VERSION ""

NS_ :

BS_:

BU_: VMCU TECU TACHO RECU_Virt IC3 HPCU EMS EBS DACU CIOM BBM ACM

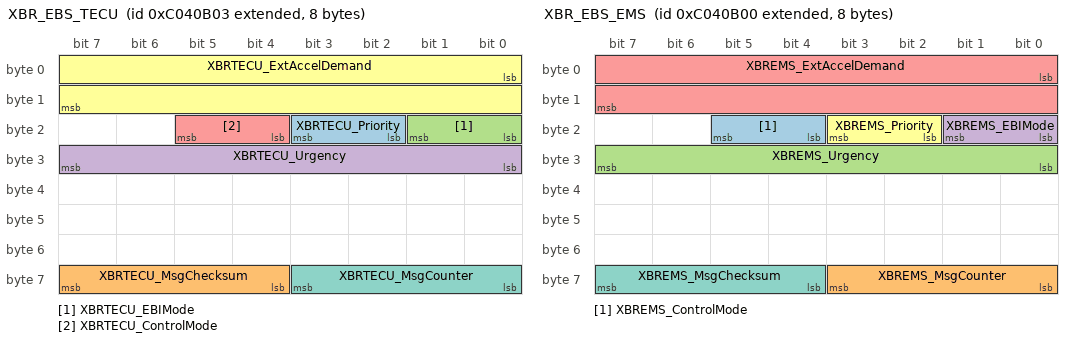
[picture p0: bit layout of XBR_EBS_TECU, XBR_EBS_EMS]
BO_ 2349075203 XBR_EBS_TECU: 8 TECU
 SG_ XBRTECU_Priority : 18|2@1+ (1,0) [0|0] ""  EBS,VMCU
 SG_ XBRTECU_MsgChecksum : 60|4@1+ (1,0) [0|15] "Count"  VMCU,EBS
 SG_ XBRTECU_EBIMode : 16|2@1+ (1,0) [0|0] ""  EBS,VMCU
 SG_ XBRTECU_Urgency : 24|8@1+ (0.4,0) [0|102] "Percent"  EBS,VMCU
 SG_ XBRTECU_ControlMode : 20|2@1+ (1,0) [0|0] ""  EBS,VMCU
 SG_ XBRTECU_ExtAccelDemand : 0|16@1+ (0.00048828125,-15.687) [-15.687|16.31251171875] "m_per_s_squared"  VMCU,EBS
 SG_ XBRTECU_MsgCounter : 56|4@1+ (1,0) [0|15] "Count"  EBS,VMCU

BO_ 2349075200 XBR_EBS_EMS: 8 EMS
 SG_ XBREMS_ControlMode : 20|2@1+ (1,0) [0|0] ""  EBS,VMCU
 SG_ XBREMS_MsgCounter : 56|4@1+ (1,0) [0|15] "Count"  EBS,VMCU
 SG_ XBREMS_Urgency : 24|8@1+ (0.4,0) [0|102] "Percent"  EBS,VMCU
 SG_ XBREMS_EBIMode : 16|2@1+ (1,0) [0|0] ""  EBS,VMCU
 SG_ XBREMS_ExtAccelDemand : 0|16@1+ (0.00048828125,-15.687) [-15.687|16.31251171875] "m_per_s_squared"  VMCU,EBS
 SG_ XBREMS_Priority : 18|2@1+ (1,0) [0|0] ""  EBS,VMCU
 SG_ XBREMS_MsgChecksum : 60|4@1+ (1,0) [0|15] "Count"  EBS,VMCU

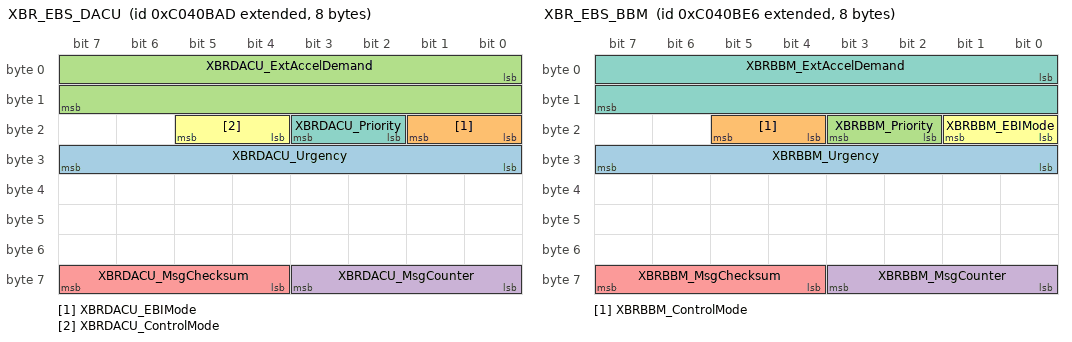
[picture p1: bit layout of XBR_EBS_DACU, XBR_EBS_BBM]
BO_ 2349075373 XBR_EBS_DACU: 8 DACU
 SG_ XBRDACU_Urgency : 24|8@1+ (0.4,0) [0|102] "Percent"  EBS,VMCU,TECU
 SG_ XBRDACU_EBIMode : 16|2@1+ (1,0) [0|0] ""  VMCU,EBS,TECU
 SG_ XBRDACU_ExtAccelDemand : 0|16@1+ (0.00048828125,-15.687) [-15.687|16.31251171875] "m_per_s_squared"  EBS,TECU,VMCU
 SG_ XBRDACU_MsgCounter : 56|4@1+ (1,0) [0|15] "Count"  VMCU,TECU,EBS
 SG_ XBRDACU_MsgChecksum : 60|4@1+ (1,0) [0|15] "Count"  TECU,VMCU,EBS
 SG_ XBRDACU_ControlMode : 20|2@1+ (1,0) [0|0] ""  TECU,EBS,VMCU
 SG_ XBRDACU_Priority : 18|2@1+ (1,0) [0|0] ""  EBS,TECU,VMCU

BO_ 2349075430 XBR_EBS_BBM: 8 BBM
 SG_ XBRBBM_Urgency : 24|8@1+ (0.4,0) [0|102] "Percent"  EBS,VMCU
 SG_ XBRBBM_ControlMode : 20|2@1+ (1,0) [0|0] ""  EBS,VMCU
 SG_ XBRBBM_Priority : 18|2@1+ (1,0) [0|0] ""  VMCU,EBS
 SG_ XBRBBM_MsgCounter : 56|4@1+ (1,0) [0|15] "Count"  VMCU,EBS
 SG_ XBRBBM_MsgChecksum : 60|4@1+ (1,0) [0|15] "Count"  VMCU,EBS
 SG_ XBRBBM_EBIMode : 16|2@1+ (1,0) [0|0] ""  EBS,VMCU
 SG_ XBRBBM_ExtAccelDemand : 0|16@1+ (0.00048828125,-15.687) [-15.687|16.31251171875] "m_per_s_squared"  VMCU,EBS

BO_ 2566848256 WFI_X_EMS: 8 EMS
 SG_ WaterInFuelAlarm_ISig_3 : 0|2@1+ (1,0) [0|0] ""  BBM,IC3

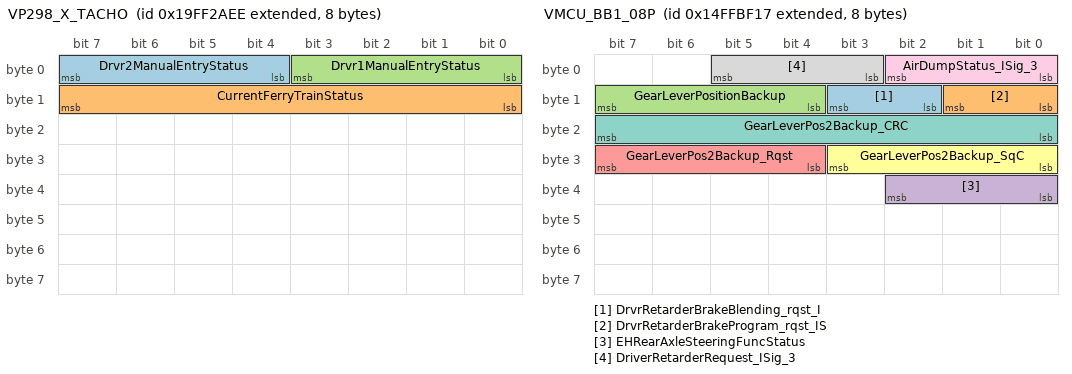
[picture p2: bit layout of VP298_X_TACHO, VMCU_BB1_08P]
BO_ 2583636718 VP298_X_TACHO: 8 TACHO
 SG_ Drvr2ManualEntryStatus : 4|4@1+ (1,0) [0|0] ""  IC3
 SG_ CurrentFerryTrainStatus : 8|8@1+ (1,0) [0|0] ""  IC3
 SG_ Drvr1ManualEntryStatus : 0|4@1+ (1,0) [0|0] ""  IC3

BO_ 2583635694 VP294_X_TACHO: 8 TACHO
 SG_ GNSSTime_Tacho : 0|32@1+ (1,0) [0|4294967295] "s"  VMCU
 SG_ GNSSLiveStatus_Tacho : 32|8@1+ (1,0) [0|255] "NotApplicable"  VMCU

BO_ 2566845201 VP1_X_VMCU: 8 VMCU
 SG_ VehiclePosSAE_Longitude : 32|32@1+ (1E-007,-210) [-210|219.4967295] "deg"  TECU
 SG_ VehiclePosSAE_Latitude : 0|32@1+ (1E-007,-210) [-210|219.4967295] "deg"  TECU

BO_ 2566845422 VP1_X_TACHO: 8 TACHO
 SG_ VehPos1_Latitude : 0|32@1+ (1E-007,-210) [-210|219.4967295] "deg"  VMCU
 SG_ VehPos1_Longitude : 32|32@1+ (1E-007,-210) [-210|219.4967295] "deg"  VMCU

BO_ 2566901009 VMCU_BB1_09P: 8 VMCU
 SG_ LNGConsumedPTO : 0|32@1+ (0.01,0) [0|42949672.95] "kg"  IC3
 SG_ EngTrueIdleSpeedLNG : 32|32@1+ (0.01,0) [0|42949672.95] "kg"  IC3

BO_ 2499788567 VMCU_BB1_08P: 8 VMCU
 SG_ DrvrRetarderBrakeBlending_rqst_I : 10|2@1+ (1,0) [0|0] ""  TECU,BBM,EBS,IC3
 SG_ DrvrRetarderBrakeProgram_rqst_IS : 8|2@1+ (1,0) [0|0] ""  IC3,TECU,BBM
 SG_ GearLeverPositionBackup : 12|4@1+ (1,0) [0|0] ""  TECU
 SG_ EHRearAxleSteeringFuncStatus : 32|3@1+ (1,0) [0|0] ""  CIOM
 SG_ GearLeverPos2Backup_Rqst : 28|4@1+ (1,0) [0|0] ""  TECU
 SG_ GearLeverPos2Backup_SqC : 24|4@1+ (1,0) [0|0] ""  TECU
 SG_ GearLeverPos2Backup_CRC : 16|8@1+ (1,0) [0|255] ""  TECU
 SG_ DriverRetarderRequest_ISig_3 : 3|3@1+ (1,0) [0|0] ""  EBS,TECU,EMS,IC3,BBM,RECU_Virt
 SG_ AirDumpStatus_ISig_3 : 0|3@1+ (1,0) [0|0] ""  BBM

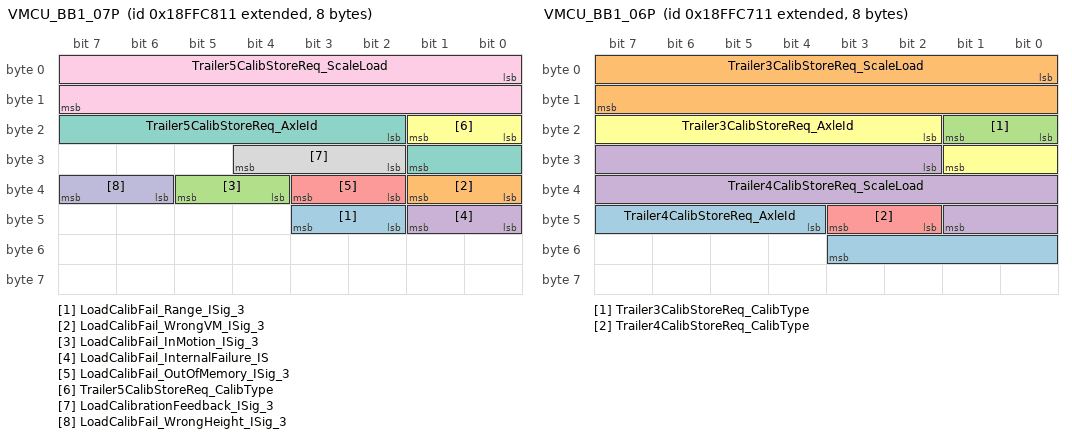
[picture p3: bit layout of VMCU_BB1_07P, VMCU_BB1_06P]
BO_ 2566899729 VMCU_BB1_07P: 8 VMCU
 SG_ LoadCalibFail_Range_ISig_3 : 42|2@1+ (1,0) [0|0] ""  IC3
 SG_ LoadCalibFail_WrongVM_ISig_3 : 32|2@1+ (1,0) [0|0] ""  IC3
 SG_ LoadCalibFail_InMotion_ISig_3 : 36|2@1+ (1,0) [0|0] ""  IC3
 SG_ LoadCalibFail_InternalFailure_IS : 40|2@1+ (1,0) [0|0] ""  IC3
 SG_ LoadCalibFail_OutOfMemory_ISig_3 : 34|2@1+ (1,0) [0|0] ""  IC3
 SG_ Trailer5CalibStoreReq_CalibType : 16|2@1+ (1,0) [0|0] ""  EBS
 SG_ Trailer5CalibStoreReq_AxleId : 18|8@1+ (1,0) [0|255] "NotApplicable"  EBS
 SG_ LoadCalibrationFeedback_ISig_3 : 26|3@1+ (1,0) [0|0] ""  IC3
 SG_ Trailer5CalibStoreReq_ScaleLoad : 0|16@1+ (1,0) [0|65535] "kg"  EBS
 SG_ LoadCalibFail_WrongHeight_ISig_3 : 38|2@1+ (1,0) [0|0] ""  IC3

BO_ 2566899473 VMCU_BB1_06P: 8 VMCU
 SG_ Trailer4CalibStoreReq_AxleId : 44|8@1+ (1,0) [0|255] "NotApplicable"  EBS
 SG_ Trailer3CalibStoreReq_ScaleLoad : 0|16@1+ (1,0) [0|65535] "kg"  EBS
 SG_ Trailer3CalibStoreReq_CalibType : 16|2@1+ (1,0) [0|0] ""  EBS
 SG_ Trailer4CalibStoreReq_ScaleLoad : 26|16@1+ (1,0) [0|65535] "kg"  EBS
 SG_ Trailer4CalibStoreReq_CalibType : 42|2@1+ (1,0) [0|0] ""  EBS
 SG_ Trailer3CalibStoreReq_AxleId : 18|8@1+ (1,0) [0|255] "NotApplicable"  EBS

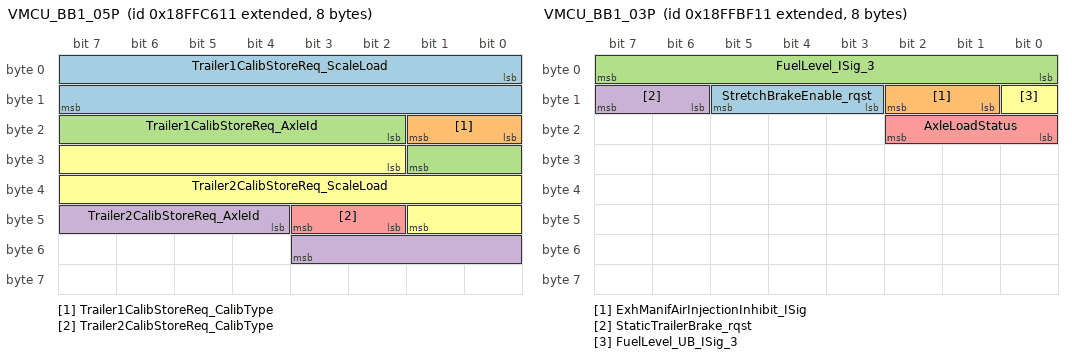
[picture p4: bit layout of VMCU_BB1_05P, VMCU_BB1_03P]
BO_ 2566899217 VMCU_BB1_05P: 8 VMCU
 SG_ Trailer1CalibStoreReq_ScaleLoad : 0|16@1+ (1,0) [0|65535] "kg"  EBS
 SG_ Trailer1CalibStoreReq_CalibType : 16|2@1+ (1,0) [0|0] ""  EBS
 SG_ Trailer1CalibStoreReq_AxleId : 18|8@1+ (1,0) [0|255] "NotApplicable"  EBS
 SG_ Trailer2CalibStoreReq_AxleId : 44|8@1+ (1,0) [0|255] "NotApplicable"  EBS
 SG_ Trailer2CalibStoreReq_CalibType : 42|2@1+ (1,0) [0|0] ""  EBS
 SG_ Trailer2CalibStoreReq_ScaleLoad : 26|16@1+ (1,0) [0|65535] "kg"  EBS

BO_ 2499751697 VMCU_BB1_04P: 8 VMCU
 SG_ TrailerConnected_UB_ISig_3 : 23|1@1+ (1,0) [0|0] ""  EBS
 SG_ RearAxle2DiffLock_stat_ISig_3 : 2|2@1+ (1,0) [0|0] ""  BBM,TECU,IC3
 SG_ EngineStopReqBackup : 12|2@1+ (1,0) [0|0] ""  EMS
 SG_ DifferentialLockStateCentral_ISi : 6|2@1+ (1,0) [0|0] ""  BBM,TECU,EBS,IC3,EMS
 SG_ RearAxle2DiffLock_stat_UB_ISig_3 : 17|1@1+ (1,0) [0|0] ""  BBM,TECU,IC3
 SG_ RrInterAxlDiffLockActvnFuncReq_I : 46|2@1+ (1,0) [0|0] ""  IC3
 SG_ RearPropulsionStat_Rear1Axle_ISi : 24|4@1+ (1,0) [0|0] ""  IC3,EBS,EMS,TECU,BBM,DACU
 SG_ SetHSAOperation : 40|3@1+ (1,0) [0|0] ""  IC3,EBS
 SG_ CentralRearDiffLock_stat_ISig_3 : 4|2@1+ (1,0) [0|0] ""  IC3,TECU,BBM
 SG_ AutoPBRelease_stat_ISig_3 : 36|2@1+ (1,0) [0|0] ""  IC3
 SG_ RearAxle3DiffLock_stat_ISig_3 : 50|2@1+ (1,0) [0|0] ""  IC3
 SG_ DifferentialLockStateCentral2 : 48|2@1+ (1,0) [0|0] ""  EBS
 SG_ LowAirPressureAlert : 10|2@1+ (1,0) [0|0] ""  IC3,EMS
 SG_ RearPropulsionStat_Rear3Axle_ISi : 32|4@1+ (1,0) [0|0] ""  DACU,IC3,EMS,BBM,EBS,TECU
 SG_ RearAxle3DiffLock_stat_UB_ISig_3 : 52|1@1+ (1,0) [0|0] ""  IC3
 SG_ DifferentialLockStateFrAxle2 : 38|2@1+ (1,0) [0|0] ""  EBS
 SG_ TrailerConnected_ISig_3 : 21|2@1+ (1,0) [0|0] ""  EBS
 SG_ TrailerWithoutABS_ISig_3 : 18|2@1+ (1,0) [0|0] ""  TECU,EMS,DACU,EBS,IC3
 SG_ DifferentialLockStateFrAxle1_UB_ : 14|1@1+ (1,0) [0|0] ""  BBM,EBS,IC3
 SG_ DifferentialLockStateFrAxle1_ISi : 8|2@1+ (1,0) [0|0] ""  EBS,IC3,BBM
 SG_ RearAxle1DiffLock_stat_UB_ISig_3 : 16|1@1+ (1,0) [0|0] ""  BBM,TECU,IC3
 SG_ RearPropulsionStat_Rear2Axle_ISi : 28|4@1+ (1,0) [0|0] ""  EBS,BBM,EMS,IC3,DACU,TECU
 SG_ CentralRearDiffLock_stat_UB_ISig : 15|1@1+ (1,0) [0|0] ""  IC3,BBM,TECU
 SG_ RearAxle1DiffLock_stat_ISig_3 : 0|2@1+ (1,0) [0|0] ""  IC3,BBM,TECU
 SG_ HeadlampFan_stat_ISig_3 : 43|3@1+ (1,0) [0|0] ""  IC3
 SG_ TrailerWithoutABS_UB_ISig_3 : 20|1@1+ (1,0) [0|0] ""  TECU,DACU,EBS,EMS,IC3

BO_ 2566897425 VMCU_BB1_03P: 8 VMCU
 SG_ StretchBrakeEnable_rqst : 11|3@1+ (1,0) [0|0] ""  EBS
 SG_ ExhManifAirInjectionInhibit_ISig : 9|2@1+ (1,0) [0|0] ""  EMS
 SG_ FuelLevel_ISig_3 : 0|8@1+ (0.4,0) [0|102] "Percent"  IC3,BBM,CIOM,EMS
 SG_ StaticTrailerBrake_rqst : 14|2@1+ (1,0) [0|0] ""  EBS
 SG_ AxleLoadStatus : 16|3@1+ (1,0) [0|0] ""  IC3,TECU,EBS
 SG_ FuelLevel_UB_ISig_3 : 8|1@1+ (1,0) [0|0] ""  BBM,IC3,CIOM,EMS

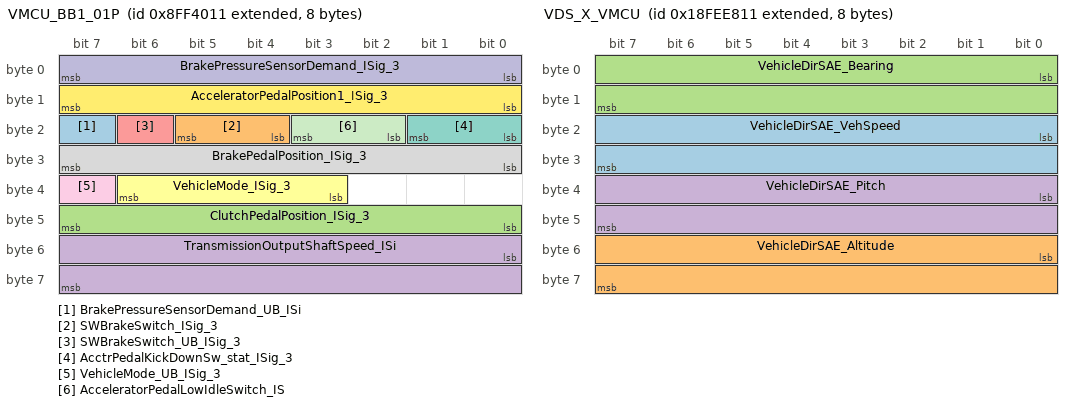
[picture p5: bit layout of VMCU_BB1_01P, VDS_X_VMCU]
BO_ 2298429457 VMCU_BB1_01P: 8 VMCU
 SG_ BrakePressureSensorDemand_UB_ISi : 23|1@1+ (1,0) [0|0] ""  EBS
 SG_ SWBrakeSwitch_ISig_3 : 20|2@1+ (1,0) [0|0] ""  IC3,EBS
 SG_ ClutchPedalPosition_ISig_3 : 40|8@1+ (0.4,0) [0|102] "Percent"  EBS
 SG_ TransmissionOutputShaftSpeed_ISi : 48|16@1+ (0.125,0) [0|8191.875] "rpm"  RECU_Virt,EMS,BBM
 SG_ SWBrakeSwitch_UB_ISig_3 : 22|1@1+ (1,0) [0|0] ""  IC3,EBS
 SG_ VehicleMode_ISig_3 : 35|4@1+ (1,0) [0|0] ""  ACM,IC3,CIOM,DACU,HPCU,TECU,TACHO,EMS,BBM,EBS
 SG_ AcctrPedalKickDownSw_stat_ISig_3 : 16|2@1+ (1,0) [0|0] ""  BBM,TECU,IC3,EMS,DACU
 SG_ BrakePedalPosition_ISig_3 : 24|8@1+ (0.4,0) [0|102] "Percent"  IC3,TECU,EBS,CIOM,DACU,BBM
 SG_ VehicleMode_UB_ISig_3 : 39|1@1+ (1,0) [0|0] ""  HPCU,EMS,CIOM,IC3,DACU,TECU,ACM,TACHO,BBM,EBS
 SG_ BrakePressureSensorDemand_ISig_3 : 0|8@1+ (1,0) [0|255] "Percent"  EBS
 SG_ AcceleratorPedalLowIdleSwitch_IS : 18|2@1+ (1,0) [0|0] ""  IC3,BBM,TECU
 SG_ AcceleratorPedalPosition1_ISig_3 : 8|8@1+ (0.4,0) [0|102] "Percent"  EMS,BBM,DACU,EBS,IC3,TECU,CIOM

BO_ 2566842385 VDS_X_VMCU: 8 VMCU
 SG_ VehicleDirSAE_VehSpeed : 16|16@1+ (0.00390625,0) [0|255.99609375] "Km_per_h"  TECU
 SG_ VehicleDirSAE_Altitude : 48|16@1+ (0.125,-2500) [-2500|5691.875] "m"  TECU
 SG_ VehicleDirSAE_Bearing : 0|16@1+ (0.0078125,0) [0|511.9921875] "deg"  TECU
 SG_ VehicleDirSAE_Pitch : 32|16@1+ (0.0078125,-200) [-200|311.9921875] "deg"  TECU

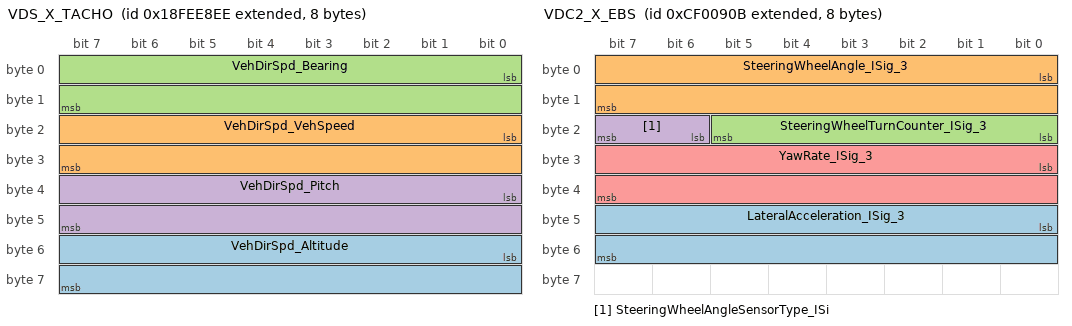
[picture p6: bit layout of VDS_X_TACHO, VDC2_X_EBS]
BO_ 2566842606 VDS_X_TACHO: 8 TACHO
 SG_ VehDirSpd_Altitude : 48|16@1+ (0.125,-2500) [-2500|5691.875] "m"  VMCU
 SG_ VehDirSpd_VehSpeed : 16|16@1+ (0.00390625,0) [0|255.99609375] "Km_per_h"  VMCU
 SG_ VehDirSpd_Bearing : 0|16@1+ (0.0078125,0) [0|511.9921875] "deg"  VMCU
 SG_ VehDirSpd_Pitch : 32|16@1+ (0.0078125,-200) [-200|311.9921875] "deg"  VMCU

BO_ 2566849262 VDO2_X_TACHO: 32 TACHO
 SG_ DurationOfCurrentDailyRest_ISig_ : 80|16@1+ (1,0) [0|65535] "min"  IC3
 SG_ DetectReducWeeklyRestsForCurWk_I : 116|4@1+ (1,0) [0|0] ""  IC3
 SG_ CurrentWeekWorkTime_ISig_3 : 144|16@1+ (1,0) [0|65535] "min"  IC3
 SG_ DetectRegWeeklyRestsForCurWk_ISi : 112|4@1+ (1,0) [0|0] ""  IC3
 SG_ Drv1CumulativeBreakTime_VDO2_ISi : 64|16@1+ (1,0) [0|65535] "min"  IC3
 SG_ Drv1ContinuousDrivingTime_VDO2_I : 0|16@1+ (1,0) [0|65535] "min"  IC3
 SG_ DailyDrivingTime_VDO2_ISig_3 : 16|16@1+ (1,0) [0|65535] "min"  IC3
 SG_ DetectReducWeeklyRestsForLastW_I : 124|4@1+ (1,0) [0|0] ""  IC3
 SG_ TwoWeekDrvingTime_VDO2_ISig_3 : 32|16@1+ (1,0) [0|65535] "min"  IC3
 SG_ CurrentDailyWorkTime_ISig_3 : 128|16@1+ (1,0) [0|65535] "min"  IC3
 SG_ DetectRegWeeklyRestsForLastW_ISi : 120|4@1+ (1,0) [0|0] ""  IC3
 SG_ WeeklyDrivingTime_VDO2_ISig_3 : 48|16@1+ (1,0) [0|65535] "min"  IC3
 SG_ DurationOfCurrentWeeklyRest_ISig : 96|16@1+ (1,0) [0|65535] "min"  IC3

BO_ 2566906094 VDO1prop_X_TACHO: 32 TACHO
 SG_ RemningTimeTillNxtWklyRestPrd_IS : 160|16@1+ (1,0) [0|65535] "min"  IC3
 SG_ RemainingCurDailyDrivingTime_ISi : 96|16@1+ (1,0) [0|65535] "min"  IC3
 SG_ RemainingCurrentDrivingTime_ISig : 0|16@1+ (1,0) [0|65535] "min"  IC3
 SG_ SingleMultiDriver_ISig_3 : 252|2@1+ (1,0) [0|0] ""  IC3
 SG_ UnknownPeriods_ISig_3 : 246|2@1+ (1,0) [0|0] ""  IC3
 SG_ OpenCompensationWeekBfrLast_ISig : 208|16@1+ (1,0) [0|65535] "min"  IC3
 SG_ RemainingReducedDailyRestPrd_ISi : 243|3@1+ (1,0) [0|0] ""  IC3
 SG_ RemainingDurOfCurBreakRest_ISig_ : 48|16@1+ (1,0) [0|65535] "min"  IC3
 SG_ RemainingTimeTillNextRestBreak_I : 16|16@1+ (1,0) [0|65535] "min"  IC3
 SG_ NextDrivingPeriod_ISig_3 : 80|16@1+ (1,0) [0|65535] "min"  IC3
 SG_ DurationOfNextRestBreak_ISig_3 : 32|16@1+ (1,0) [0|65535] "min"  IC3
 SG_ RemainingDrivTimeOfCurWeek_ISig_ : 144|16@1+ (1,0) [0|65535] "min"  IC3
 SG_ DurationOfNextDailyRestPeriod_IS : 128|16@1+ (1,0) [0|65535] "min"  IC3
 SG_ OpenCompensationInTheLastWeek_IS : 192|16@1+ (1,0) [0|65535] "min"  IC3
 SG_ TimeOverlap_ISig_3 : 254|2@1+ (1,0) [0|0] ""  IC3
 SG_ TimeBeforeStartOfNxtDrvngPrd_ISi : 64|16@1+ (1,0) [0|65535] "min"  IC3
 SG_ WklyRestPrdCalcEnabledDisabled_I : 250|2@1+ (1,0) [0|0] ""  IC3
 SG_ Remaining10hDrvTime_ISig_3 : 240|3@1+ (1,0) [0|0] ""  IC3
 SG_ RemnngTimeTillNxtDailyRestPrd_IS : 112|16@1+ (1,0) [0|65535] "min"  IC3
 SG_ DurationOfNextWeeklyRestPeriod_I : 176|16@1+ (1,0) [0|65535] "min"  IC3
 SG_ OpenCompensation2ndWeekBfrLast_I : 224|16@1+ (1,0) [0|65535] "min"  IC3
 SG_ SufficientData_ISig_3 : 248|2@1+ (1,0) [0|0] ""  IC3

BO_ 2566849006 VDO1Extended_X_TACHO: 16 TACHO
 SG_ TypeOfNextBreakRest_ISig_3 : 16|6@1+ (1,0) [0|0] ""  IC3
 SG_ CompensationinNextRestPrd_ISig_3 : 22|2@1+ (1,0) [0|0] ""  IC3
 SG_ RemDrvTimeTillNxtWklyRestPrd_ISi : 0|16@1+ (1,0) [0|65535] "min"  IC3

BO_ 2566832401 VDHR_X_VMCU: 8 VMCU
 SG_ TotalVehicleDistanceHighRes_ISig : 0|32@1+ (5,0) [0|21474836475] "m"  IC3,EBS,EMS,ACM,DACU,TECU,CIOM,BBM

BO_ 2566832622 VDHR_X_TACHO: 8 TACHO
 SG_ TachoHighResTotalVehDistance : 0|32@1+ (5,0) [0|21474836475] "m"  VMCU

BO_ 2566832407 VDHR_X_IC3: 8 IC3
 SG_ HighResolutionTripDistance_ISig_ : 32|32@1+ (5,0) [0|21474836475] "m"  BBM

BO_ 2364541195 VDC2_X_EBS: 8 EBS
 SG_ LateralAcceleration_ISig_3 : 40|16@1+ (0.00048828125,-15.687) [-15.687|16.31251171875] "m_per_s_squared"  IC3,BBM,DACU
 SG_ SteeringWheelAngle_ISig_3 : 0|16@1+ (0.0009765625,-31.374) [-31.374|32.6250234375] "rad"  CIOM,BBM,IC3,VMCU,DACU
 SG_ SteeringWheelTurnCounter_ISig_3 : 16|6@1+ (1,-32) [-32|31] "turns"  BBM
 SG_ SteeringWheelAngleSensorType_ISi : 22|2@1+ (1,0) [0|0] ""  BBM
 SG_ YawRate_ISig_3 : 24|16@1+ (0.000122,-3.92) [-3.92|4.07527] "Rad_per_s"  IC3,TECU,BBM,DACU

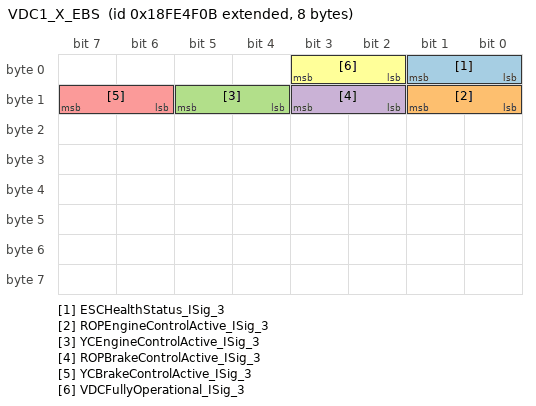
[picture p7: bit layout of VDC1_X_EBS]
BO_ 2566803211 VDC1_X_EBS: 8 EBS
 SG_ ESCHealthStatus_ISig_3 : 0|2@1+ (1,0) [0|0] ""  IC3,BBM
 SG_ ROPEngineControlActive_ISig_3 : 8|2@1+ (1,0) [0|0] ""  VMCU,IC3,BBM,TECU
 SG_ YCEngineControlActive_ISig_3 : 12|2@1+ (1,0) [0|0] ""  IC3,VMCU,BBM,TECU
 SG_ ROPBrakeControlActive_ISig_3 : 10|2@1+ (1,0) [0|0] ""  TECU,VMCU,CIOM,DACU,BBM,IC3
 SG_ YCBrakeControlActive_ISig_3 : 14|2@1+ (1,0) [0|0] ""  IC3,DACU,BBM,TECU,VMCU,CIOM
 SG_ VDCFullyOperational_ISig_3 : 2|2@1+ (1,0) [0|0] ""  BBM,DACU

BO_ 2675897544 TrailerDiagPhysRespMsg_F4_C8_BB1: 8 EBS
 SG_ TrailerDiagPhysResp_F4_C8_ISig_3 : 0|8@1- (1,0) [0|0] ""  IC3

BO_ 2675897536 TrailerDiagPhysRespMsg_F4_C0_BB1: 8 EBS
 SG_ TrailerDiagPhysResp_F4_C0_ISig_3 : 0|8@1- (1,0) [0|0] ""  IC3

BO_ 2675897528 TrailerDiagPhysRespMsg_F4_B8_BB1: 8 EBS
 SG_ TrailerDiagPhysResp_F4_B8_ISig_3 : 0|8@1- (1,0) [0|0] ""  IC3

BO_ 2675897520 TrailerDiagPhysRespMsg_F4_B0_BB1: 8 EBS
 SG_ TrailerDiagPhysResp_F4_B0_ISig_3 : 0|8@1- (1,0) [0|0] ""  IC3

BO_ 2675897512 TrailerDiagPhysRespMsg_F4_A8_BB1: 8 EBS
 SG_ TrailerDiagPhysResp_F4_A8_ISig_3 : 0|8@1- (1,0) [0|0] ""  IC3

BO_ 2675897032 TrailerDiagPhysRespMsg_F2_C8_BB1: 8 EBS
 SG_ TrailerDiagPhysResp_F2_C8_ISig_3 : 0|8@1- (1,0) [0|0] ""  VMCU

BO_ 2675897024 TrailerDiagPhysRespMsg_F2_C0_BB1: 8 EBS
 SG_ TrailerDiagPhysResp_F2_C0_ISig_3 : 0|8@1- (1,0) [0|0] ""  VMCU

CM_ "COM_MATRIX_T2_1.16.0";
CM_ BO_ 2349075203 "PGN 1024 External Brake Request";
CM_ SG_ 2349075203 XBRTECU_Urgency "254 Error ; 255 Not available";
CM_ SG_ 2349075203 XBRTECU_ExtAccelDemand "65024 - 65279 Error ; 65280 - 65535 Not available";
CM_ BO_ 2349075200 "PGN 1024 External Brake Request";
CM_ BO_ 2349075373 "PGN 1024 External Brake Request";
CM_ SG_ 2349075373 XBRDACU_Urgency "254 Error ; 255 Not available";
CM_ SG_ 2349075373 XBRDACU_ExtAccelDemand "65024 - 65279 Error ; 65280 - 65535 Not available";
CM_ BO_ 2349075430 "PGN 1024 External Brake Request";
CM_ SG_ 2349075430 XBRBBM_Urgency "254 Error ; 255 Not available";
CM_ SG_ 2349075430 XBRBBM_ExtAccelDemand "65024 - 65279 Error ; 65280 - 65535 Not available";
CM_ BO_ 2566848256 "PGN 65279 Water in Fuel Indicator";
CM_ BO_ 2566845201 "PGN 65267 Vehicle Position";
CM_ SG_ 2566897425 FuelLevel_ISig_3 "254 Error ; 255 Not available";
CM_ SG_ 2298429457 ClutchPedalPosition_ISig_3 "254 Error ; 255 Not available";
CM_ SG_ 2298429457 TransmissionOutputShaftSpeed_ISi "65024 - 65279 Error ; 65280 - 65535 Not available";
CM_ SG_ 2298429457 BrakePedalPosition_ISig_3 "254 Error ; 255 Not available";
CM_ SG_ 2298429457 BrakePressureSensorDemand_ISig_3 "254 Error ; 255 Not available";
CM_ SG_ 2298429457 AcceleratorPedalPosition1_ISig_3 "254 Error ; 255 Not available";
CM_ BO_ 2566842385 "PGN 65256 Vehicle Direction/Speed";
CM_ SG_ 2566906094 RemningTimeTillNxtWklyRestPrd_IS "65024 - 65279 Error ; 65280 - 65535 Not available";
CM_ SG_ 2566906094 RemainingCurDailyDrivingTime_ISi "65024 - 65279 Error ; 65280 - 65535 Not available";
CM_ SG_ 2566906094 RemainingCurrentDrivingTime_ISig "65024 - 65279 Error ; 65280 - 65535 Not available";
CM_ SG_ 2566906094 OpenCompensationWeekBfrLast_ISig "65024 - 65279 Error ; 65280 - 65535 Not available";
CM_ SG_ 2566906094 RemainingDurOfCurBreakRest_ISig_ "65024 - 65279 Error ; 65280 - 65535 Not available";
CM_ SG_ 2566906094 RemainingTimeTillNextRestBreak_I "65024 - 65279 Error ; 65280 - 65535 Not available";
CM_ SG_ 2566906094 NextDrivingPeriod_ISig_3 "65024 - 65279 Error ; 65280 - 65535 Not available";
CM_ SG_ 2566906094 DurationOfNextRestBreak_ISig_3 "65024 - 65279 Error ; 65280 - 65535 Not available";
CM_ SG_ 2566906094 RemainingDrivTimeOfCurWeek_ISig_ "65024 - 65279 Error ; 65280 - 65535 Not available";
CM_ SG_ 2566906094 DurationOfNextDailyRestPeriod_IS "65024 - 65279 Error ; 65280 - 65535 Not available";
CM_ SG_ 2566906094 OpenCompensationInTheLastWeek_IS "65024 - 65279 Error ; 65280 - 65535 Not available";
CM_ SG_ 2566906094 TimeBeforeStartOfNxtDrvngPrd_ISi "65024 - 65279 Error ; 65280 - 65535 Not available";
CM_ SG_ 2566906094 RemnngTimeTillNxtDailyRestPrd_IS "65024 - 65279 Error ; 65280 - 65535 Not available";
CM_ SG_ 2566906094 DurationOfNextWeeklyRestPeriod_I "65024 - 65279 Error ; 65280 - 65535 Not available";
CM_ SG_ 2566906094 OpenCompensation2ndWeekBfrLast_I "65024 - 65279 Error ; 65280 - 65535 Not available";
CM_ BO_ 2566832401 "PGN 65217 High Resolution Vehicle Distance";
CM_ SG_ 2566832401 TotalVehicleDistanceHighRes_ISig "4261412864 - 4278190079 Error ; 4278190080 - 4294967295 Not available";
CM_ BO_ 2566832622 "PGN 65217 High Resolution Vehicle Distance, From TACHO";
CM_ SG_ 2566832622 TachoHighResTotalVehDistance "4261412864 - 4278190079 Error ; 4278190080 - 4294967295 Not available";
CM_ BO_ 2364541195 "PGN 61449 Vehicle Dynamic Stability Control 2";
CM_ SG_ 2364541195 LateralAcceleration_ISig_3 "65024 - 65279 Error ; 65280 - 65535 Not available";
CM_ SG_ 2364541195 SteeringWheelAngle_ISig_3 "65024 - 65279 Error ; 65280 - 65535 Not available";
CM_ SG_ 2364541195 SteeringWheelTurnCounter_ISig_3 "62 Error; 63 Not available";
CM_ SG_ 2364541195 YawRate_ISig_3 "65024 - 65279 Error ; 65280 - 65535 Not available";
CM_ BO_ 2566803211 "PGN 65103 Vehicle Dynamic Stability Control 1";
BA_DEF_ BO_  "GenMsgStartDelayTime" INT 0 0;
BA_DEF_ BO_  "GenMsgDelayTime" INT 0 0;
BA_DEF_ BO_  "GenMsgNrOfRepetition" INT 0 0;
BA_DEF_ BO_  "GenMsgCycleTimeFast" INT 0 0;
BA_DEF_ BO_  "GenMsgCycleTime" INT 0 0;
BA_DEF_ BO_  "GenMsgSendType" ENUM  "Cyclic","NotUsed","NotUsed","NotUsed","NotUsed","NotUsed","NotUsed","IfActive","NoMsgSendType","NotUsed";
BA_DEF_ SG_  "GenSigStartValue" INT 0 0;
BA_DEF_ SG_  "GenSigCycleTimeActive" INT 0 0;
BA_DEF_ SG_  "GenSigCycleTime" INT 0 0;
BA_DEF_ SG_  "GenSigSendType" ENUM  "Cyclic","OnWrite","OnWriteWithRepetition","OnChange","OnChangeWithRepetition","IfActive","IfActiveWithRepetition","NoSigSendType","NotUsed","NotUsed","NotUsed","NotUsed","NotUsed";
BA_DEF_  "Baudrate" INT 0 1000000;
BA_DEF_  "NmType" STRING ;
BA_DEF_  "Manufacturer" STRING ;
BA_DEF_  "VersionYear" INT 0 99;
BA_DEF_  "VersionNumber" INT 0 99;
BA_DEF_  "VersionMonth" INT 1 12;
BA_DEF_  "VersionDay" INT 1 31;
BA_DEF_ BO_  "VFrameFormat" ENUM  "StandardCAN","ExtendedCAN","reserved","J1939PG","reserved","reserved","reserved","reserved","reserved","reserved","reserved","reserved","reserved","reserved","StandardCAN_FD","ExtendedCAN_FD";
BA_DEF_ BU_  "TpOwnSystemEcuNumber" HEX 0 255;
BA_DEF_ BO_  "TpJ1939VarDlc" ENUM  "No","Yes";
BA_DEF_ SG_  "SigType" ENUM  "Default","Range","RangeSigned","ASCII","Discrete","Control","ReferencePGN","DTC","StringDelimiter","StringLength","StringLengthControl";
BA_DEF_ SG_  "SeToolVersion_SIGNAL" STRING ;
BA_DEF_ SG_  "SeToolUniqueID_SIGNAL" STRING ;
BA_DEF_ SG_  "SeToolOwnerSigGroup_SIGNAL" STRING ;
BA_DEF_ SG_  "SeToolOwnerSigGroupID_SIGNAL" STRING ;
BA_DEF_ SG_  "SeToolName_SIGNAL" STRING ;
BA_DEF_ SG_  "SeToolItemID_SIGNAL" STRING ;
BA_DEF_ SG_  "SeToolAncestorID_SIGNAL" STRING ;
BA_DEF_ SG_  "SPN" INT 0 524287;
BA_DEF_  "ProtocolType" STRING ;
BA_DEF_ SG_  "Platform_VMCU1_Sig" ENUM  "No","Yes";
BA_DEF_ SG_  "Platform_FactoryIf_Sig" ENUM  "No","Yes";
BA_DEF_ BU_  "NmStationAddress" INT 0 255;
BA_DEF_ BU_  "NmJ1939IdentityNumber" INT 0 2097151;
BA_DEF_  "NmAsrWaitBusSleepTime" INT 0 65535;
BA_DEF_  "NmAsrTimeoutTime" INT 0 65535;
BA_DEF_  "NmAsrRepeatMessageTime" INT 0 65535;
BA_DEF_ BU_  "NmAsrNodeIdentifier" HEX 0 253;
BA_DEF_ BU_  "NmAsrNode" ENUM  "No","Yes";
BA_DEF_  "NmAsrMessageCount" INT 1 256;
BA_DEF_  "NmAsrCanMsgCycleTime" INT 0 65535;
BA_DEF_  "NmAsrBaseAddress" HEX 0 536870911;
BA_DEF_ SG_  "NeedsUpdateBit" ENUM  "No","Yes";
BA_DEF_ BU_  "IsOBDrelevant" ENUM  "No","Yes";
BA_DEF_ SG_  "GenSigMaxLatency" INT 0 65535;
BA_DEF_ SG_  "GenSigILSupport" ENUM  "Yes","No";
BA_DEF_ BO_  "GenMsgILSupport" ENUM  "No","Yes";
BA_DEF_ BU_  "DiagnosticClientAddress" HEX 0 255;
BA_DEF_ BO_  "DiagUUDTResponse" ENUM  "No","Yes";
BA_DEF_ BO_  "DiagState" ENUM  "No","Yes";
BA_DEF_ BU_  "DiagRole" ENUM  "None","OBDTester","ExternalTester","InternalTester";
BA_DEF_ BO_  "DiagResponse" ENUM  "No","Yes";
BA_DEF_ BO_  "DiagRequest" ENUM  "No","Yes";
BA_DEF_ BO_  "DiagConnection" HEX 0 65535;
BA_DEF_  "DBName" STRING ;
BA_DEF_ BO_  "CanTpFcFrameId" HEX 0 2147483647;
BA_DEF_ BO_  "CanTpBs" INT 0 255;
BA_DEF_  "BusType" STRING ;
BA_DEF_ SG_  "SystemSignalLongSymbol" STRING ;
BA_DEF_REL_ BU_SG_REL_  "GenSigTimeoutTime" INT 0 65535;
BA_DEF_REL_ BU_SG_REL_  "GenSigFirstTimeoutTime" INT 0 65535;
BA_DEF_DEF_  "GenMsgStartDelayTime" 0;
BA_DEF_DEF_  "GenMsgDelayTime" 0;
BA_DEF_DEF_  "GenMsgNrOfRepetition" 0;
BA_DEF_DEF_  "GenMsgCycleTimeFast" 0;
BA_DEF_DEF_  "GenMsgCycleTime" 0;
BA_DEF_DEF_  "GenMsgSendType" "Cyclic";
BA_DEF_DEF_  "GenSigStartValue" 0;
BA_DEF_DEF_  "GenSigCycleTimeActive" 0;
BA_DEF_DEF_  "GenSigCycleTime" 0;
BA_DEF_DEF_  "GenSigSendType" "Cyclic";
BA_DEF_DEF_  "Baudrate" 500000;
BA_DEF_DEF_  "NmType" "";
BA_DEF_DEF_  "Manufacturer" "VOLVO_AB";
BA_DEF_DEF_  "VersionYear" 0;
BA_DEF_DEF_  "VersionNumber" 0;
BA_DEF_DEF_  "VersionMonth" 1;
BA_DEF_DEF_  "VersionDay" 1;
BA_DEF_DEF_  "VFrameFormat" "ExtendedCAN";
BA_DEF_DEF_  "TpOwnSystemEcuNumber" 0;
BA_DEF_DEF_  "TpJ1939VarDlc" "No";
BA_DEF_DEF_  "SigType" "Default";
BA_DEF_DEF_  "SeToolVersion_SIGNAL" "";
BA_DEF_DEF_  "SeToolUniqueID_SIGNAL" "";
BA_DEF_DEF_  "SeToolOwnerSigGroup_SIGNAL" "";
BA_DEF_DEF_  "SeToolOwnerSigGroupID_SIGNAL" "";
BA_DEF_DEF_  "SeToolName_SIGNAL" "";
BA_DEF_DEF_  "SeToolItemID_SIGNAL" "";
BA_DEF_DEF_  "SeToolAncestorID_SIGNAL" "";
BA_DEF_DEF_  "SPN" 0;
BA_DEF_DEF_  "ProtocolType" "";
BA_DEF_DEF_  "Platform_VMCU1_Sig" "No";
BA_DEF_DEF_  "Platform_FactoryIf_Sig" "No";
BA_DEF_DEF_  "NmStationAddress" 254;
BA_DEF_DEF_  "NmJ1939IdentityNumber" 0;
BA_DEF_DEF_  "NmAsrWaitBusSleepTime" 750;
BA_DEF_DEF_  "NmAsrTimeoutTime" 5000;
BA_DEF_DEF_  "NmAsrRepeatMessageTime" 300;
BA_DEF_DEF_  "NmAsrNodeIdentifier" 0;
BA_DEF_DEF_  "NmAsrNode" "Yes";
BA_DEF_DEF_  "NmAsrMessageCount" 256;
BA_DEF_DEF_  "NmAsrCanMsgCycleTime" 200;
BA_DEF_DEF_  "NmAsrBaseAddress" 486506496;
BA_DEF_DEF_  "NeedsUpdateBit" "No";
BA_DEF_DEF_  "IsOBDrelevant" "No";
BA_DEF_DEF_  "GenSigMaxLatency" 0;
BA_DEF_DEF_  "GenSigILSupport" "Yes";
BA_DEF_DEF_  "GenMsgILSupport" "Yes";
BA_DEF_DEF_  "DiagnosticClientAddress" 0;
BA_DEF_DEF_  "DiagUUDTResponse" "No";
BA_DEF_DEF_  "DiagState" "No";
BA_DEF_DEF_  "DiagRole" "None";
BA_DEF_DEF_  "DiagResponse" "No";
BA_DEF_DEF_  "DiagRequest" "No";
BA_DEF_DEF_  "DiagConnection" 0;
BA_DEF_DEF_  "DBName" "";
BA_DEF_DEF_  "CanTpFcFrameId" 2147483647;
BA_DEF_DEF_  "CanTpBs" 255;
BA_DEF_DEF_  "BusType" "";
BA_DEF_DEF_REL_ "GenSigTimeoutTime" 0;
BA_DEF_DEF_REL_ "GenSigFirstTimeoutTime" 0;
BA_DEF_DEF_  "SystemSignalLongSymbol" "";
BA_ "BusType" "CAN";
BA_ "ProtocolType" "J1939";
BA_ "VersionDay" 23;
BA_ "VersionNumber" 1;
BA_ "VersionYear" 20;
BA_ "DBName" "Backbone1J1939";
BA_ "IsOBDrelevant" BU_ VMCU 1;
BA_ "TpOwnSystemEcuNumber" BU_ VMCU 36;
BA_ "NmAsrNode" BU_ VMCU 0;
BA_ "NmAsrNodeIdentifier" BU_ VMCU 17;
BA_ "NmJ1939IdentityNumber" BU_ VMCU 17;
BA_ "NmStationAddress" BU_ VMCU 17;
BA_ "TpOwnSystemEcuNumber" BU_ TECU 24;
BA_ "NmAsrNode" BU_ TECU 0;
BA_ "NmAsrNodeIdentifier" BU_ TECU 3;
BA_ "NmJ1939IdentityNumber" BU_ TECU 3;
BA_ "NmStationAddress" BU_ TECU 3;
BA_ "TpOwnSystemEcuNumber" BU_ TACHO 238;
BA_ "NmAsrNode" BU_ TACHO 0;
BA_ "NmAsrNodeIdentifier" BU_ TACHO 238;
BA_ "NmJ1939IdentityNumber" BU_ TACHO 238;
BA_ "NmStationAddress" BU_ TACHO 238;
BA_ "TpOwnSystemEcuNumber" BU_ RECU_Virt 16;
BA_ "NmAsrNode" BU_ RECU_Virt 0;
BA_ "NmAsrNodeIdentifier" BU_ RECU_Virt 16;
BA_ "NmJ1939IdentityNumber" BU_ RECU_Virt 16;
BA_ "NmStationAddress" BU_ RECU_Virt 16;
BA_ "DiagRole" BU_ IC3 3;
BA_ "DiagnosticClientAddress" BU_ IC3 243;
BA_ "TpOwnSystemEcuNumber" BU_ IC3 97;
BA_ "NmAsrNode" BU_ IC3 0;
BA_ "NmAsrNodeIdentifier" BU_ IC3 23;
BA_ "NmJ1939IdentityNumber" BU_ IC3 23;
BA_ "NmStationAddress" BU_ IC3 23;
BA_ "TpOwnSystemEcuNumber" BU_ HPCU 239;
BA_ "NmAsrNode" BU_ HPCU 0;
BA_ "NmAsrNodeIdentifier" BU_ HPCU 239;
BA_ "NmJ1939IdentityNumber" BU_ HPCU 239;
BA_ "NmStationAddress" BU_ HPCU 239;
BA_ "IsOBDrelevant" BU_ EMS 1;
BA_ "TpOwnSystemEcuNumber" BU_ EMS 16;
BA_ "NmAsrNode" BU_ EMS 0;
BA_ "NmStationAddress" BU_ EMS 0;
BA_ "TpOwnSystemEcuNumber" BU_ EBS 40;
BA_ "NmAsrNode" BU_ EBS 0;
BA_ "NmAsrNodeIdentifier" BU_ EBS 11;
BA_ "NmJ1939IdentityNumber" BU_ EBS 11;
BA_ "NmStationAddress" BU_ EBS 11;
BA_ "TpOwnSystemEcuNumber" BU_ DACU 80;
BA_ "NmAsrNode" BU_ DACU 0;
BA_ "NmAsrNodeIdentifier" BU_ DACU 173;
BA_ "NmJ1939IdentityNumber" BU_ DACU 173;
BA_ "NmStationAddress" BU_ DACU 173;
BA_ "TpOwnSystemEcuNumber" BU_ CIOM 64;
BA_ "NmAsrNode" BU_ CIOM 0;
BA_ "NmAsrNodeIdentifier" BU_ CIOM 49;
BA_ "NmJ1939IdentityNumber" BU_ CIOM 49;
BA_ "NmStationAddress" BU_ CIOM 49;
BA_ "TpOwnSystemEcuNumber" BU_ BBM 230;
BA_ "NmAsrNode" BU_ BBM 0;
BA_ "NmAsrNodeIdentifier" BU_ BBM 230;
BA_ "NmJ1939IdentityNumber" BU_ BBM 230;
BA_ "NmStationAddress" BU_ BBM 230;
BA_ "IsOBDrelevant" BU_ ACM 1;
BA_ "TpOwnSystemEcuNumber" BU_ ACM 17;
BA_ "NmAsrNode" BU_ ACM 0;
BA_ "NmAsrNodeIdentifier" BU_ ACM 61;
BA_ "NmJ1939IdentityNumber" BU_ ACM 61;
BA_ "NmStationAddress" BU_ ACM 61;
BA_ "GenMsgSendType" BO_ 2349075203 8;
BA_ "GenMsgDelayTime" BO_ 2349075203 15;
BA_ "VFrameFormat" BO_ 2349075203 3;
BA_ "GenMsgSendType" BO_ 2349075200 8;
BA_ "GenMsgDelayTime" BO_ 2349075200 15;
BA_ "VFrameFormat" BO_ 2349075200 3;
BA_ "GenMsgSendType" BO_ 2349075373 8;
BA_ "GenMsgDelayTime" BO_ 2349075373 15;
BA_ "VFrameFormat" BO_ 2349075373 3;
BA_ "GenMsgSendType" BO_ 2349075430 8;
BA_ "GenMsgDelayTime" BO_ 2349075430 15;
BA_ "VFrameFormat" BO_ 2349075430 3;
BA_ "GenMsgCycleTime" BO_ 2566848256 10000;
BA_ "GenMsgStartDelayTime" BO_ 2566848256 2660;
BA_ "VFrameFormat" BO_ 2566848256 3;
BA_ "GenMsgCycleTime" BO_ 2583636718 5000;
BA_ "VFrameFormat" BO_ 2583636718 3;
BA_ "GenMsgCycleTime" BO_ 2583635694 500;
BA_ "GenMsgStartDelayTime" BO_ 2583635694 50;
BA_ "VFrameFormat" BO_ 2583635694 3;
BA_ "GenMsgCycleTime" BO_ 2566845201 250;
BA_ "GenMsgStartDelayTime" BO_ 2566845201 25;
BA_ "VFrameFormat" BO_ 2566845201 3;
BA_ "GenMsgCycleTime" BO_ 2566845422 500;
BA_ "VFrameFormat" BO_ 2566845422 3;
BA_ "GenMsgCycleTime" BO_ 2566901009 100;
BA_ "VFrameFormat" BO_ 2566901009 3;
BA_ "GenMsgCycleTime" BO_ 2499788567 75;
BA_ "GenMsgStartDelayTime" BO_ 2499788567 5;
BA_ "VFrameFormat" BO_ 2499788567 3;
BA_ "GenMsgCycleTime" BO_ 2566899729 1000;
BA_ "GenMsgStartDelayTime" BO_ 2566899729 250;
BA_ "VFrameFormat" BO_ 2566899729 3;
BA_ "GenMsgCycleTime" BO_ 2566899473 1000;
BA_ "GenMsgStartDelayTime" BO_ 2566899473 135;
BA_ "VFrameFormat" BO_ 2566899473 3;
BA_ "GenMsgCycleTime" BO_ 2566899217 1000;
BA_ "GenMsgStartDelayTime" BO_ 2566899217 20;
BA_ "VFrameFormat" BO_ 2566899217 3;
BA_ "GenMsgCycleTime" BO_ 2499751697 100;
BA_ "GenMsgStartDelayTime" BO_ 2499751697 55;
BA_ "VFrameFormat" BO_ 2499751697 3;
BA_ "GenMsgCycleTime" BO_ 2566897425 500;
BA_ "GenMsgStartDelayTime" BO_ 2566897425 15;
BA_ "VFrameFormat" BO_ 2566897425 3;
BA_ "GenMsgCycleTime" BO_ 2298429457 10;
BA_ "VFrameFormat" BO_ 2298429457 3;
BA_ "GenMsgCycleTime" BO_ 2566842385 250;
BA_ "GenMsgStartDelayTime" BO_ 2566842385 30;
BA_ "VFrameFormat" BO_ 2566842385 3;
BA_ "GenMsgCycleTime" BO_ 2566842606 500;
BA_ "VFrameFormat" BO_ 2566842606 3;
BA_ "GenMsgCycleTime" BO_ 2566849262 60000;
BA_ "GenMsgDelayTime" BO_ 2566849262 995;
BA_ "VFrameFormat" BO_ 2566849262 3;
BA_ "GenMsgCycleTime" BO_ 2566906094 60000;
BA_ "GenMsgDelayTime" BO_ 2566906094 995;
BA_ "VFrameFormat" BO_ 2566906094 3;
BA_ "GenMsgCycleTime" BO_ 2566849006 60000;
BA_ "VFrameFormat" BO_ 2566849006 3;
BA_ "GenMsgCycleTime" BO_ 2566832401 1000;
BA_ "GenMsgStartDelayTime" BO_ 2566832401 235;
BA_ "VFrameFormat" BO_ 2566832401 3;
BA_ "GenMsgCycleTime" BO_ 2566832622 1000;
BA_ "VFrameFormat" BO_ 2566832622 3;
BA_ "GenMsgCycleTime" BO_ 2566832407 1000;
BA_ "VFrameFormat" BO_ 2566832407 3;
BA_ "GenMsgCycleTime" BO_ 2364541195 10;
BA_ "VFrameFormat" BO_ 2364541195 3;
BA_ "GenMsgCycleTime" BO_ 2566803211 100;
BA_ "GenMsgStartDelayTime" BO_ 2566803211 55;
BA_ "VFrameFormat" BO_ 2566803211 3;
BA_ "GenMsgILSupport" BO_ 2675897544 0;
BA_ "GenMsgSendType" BO_ 2675897544 8;
BA_ "VFrameFormat" BO_ 2675897544 3;
BA_ "GenMsgILSupport" BO_ 2675897536 0;
BA_ "GenMsgSendType" BO_ 2675897536 8;
BA_ "VFrameFormat" BO_ 2675897536 3;
BA_ "GenMsgILSupport" BO_ 2675897528 0;
BA_ "GenMsgSendType" BO_ 2675897528 8;
BA_ "VFrameFormat" BO_ 2675897528 3;
BA_ "GenMsgILSupport" BO_ 2675897520 0;
BA_ "GenMsgSendType" BO_ 2675897520 8;
BA_ "VFrameFormat" BO_ 2675897520 3;
BA_ "GenMsgILSupport" BO_ 2675897512 0;
BA_ "GenMsgSendType" BO_ 2675897512 8;
BA_ "VFrameFormat" BO_ 2675897512 3;
BA_ "GenMsgILSupport" BO_ 2675897032 0;
BA_ "GenMsgSendType" BO_ 2675897032 8;
BA_ "VFrameFormat" BO_ 2675897032 3;
BA_ "GenMsgILSupport" BO_ 2675897024 0;
BA_ "GenMsgSendType" BO_ 2675897024 8;
BA_ "VFrameFormat" BO_ 2675897024 3;
BA_ "GenSigSendType" SG_ 2349075203 XBRTECU_Priority 1;
BA_ "GenSigStartValue" SG_ 2349075203 XBRTECU_Priority 3;
BA_ "Platform_VMCU1_Sig" SG_ 2349075203 XBRTECU_Priority 1;
BA_ "SPN" SG_ 2349075203 XBRTECU_Priority 2915;
BA_ "SeToolAncestorID_SIGNAL" SG_ 2349075203 XBRTECU_Priority "x0000001D0415DF81";
BA_ "SeToolItemID_SIGNAL" SG_ 2349075203 XBRTECU_Priority "x0000001D0415DF81";
BA_ "SeToolName_SIGNAL" SG_ 2349075203 XBRTECU_Priority "Priority";
BA_ "SeToolOwnerSigGroupID_SIGNAL" SG_ 2349075203 XBRTECU_Priority "x0000001D043D6E5C";
BA_ "SeToolOwnerSigGroup_SIGNAL" SG_ 2349075203 XBRTECU_Priority "XBRTECU";
BA_ "SeToolVersion_SIGNAL" SG_ 2349075203 XBRTECU_Priority "1";
BA_ "GenSigSendType" SG_ 2349075203 XBRTECU_MsgChecksum 1;
BA_ "Platform_VMCU1_Sig" SG_ 2349075203 XBRTECU_MsgChecksum 1;
BA_ "SPN" SG_ 2349075203 XBRTECU_MsgChecksum 3188;
BA_ "SeToolAncestorID_SIGNAL" SG_ 2349075203 XBRTECU_MsgChecksum "x0000001D043103C0";
BA_ "SeToolItemID_SIGNAL" SG_ 2349075203 XBRTECU_MsgChecksum "x0000001D043103C0";
BA_ "SeToolName_SIGNAL" SG_ 2349075203 XBRTECU_MsgChecksum "MsgChecksum";
BA_ "SeToolOwnerSigGroupID_SIGNAL" SG_ 2349075203 XBRTECU_MsgChecksum "x0000001D043D6E5C";
BA_ "SeToolOwnerSigGroup_SIGNAL" SG_ 2349075203 XBRTECU_MsgChecksum "XBRTECU";
BA_ "SeToolVersion_SIGNAL" SG_ 2349075203 XBRTECU_MsgChecksum "1";
BA_ "GenSigSendType" SG_ 2349075203 XBRTECU_EBIMode 1;
BA_ "GenSigStartValue" SG_ 2349075203 XBRTECU_EBIMode 3;
BA_ "Platform_VMCU1_Sig" SG_ 2349075203 XBRTECU_EBIMode 1;
BA_ "SPN" SG_ 2349075203 XBRTECU_EBIMode 2914;
BA_ "SeToolAncestorID_SIGNAL" SG_ 2349075203 XBRTECU_EBIMode "x0000001D0410D0BE";
BA_ "SeToolItemID_SIGNAL" SG_ 2349075203 XBRTECU_EBIMode "x0000001D0410D0BE";
BA_ "SeToolName_SIGNAL" SG_ 2349075203 XBRTECU_EBIMode "EBIMode";
BA_ "SeToolOwnerSigGroupID_SIGNAL" SG_ 2349075203 XBRTECU_EBIMode "x0000001D043D6E5C";
BA_ "SeToolOwnerSigGroup_SIGNAL" SG_ 2349075203 XBRTECU_EBIMode "XBRTECU";
BA_ "SeToolVersion_SIGNAL" SG_ 2349075203 XBRTECU_EBIMode "1";
BA_ "GenSigSendType" SG_ 2349075203 XBRTECU_Urgency 1;
BA_ "GenSigStartValue" SG_ 2349075203 XBRTECU_Urgency 255;
BA_ "Platform_VMCU1_Sig" SG_ 2349075203 XBRTECU_Urgency 1;
BA_ "SPN" SG_ 2349075203 XBRTECU_Urgency 4099;
BA_ "SeToolAncestorID_SIGNAL" SG_ 2349075203 XBRTECU_Urgency "x0000001D04162231";
BA_ "SeToolItemID_SIGNAL" SG_ 2349075203 XBRTECU_Urgency "x0000001D04162231";
BA_ "SeToolName_SIGNAL" SG_ 2349075203 XBRTECU_Urgency "Urgency";
BA_ "SeToolOwnerSigGroupID_SIGNAL" SG_ 2349075203 XBRTECU_Urgency "x0000001D043D6E5C";
BA_ "SeToolOwnerSigGroup_SIGNAL" SG_ 2349075203 XBRTECU_Urgency "XBRTECU";
BA_ "SeToolVersion_SIGNAL" SG_ 2349075203 XBRTECU_Urgency "1";
BA_ "GenSigSendType" SG_ 2349075203 XBRTECU_ControlMode 1;
BA_ "GenSigStartValue" SG_ 2349075203 XBRTECU_ControlMode 3;
BA_ "Platform_VMCU1_Sig" SG_ 2349075203 XBRTECU_ControlMode 1;
BA_ "SPN" SG_ 2349075203 XBRTECU_ControlMode 2916;
BA_ "SeToolAncestorID_SIGNAL" SG_ 2349075203 XBRTECU_ControlMode "x0000001D0415DF83";
BA_ "SeToolItemID_SIGNAL" SG_ 2349075203 XBRTECU_ControlMode "x0000001D0415DF83";
BA_ "SeToolName_SIGNAL" SG_ 2349075203 XBRTECU_ControlMode "ControlMode";
BA_ "SeToolOwnerSigGroupID_SIGNAL" SG_ 2349075203 XBRTECU_ControlMode "x0000001D043D6E5C";
BA_ "SeToolOwnerSigGroup_SIGNAL" SG_ 2349075203 XBRTECU_ControlMode "XBRTECU";
BA_ "SeToolVersion_SIGNAL" SG_ 2349075203 XBRTECU_ControlMode "1";
BA_ "GenSigSendType" SG_ 2349075203 XBRTECU_ExtAccelDemand 1;
BA_ "GenSigStartValue" SG_ 2349075203 XBRTECU_ExtAccelDemand 65535;
BA_ "Platform_VMCU1_Sig" SG_ 2349075203 XBRTECU_ExtAccelDemand 1;
BA_ "SPN" SG_ 2349075203 XBRTECU_ExtAccelDemand 2920;
BA_ "SeToolAncestorID_SIGNAL" SG_ 2349075203 XBRTECU_ExtAccelDemand "x0000001D0410D936";
BA_ "SeToolItemID_SIGNAL" SG_ 2349075203 XBRTECU_ExtAccelDemand "x0000001D0410D936";
BA_ "SeToolName_SIGNAL" SG_ 2349075203 XBRTECU_ExtAccelDemand "ExtAccelDemand";
BA_ "SeToolOwnerSigGroupID_SIGNAL" SG_ 2349075203 XBRTECU_ExtAccelDemand "x0000001D043D6E5C";
BA_ "SeToolOwnerSigGroup_SIGNAL" SG_ 2349075203 XBRTECU_ExtAccelDemand "XBRTECU";
BA_ "SeToolVersion_SIGNAL" SG_ 2349075203 XBRTECU_ExtAccelDemand "1";
BA_ "GenSigSendType" SG_ 2349075203 XBRTECU_MsgCounter 1;
BA_ "Platform_VMCU1_Sig" SG_ 2349075203 XBRTECU_MsgCounter 1;
BA_ "SPN" SG_ 2349075203 XBRTECU_MsgCounter 3189;
BA_ "SeToolAncestorID_SIGNAL" SG_ 2349075203 XBRTECU_MsgCounter "x0000001D043103C8";
BA_ "SeToolItemID_SIGNAL" SG_ 2349075203 XBRTECU_MsgCounter "x0000001D043103C8";
BA_ "SeToolName_SIGNAL" SG_ 2349075203 XBRTECU_MsgCounter "MsgCounter";
BA_ "SeToolOwnerSigGroupID_SIGNAL" SG_ 2349075203 XBRTECU_MsgCounter "x0000001D043D6E5C";
BA_ "SeToolOwnerSigGroup_SIGNAL" SG_ 2349075203 XBRTECU_MsgCounter "XBRTECU";
BA_ "SeToolVersion_SIGNAL" SG_ 2349075203 XBRTECU_MsgCounter "1";
BA_ "GenSigSendType" SG_ 2349075200 XBREMS_ControlMode 1;
BA_ "GenSigStartValue" SG_ 2349075200 XBREMS_ControlMode 3;
BA_ "Platform_VMCU1_Sig" SG_ 2349075200 XBREMS_ControlMode 1;
BA_ "SPN" SG_ 2349075200 XBREMS_ControlMode 2916;
BA_ "GenSigSendType" SG_ 2349075200 XBREMS_MsgCounter 1;
BA_ "GenSigStartValue" SG_ 2349075200 XBREMS_MsgCounter 15;
BA_ "Platform_VMCU1_Sig" SG_ 2349075200 XBREMS_MsgCounter 1;
BA_ "SPN" SG_ 2349075200 XBREMS_MsgCounter 3189;
BA_ "GenSigSendType" SG_ 2349075200 XBREMS_Urgency 1;
BA_ "GenSigStartValue" SG_ 2349075200 XBREMS_Urgency 255;
BA_ "Platform_VMCU1_Sig" SG_ 2349075200 XBREMS_Urgency 1;
BA_ "SPN" SG_ 2349075200 XBREMS_Urgency 4099;
BA_ "GenSigSendType" SG_ 2349075200 XBREMS_EBIMode 1;
BA_ "GenSigStartValue" SG_ 2349075200 XBREMS_EBIMode 3;
BA_ "Platform_VMCU1_Sig" SG_ 2349075200 XBREMS_EBIMode 1;
BA_ "SPN" SG_ 2349075200 XBREMS_EBIMode 2914;
BA_ "GenSigSendType" SG_ 2349075200 XBREMS_ExtAccelDemand 1;
BA_ "GenSigStartValue" SG_ 2349075200 XBREMS_ExtAccelDemand 65535;
BA_ "Platform_VMCU1_Sig" SG_ 2349075200 XBREMS_ExtAccelDemand 1;
BA_ "SPN" SG_ 2349075200 XBREMS_ExtAccelDemand 2920;
BA_ "GenSigSendType" SG_ 2349075200 XBREMS_Priority 1;
BA_ "GenSigStartValue" SG_ 2349075200 XBREMS_Priority 3;
BA_ "Platform_VMCU1_Sig" SG_ 2349075200 XBREMS_Priority 1;
BA_ "SPN" SG_ 2349075200 XBREMS_Priority 2915;
BA_ "GenSigSendType" SG_ 2349075200 XBREMS_MsgChecksum 1;
BA_ "GenSigStartValue" SG_ 2349075200 XBREMS_MsgChecksum 15;
BA_ "Platform_VMCU1_Sig" SG_ 2349075200 XBREMS_MsgChecksum 1;
BA_ "SPN" SG_ 2349075200 XBREMS_MsgChecksum 3188;
BA_ "GenSigSendType" SG_ 2349075373 XBRDACU_Urgency 1;
BA_ "GenSigStartValue" SG_ 2349075373 XBRDACU_Urgency 255;
BA_ "Platform_VMCU1_Sig" SG_ 2349075373 XBRDACU_Urgency 1;
BA_ "SPN" SG_ 2349075373 XBRDACU_Urgency 4099;
BA_ "SeToolAncestorID_SIGNAL" SG_ 2349075373 XBRDACU_Urgency "x0000001D04162231";
BA_ "SeToolItemID_SIGNAL" SG_ 2349075373 XBRDACU_Urgency "x0000001D04162231";
BA_ "SeToolName_SIGNAL" SG_ 2349075373 XBRDACU_Urgency "Urgency";
BA_ "SeToolOwnerSigGroupID_SIGNAL" SG_ 2349075373 XBRDACU_Urgency "x0000001D043D6E8E";
BA_ "SeToolOwnerSigGroup_SIGNAL" SG_ 2349075373 XBRDACU_Urgency "XBRDACU";
BA_ "SeToolVersion_SIGNAL" SG_ 2349075373 XBRDACU_Urgency "1";
BA_ "GenSigSendType" SG_ 2349075373 XBRDACU_EBIMode 1;
BA_ "GenSigStartValue" SG_ 2349075373 XBRDACU_EBIMode 3;
BA_ "Platform_VMCU1_Sig" SG_ 2349075373 XBRDACU_EBIMode 1;
BA_ "SPN" SG_ 2349075373 XBRDACU_EBIMode 2914;
BA_ "SeToolAncestorID_SIGNAL" SG_ 2349075373 XBRDACU_EBIMode "x0000001D0410D0BE";
BA_ "SeToolItemID_SIGNAL" SG_ 2349075373 XBRDACU_EBIMode "x0000001D0410D0BE";
BA_ "SeToolName_SIGNAL" SG_ 2349075373 XBRDACU_EBIMode "EBIMode";
BA_ "SeToolOwnerSigGroupID_SIGNAL" SG_ 2349075373 XBRDACU_EBIMode "x0000001D043D6E8E";
BA_ "SeToolOwnerSigGroup_SIGNAL" SG_ 2349075373 XBRDACU_EBIMode "XBRDACU";
BA_ "SeToolVersion_SIGNAL" SG_ 2349075373 XBRDACU_EBIMode "1";
BA_ "GenSigSendType" SG_ 2349075373 XBRDACU_ExtAccelDemand 1;
BA_ "GenSigStartValue" SG_ 2349075373 XBRDACU_ExtAccelDemand 65535;
BA_ "Platform_VMCU1_Sig" SG_ 2349075373 XBRDACU_ExtAccelDemand 1;
BA_ "SPN" SG_ 2349075373 XBRDACU_ExtAccelDemand 2920;
BA_ "SeToolAncestorID_SIGNAL" SG_ 2349075373 XBRDACU_ExtAccelDemand "x0000001D0410D936";
BA_ "SeToolItemID_SIGNAL" SG_ 2349075373 XBRDACU_ExtAccelDemand "x0000001D0410D936";
BA_ "SeToolName_SIGNAL" SG_ 2349075373 XBRDACU_ExtAccelDemand "ExtAccelDemand";
BA_ "SeToolOwnerSigGroupID_SIGNAL" SG_ 2349075373 XBRDACU_ExtAccelDemand "x0000001D043D6E8E";
BA_ "SeToolOwnerSigGroup_SIGNAL" SG_ 2349075373 XBRDACU_ExtAccelDemand "XBRDACU";
BA_ "SeToolVersion_SIGNAL" SG_ 2349075373 XBRDACU_ExtAccelDemand "1";
BA_ "GenSigSendType" SG_ 2349075373 XBRDACU_MsgCounter 1;
BA_ "Platform_VMCU1_Sig" SG_ 2349075373 XBRDACU_MsgCounter 1;
BA_ "SPN" SG_ 2349075373 XBRDACU_MsgCounter 3189;
BA_ "SeToolAncestorID_SIGNAL" SG_ 2349075373 XBRDACU_MsgCounter "x0000001D043103C8";
BA_ "SeToolItemID_SIGNAL" SG_ 2349075373 XBRDACU_MsgCounter "x0000001D043103C8";
BA_ "SeToolName_SIGNAL" SG_ 2349075373 XBRDACU_MsgCounter "MsgCounter";
BA_ "SeToolOwnerSigGroupID_SIGNAL" SG_ 2349075373 XBRDACU_MsgCounter "x0000001D043D6E8E";
BA_ "SeToolOwnerSigGroup_SIGNAL" SG_ 2349075373 XBRDACU_MsgCounter "XBRDACU";
BA_ "SeToolVersion_SIGNAL" SG_ 2349075373 XBRDACU_MsgCounter "1";
BA_ "GenSigSendType" SG_ 2349075373 XBRDACU_MsgChecksum 1;
BA_ "Platform_VMCU1_Sig" SG_ 2349075373 XBRDACU_MsgChecksum 1;
BA_ "SPN" SG_ 2349075373 XBRDACU_MsgChecksum 3188;
BA_ "SeToolAncestorID_SIGNAL" SG_ 2349075373 XBRDACU_MsgChecksum "x0000001D043103C0";
BA_ "SeToolItemID_SIGNAL" SG_ 2349075373 XBRDACU_MsgChecksum "x0000001D043103C0";
BA_ "SeToolName_SIGNAL" SG_ 2349075373 XBRDACU_MsgChecksum "MsgChecksum";
BA_ "SeToolOwnerSigGroupID_SIGNAL" SG_ 2349075373 XBRDACU_MsgChecksum "x0000001D043D6E8E";
BA_ "SeToolOwnerSigGroup_SIGNAL" SG_ 2349075373 XBRDACU_MsgChecksum "XBRDACU";
BA_ "SeToolVersion_SIGNAL" SG_ 2349075373 XBRDACU_MsgChecksum "1";
BA_ "GenSigSendType" SG_ 2349075373 XBRDACU_ControlMode 1;
BA_ "GenSigStartValue" SG_ 2349075373 XBRDACU_ControlMode 3;
BA_ "Platform_VMCU1_Sig" SG_ 2349075373 XBRDACU_ControlMode 1;
BA_ "SPN" SG_ 2349075373 XBRDACU_ControlMode 2916;
BA_ "SeToolAncestorID_SIGNAL" SG_ 2349075373 XBRDACU_ControlMode "x0000001D0415DF83";
BA_ "SeToolItemID_SIGNAL" SG_ 2349075373 XBRDACU_ControlMode "x0000001D0415DF83";
BA_ "SeToolName_SIGNAL" SG_ 2349075373 XBRDACU_ControlMode "ControlMode";
BA_ "SeToolOwnerSigGroupID_SIGNAL" SG_ 2349075373 XBRDACU_ControlMode "x0000001D043D6E8E";
BA_ "SeToolOwnerSigGroup_SIGNAL" SG_ 2349075373 XBRDACU_ControlMode "XBRDACU";
BA_ "SeToolVersion_SIGNAL" SG_ 2349075373 XBRDACU_ControlMode "1";
BA_ "GenSigSendType" SG_ 2349075373 XBRDACU_Priority 1;
BA_ "GenSigStartValue" SG_ 2349075373 XBRDACU_Priority 3;
BA_ "Platform_VMCU1_Sig" SG_ 2349075373 XBRDACU_Priority 1;
BA_ "SPN" SG_ 2349075373 XBRDACU_Priority 2915;
BA_ "SeToolAncestorID_SIGNAL" SG_ 2349075373 XBRDACU_Priority "x0000001D0415DF81";
BA_ "SeToolItemID_SIGNAL" SG_ 2349075373 XBRDACU_Priority "x0000001D0415DF81";
BA_ "SeToolName_SIGNAL" SG_ 2349075373 XBRDACU_Priority "Priority";
BA_ "SeToolOwnerSigGroupID_SIGNAL" SG_ 2349075373 XBRDACU_Priority "x0000001D043D6E8E";
BA_ "SeToolOwnerSigGroup_SIGNAL" SG_ 2349075373 XBRDACU_Priority "XBRDACU";
BA_ "SeToolVersion_SIGNAL" SG_ 2349075373 XBRDACU_Priority "1";
BA_ "GenSigSendType" SG_ 2349075430 XBRBBM_Urgency 1;
BA_ "GenSigStartValue" SG_ 2349075430 XBRBBM_Urgency 255;
BA_ "Platform_VMCU1_Sig" SG_ 2349075430 XBRBBM_Urgency 1;
BA_ "SPN" SG_ 2349075430 XBRBBM_Urgency 4099;
BA_ "GenSigSendType" SG_ 2349075430 XBRBBM_ControlMode 1;
BA_ "Platform_VMCU1_Sig" SG_ 2349075430 XBRBBM_ControlMode 1;
BA_ "SPN" SG_ 2349075430 XBRBBM_ControlMode 2916;
BA_ "GenSigSendType" SG_ 2349075430 XBRBBM_Priority 1;
BA_ "GenSigStartValue" SG_ 2349075430 XBRBBM_Priority 3;
BA_ "Platform_VMCU1_Sig" SG_ 2349075430 XBRBBM_Priority 1;
BA_ "SPN" SG_ 2349075430 XBRBBM_Priority 2915;
BA_ "GenSigSendType" SG_ 2349075430 XBRBBM_MsgCounter 1;
BA_ "Platform_VMCU1_Sig" SG_ 2349075430 XBRBBM_MsgCounter 1;
BA_ "SPN" SG_ 2349075430 XBRBBM_MsgCounter 3189;
BA_ "GenSigSendType" SG_ 2349075430 XBRBBM_MsgChecksum 1;
BA_ "Platform_VMCU1_Sig" SG_ 2349075430 XBRBBM_MsgChecksum 1;
BA_ "SPN" SG_ 2349075430 XBRBBM_MsgChecksum 3188;
BA_ "GenSigSendType" SG_ 2349075430 XBRBBM_EBIMode 1;
BA_ "Platform_VMCU1_Sig" SG_ 2349075430 XBRBBM_EBIMode 1;
BA_ "SPN" SG_ 2349075430 XBRBBM_EBIMode 2914;
BA_ "GenSigSendType" SG_ 2349075430 XBRBBM_ExtAccelDemand 1;
BA_ "GenSigStartValue" SG_ 2349075430 XBRBBM_ExtAccelDemand 65535;
BA_ "Platform_VMCU1_Sig" SG_ 2349075430 XBRBBM_ExtAccelDemand 1;
BA_ "SPN" SG_ 2349075430 XBRBBM_ExtAccelDemand 2920;
BA_ "GenSigCycleTime" SG_ 2566848256 WaterInFuelAlarm_ISig_3 100;
BA_ "GenSigCycleTimeActive" SG_ 2566848256 WaterInFuelAlarm_ISig_3 100;
BA_ "GenSigStartValue" SG_ 2566848256 WaterInFuelAlarm_ISig_3 3;
BA_ "Platform_VMCU1_Sig" SG_ 2566848256 WaterInFuelAlarm_ISig_3 1;
BA_ "SPN" SG_ 2566848256 WaterInFuelAlarm_ISig_3 97;
BA_ "SeToolAncestorID_SIGNAL" SG_ 2566848256 WaterInFuelAlarm_ISig_3 "x0000001D041412F3";
BA_ "SeToolItemID_SIGNAL" SG_ 2566848256 WaterInFuelAlarm_ISig_3 "x0000001D041412F3";
BA_ "SeToolName_SIGNAL" SG_ 2566848256 WaterInFuelAlarm_ISig_3 "WaterInFuelAlarm";
BA_ "SeToolVersion_SIGNAL" SG_ 2566848256 WaterInFuelAlarm_ISig_3 "1";
BA_ "GenSigSendType" SG_ 2583636718 Drvr2ManualEntryStatus 3;
BA_ "GenSigCycleTime" SG_ 2583636718 Drvr2ManualEntryStatus 100;
BA_ "GenSigCycleTimeActive" SG_ 2583636718 Drvr2ManualEntryStatus 100;
BA_ "GenSigStartValue" SG_ 2583636718 Drvr2ManualEntryStatus 15;
BA_ "GenSigSendType" SG_ 2583636718 CurrentFerryTrainStatus 3;
BA_ "GenSigCycleTime" SG_ 2583636718 CurrentFerryTrainStatus 100;
BA_ "GenSigCycleTimeActive" SG_ 2583636718 CurrentFerryTrainStatus 100;
BA_ "GenSigSendType" SG_ 2583636718 Drvr1ManualEntryStatus 3;
BA_ "GenSigCycleTime" SG_ 2583636718 Drvr1ManualEntryStatus 100;
BA_ "GenSigCycleTimeActive" SG_ 2583636718 Drvr1ManualEntryStatus 100;
BA_ "GenSigStartValue" SG_ 2583636718 Drvr1ManualEntryStatus 15;
BA_ "GenSigCycleTime" SG_ 2583635694 GNSSTime_Tacho 100;
BA_ "GenSigCycleTimeActive" SG_ 2583635694 GNSSTime_Tacho 100;
BA_ "GenSigStartValue" SG_ 2583635694 GNSSTime_Tacho 4294967295;
BA_ "GenSigCycleTime" SG_ 2583635694 GNSSLiveStatus_Tacho 100;
BA_ "GenSigCycleTimeActive" SG_ 2583635694 GNSSLiveStatus_Tacho 100;
BA_ "GenSigStartValue" SG_ 2583635694 GNSSLiveStatus_Tacho 255;
BA_ "GenSigCycleTime" SG_ 2566845201 VehiclePosSAE_Longitude 100;
BA_ "GenSigCycleTimeActive" SG_ 2566845201 VehiclePosSAE_Longitude 100;
BA_ "GenSigStartValue" SG_ 2566845201 VehiclePosSAE_Longitude 4294967295;
BA_ "SPN" SG_ 2566845201 VehiclePosSAE_Longitude 585;
BA_ "GenSigCycleTime" SG_ 2566845201 VehiclePosSAE_Latitude 100;
BA_ "GenSigCycleTimeActive" SG_ 2566845201 VehiclePosSAE_Latitude 100;
BA_ "GenSigStartValue" SG_ 2566845201 VehiclePosSAE_Latitude 4294967295;
BA_ "SPN" SG_ 2566845201 VehiclePosSAE_Latitude 584;
BA_ "GenSigCycleTime" SG_ 2566845422 VehPos1_Latitude 100;
BA_ "GenSigCycleTimeActive" SG_ 2566845422 VehPos1_Latitude 100;
BA_ "GenSigStartValue" SG_ 2566845422 VehPos1_Latitude 4294967295;
BA_ "GenSigCycleTime" SG_ 2566845422 VehPos1_Longitude 100;
BA_ "GenSigCycleTimeActive" SG_ 2566845422 VehPos1_Longitude 100;
BA_ "GenSigStartValue" SG_ 2566845422 VehPos1_Longitude 4294967295;
BA_ "GenSigCycleTime" SG_ 2566901009 LNGConsumedPTO 100;
BA_ "GenSigCycleTimeActive" SG_ 2566901009 LNGConsumedPTO 100;
BA_ "GenSigStartValue" SG_ 2566901009 LNGConsumedPTO 4294967295;
BA_ "GenSigCycleTime" SG_ 2566901009 EngTrueIdleSpeedLNG 100;
BA_ "GenSigCycleTimeActive" SG_ 2566901009 EngTrueIdleSpeedLNG 100;
BA_ "GenSigStartValue" SG_ 2566901009 EngTrueIdleSpeedLNG 4294967295;
BA_ "GenSigCycleTime" SG_ 2499788567 DrvrRetarderBrakeBlending_rqst_I 100;
BA_ "GenSigCycleTimeActive" SG_ 2499788567 DrvrRetarderBrakeBlending_rqst_I 100;
BA_ "GenSigStartValue" SG_ 2499788567 DrvrRetarderBrakeBlending_rqst_I 3;
BA_ "GenSigMaxLatency" SG_ 2499788567 DrvrRetarderBrakeBlending_rqst_I 65;
BA_ "Platform_VMCU1_Sig" SG_ 2499788567 DrvrRetarderBrakeBlending_rqst_I 1;
BA_ "SeToolAncestorID_SIGNAL" SG_ 2499788567 DrvrRetarderBrakeBlending_rqst_I "x0000001D0413D707";
BA_ "SeToolItemID_SIGNAL" SG_ 2499788567 DrvrRetarderBrakeBlending_rqst_I "x0000001D043135DD";
BA_ "SeToolName_SIGNAL" SG_ 2499788567 DrvrRetarderBrakeBlending_rqst_I "DriverRetarderBrakeBlendingRequest";
BA_ "SeToolVersion_SIGNAL" SG_ 2499788567 DrvrRetarderBrakeBlending_rqst_I "2";
BA_ "SystemSignalLongSymbol" SG_ 2499788567 DrvrRetarderBrakeBlending_rqst_I "DrvrRetarderBrakeBlending_rqst_ISig_3";
BA_ "GenSigCycleTime" SG_ 2499788567 DrvrRetarderBrakeProgram_rqst_IS 100;
BA_ "GenSigCycleTimeActive" SG_ 2499788567 DrvrRetarderBrakeProgram_rqst_IS 100;
BA_ "GenSigStartValue" SG_ 2499788567 DrvrRetarderBrakeProgram_rqst_IS 3;
BA_ "GenSigMaxLatency" SG_ 2499788567 DrvrRetarderBrakeProgram_rqst_IS 65;
BA_ "Platform_VMCU1_Sig" SG_ 2499788567 DrvrRetarderBrakeProgram_rqst_IS 1;
BA_ "SeToolAncestorID_SIGNAL" SG_ 2499788567 DrvrRetarderBrakeProgram_rqst_IS "x0000001D0414BF93";
BA_ "SeToolItemID_SIGNAL" SG_ 2499788567 DrvrRetarderBrakeProgram_rqst_IS "x0000001D042D7CE4";
BA_ "SeToolName_SIGNAL" SG_ 2499788567 DrvrRetarderBrakeProgram_rqst_IS "DriverRetarderBrakeProgramRequest";
BA_ "SeToolVersion_SIGNAL" SG_ 2499788567 DrvrRetarderBrakeProgram_rqst_IS "2";
BA_ "SystemSignalLongSymbol" SG_ 2499788567 DrvrRetarderBrakeProgram_rqst_IS "DrvrRetarderBrakeProgram_rqst_ISig_3";
BA_ "GenSigCycleTime" SG_ 2499788567 GearLeverPositionBackup 100;
BA_ "GenSigCycleTimeActive" SG_ 2499788567 GearLeverPositionBackup 100;
BA_ "GenSigStartValue" SG_ 2499788567 GearLeverPositionBackup 15;
BA_ "Platform_VMCU1_Sig" SG_ 2499788567 GearLeverPositionBackup 1;
BA_ "GenSigCycleTime" SG_ 2499788567 EHRearAxleSteeringFuncStatus 100;
BA_ "GenSigCycleTimeActive" SG_ 2499788567 EHRearAxleSteeringFuncStatus 100;
BA_ "GenSigStartValue" SG_ 2499788567 EHRearAxleSteeringFuncStatus 7;
BA_ "GenSigCycleTime" SG_ 2499788567 GearLeverPos2Backup_Rqst 100;
BA_ "GenSigCycleTimeActive" SG_ 2499788567 GearLeverPos2Backup_Rqst 100;
BA_ "GenSigStartValue" SG_ 2499788567 GearLeverPos2Backup_Rqst 15;
BA_ "GenSigCycleTime" SG_ 2499788567 GearLeverPos2Backup_SqC 100;
BA_ "GenSigCycleTimeActive" SG_ 2499788567 GearLeverPos2Backup_SqC 100;
BA_ "GenSigCycleTime" SG_ 2499788567 GearLeverPos2Backup_CRC 100;
BA_ "GenSigCycleTimeActive" SG_ 2499788567 GearLeverPos2Backup_CRC 100;
BA_ "GenSigCycleTime" SG_ 2499788567 DriverRetarderRequest_ISig_3 100;
BA_ "GenSigCycleTimeActive" SG_ 2499788567 DriverRetarderRequest_ISig_3 100;
BA_ "GenSigStartValue" SG_ 2499788567 DriverRetarderRequest_ISig_3 7;
BA_ "GenSigMaxLatency" SG_ 2499788567 DriverRetarderRequest_ISig_3 65;
BA_ "Platform_VMCU1_Sig" SG_ 2499788567 DriverRetarderRequest_ISig_3 1;
BA_ "SeToolAncestorID_SIGNAL" SG_ 2499788567 DriverRetarderRequest_ISig_3 "x0000001D0414BEA2";
BA_ "SeToolItemID_SIGNAL" SG_ 2499788567 DriverRetarderRequest_ISig_3 "x0000001D043806A5";
BA_ "SeToolName_SIGNAL" SG_ 2499788567 DriverRetarderRequest_ISig_3 "DriverRetarderRequest";
BA_ "SeToolVersion_SIGNAL" SG_ 2499788567 DriverRetarderRequest_ISig_3 "2";
BA_ "GenSigCycleTime" SG_ 2499788567 AirDumpStatus_ISig_3 100;
BA_ "GenSigCycleTimeActive" SG_ 2499788567 AirDumpStatus_ISig_3 100;
BA_ "GenSigStartValue" SG_ 2499788567 AirDumpStatus_ISig_3 7;
BA_ "GenSigCycleTime" SG_ 2566899729 LoadCalibFail_Range_ISig_3 100;
BA_ "GenSigCycleTimeActive" SG_ 2566899729 LoadCalibFail_Range_ISig_3 100;
BA_ "GenSigStartValue" SG_ 2566899729 LoadCalibFail_Range_ISig_3 3;
BA_ "GenSigCycleTime" SG_ 2566899729 LoadCalibFail_WrongVM_ISig_3 100;
BA_ "GenSigCycleTimeActive" SG_ 2566899729 LoadCalibFail_WrongVM_ISig_3 100;
BA_ "GenSigStartValue" SG_ 2566899729 LoadCalibFail_WrongVM_ISig_3 3;
BA_ "GenSigCycleTime" SG_ 2566899729 LoadCalibFail_InMotion_ISig_3 100;
BA_ "GenSigCycleTimeActive" SG_ 2566899729 LoadCalibFail_InMotion_ISig_3 100;
BA_ "GenSigStartValue" SG_ 2566899729 LoadCalibFail_InMotion_ISig_3 3;
BA_ "GenSigCycleTime" SG_ 2566899729 LoadCalibFail_InternalFailure_IS 100;
BA_ "GenSigCycleTimeActive" SG_ 2566899729 LoadCalibFail_InternalFailure_IS 100;
BA_ "GenSigStartValue" SG_ 2566899729 LoadCalibFail_InternalFailure_IS 3;
BA_ "SystemSignalLongSymbol" SG_ 2566899729 LoadCalibFail_InternalFailure_IS "LoadCalibFail_InternalFailure_ISig_3";
BA_ "GenSigCycleTime" SG_ 2566899729 LoadCalibFail_OutOfMemory_ISig_3 100;
BA_ "GenSigCycleTimeActive" SG_ 2566899729 LoadCalibFail_OutOfMemory_ISig_3 100;
BA_ "GenSigStartValue" SG_ 2566899729 LoadCalibFail_OutOfMemory_ISig_3 3;
BA_ "GenSigCycleTime" SG_ 2566899729 Trailer5CalibStoreReq_CalibType 100;
BA_ "GenSigCycleTimeActive" SG_ 2566899729 Trailer5CalibStoreReq_CalibType 100;
BA_ "GenSigStartValue" SG_ 2566899729 Trailer5CalibStoreReq_CalibType 3;
BA_ "GenSigMaxLatency" SG_ 2566899729 Trailer5CalibStoreReq_CalibType 1070;
BA_ "GenSigCycleTime" SG_ 2566899729 Trailer5CalibStoreReq_AxleId 100;
BA_ "GenSigCycleTimeActive" SG_ 2566899729 Trailer5CalibStoreReq_AxleId 100;
BA_ "GenSigMaxLatency" SG_ 2566899729 Trailer5CalibStoreReq_AxleId 1070;
BA_ "GenSigCycleTime" SG_ 2566899729 LoadCalibrationFeedback_ISig_3 100;
BA_ "GenSigCycleTimeActive" SG_ 2566899729 LoadCalibrationFeedback_ISig_3 100;
BA_ "GenSigStartValue" SG_ 2566899729 LoadCalibrationFeedback_ISig_3 7;
BA_ "GenSigCycleTime" SG_ 2566899729 Trailer5CalibStoreReq_ScaleLoad 100;
BA_ "GenSigCycleTimeActive" SG_ 2566899729 Trailer5CalibStoreReq_ScaleLoad 100;
BA_ "GenSigStartValue" SG_ 2566899729 Trailer5CalibStoreReq_ScaleLoad 65535;
BA_ "GenSigMaxLatency" SG_ 2566899729 Trailer5CalibStoreReq_ScaleLoad 1070;
BA_ "GenSigCycleTime" SG_ 2566899729 LoadCalibFail_WrongHeight_ISig_3 100;
BA_ "GenSigCycleTimeActive" SG_ 2566899729 LoadCalibFail_WrongHeight_ISig_3 100;
BA_ "GenSigStartValue" SG_ 2566899729 LoadCalibFail_WrongHeight_ISig_3 3;
BA_ "GenSigCycleTime" SG_ 2566899473 Trailer4CalibStoreReq_AxleId 100;
BA_ "GenSigCycleTimeActive" SG_ 2566899473 Trailer4CalibStoreReq_AxleId 100;
BA_ "GenSigMaxLatency" SG_ 2566899473 Trailer4CalibStoreReq_AxleId 1060;
BA_ "GenSigCycleTime" SG_ 2566899473 Trailer3CalibStoreReq_ScaleLoad 100;
BA_ "GenSigCycleTimeActive" SG_ 2566899473 Trailer3CalibStoreReq_ScaleLoad 100;
BA_ "GenSigStartValue" SG_ 2566899473 Trailer3CalibStoreReq_ScaleLoad 65535;
BA_ "GenSigMaxLatency" SG_ 2566899473 Trailer3CalibStoreReq_ScaleLoad 1060;
BA_ "GenSigCycleTime" SG_ 2566899473 Trailer3CalibStoreReq_CalibType 100;
BA_ "GenSigCycleTimeActive" SG_ 2566899473 Trailer3CalibStoreReq_CalibType 100;
BA_ "GenSigStartValue" SG_ 2566899473 Trailer3CalibStoreReq_CalibType 3;
BA_ "GenSigMaxLatency" SG_ 2566899473 Trailer3CalibStoreReq_CalibType 1060;
BA_ "GenSigCycleTime" SG_ 2566899473 Trailer4CalibStoreReq_ScaleLoad 100;
BA_ "GenSigCycleTimeActive" SG_ 2566899473 Trailer4CalibStoreReq_ScaleLoad 100;
BA_ "GenSigStartValue" SG_ 2566899473 Trailer4CalibStoreReq_ScaleLoad 65535;
BA_ "GenSigMaxLatency" SG_ 2566899473 Trailer4CalibStoreReq_ScaleLoad 1060;
BA_ "GenSigCycleTime" SG_ 2566899473 Trailer4CalibStoreReq_CalibType 100;
BA_ "GenSigCycleTimeActive" SG_ 2566899473 Trailer4CalibStoreReq_CalibType 100;
BA_ "GenSigStartValue" SG_ 2566899473 Trailer4CalibStoreReq_CalibType 3;
BA_ "GenSigMaxLatency" SG_ 2566899473 Trailer4CalibStoreReq_CalibType 1060;
BA_ "GenSigCycleTime" SG_ 2566899473 Trailer3CalibStoreReq_AxleId 100;
BA_ "GenSigCycleTimeActive" SG_ 2566899473 Trailer3CalibStoreReq_AxleId 100;
BA_ "GenSigMaxLatency" SG_ 2566899473 Trailer3CalibStoreReq_AxleId 1060;
BA_ "GenSigCycleTime" SG_ 2566899217 Trailer1CalibStoreReq_ScaleLoad 100;
BA_ "GenSigCycleTimeActive" SG_ 2566899217 Trailer1CalibStoreReq_ScaleLoad 100;
BA_ "GenSigStartValue" SG_ 2566899217 Trailer1CalibStoreReq_ScaleLoad 65535;
BA_ "GenSigMaxLatency" SG_ 2566899217 Trailer1CalibStoreReq_ScaleLoad 1050;
BA_ "GenSigCycleTime" SG_ 2566899217 Trailer1CalibStoreReq_CalibType 100;
BA_ "GenSigCycleTimeActive" SG_ 2566899217 Trailer1CalibStoreReq_CalibType 100;
BA_ "GenSigStartValue" SG_ 2566899217 Trailer1CalibStoreReq_CalibType 3;
BA_ "GenSigMaxLatency" SG_ 2566899217 Trailer1CalibStoreReq_CalibType 1050;
BA_ "GenSigCycleTime" SG_ 2566899217 Trailer1CalibStoreReq_AxleId 100;
BA_ "GenSigCycleTimeActive" SG_ 2566899217 Trailer1CalibStoreReq_AxleId 100;
BA_ "GenSigMaxLatency" SG_ 2566899217 Trailer1CalibStoreReq_AxleId 1050;
BA_ "GenSigCycleTime" SG_ 2566899217 Trailer2CalibStoreReq_AxleId 100;
BA_ "GenSigCycleTimeActive" SG_ 2566899217 Trailer2CalibStoreReq_AxleId 100;
BA_ "GenSigMaxLatency" SG_ 2566899217 Trailer2CalibStoreReq_AxleId 1050;
BA_ "GenSigCycleTime" SG_ 2566899217 Trailer2CalibStoreReq_CalibType 100;
BA_ "GenSigCycleTimeActive" SG_ 2566899217 Trailer2CalibStoreReq_CalibType 100;
BA_ "GenSigStartValue" SG_ 2566899217 Trailer2CalibStoreReq_CalibType 3;
BA_ "GenSigMaxLatency" SG_ 2566899217 Trailer2CalibStoreReq_CalibType 1050;
BA_ "GenSigCycleTime" SG_ 2566899217 Trailer2CalibStoreReq_ScaleLoad 100;
BA_ "GenSigCycleTimeActive" SG_ 2566899217 Trailer2CalibStoreReq_ScaleLoad 100;
BA_ "GenSigStartValue" SG_ 2566899217 Trailer2CalibStoreReq_ScaleLoad 65535;
BA_ "GenSigMaxLatency" SG_ 2566899217 Trailer2CalibStoreReq_ScaleLoad 1050;
BA_ "GenSigSendType" SG_ 2499751697 TrailerConnected_UB_ISig_3 7;
BA_ "Platform_VMCU1_Sig" SG_ 2499751697 TrailerConnected_UB_ISig_3 1;
BA_ "GenSigCycleTime" SG_ 2499751697 RearAxle2DiffLock_stat_ISig_3 100;
BA_ "GenSigCycleTimeActive" SG_ 2499751697 RearAxle2DiffLock_stat_ISig_3 100;
BA_ "GenSigStartValue" SG_ 2499751697 RearAxle2DiffLock_stat_ISig_3 3;
BA_ "GenSigMaxLatency" SG_ 2499751697 RearAxle2DiffLock_stat_ISig_3 35;
BA_ "NeedsUpdateBit" SG_ 2499751697 RearAxle2DiffLock_stat_ISig_3 1;
BA_ "Platform_VMCU1_Sig" SG_ 2499751697 RearAxle2DiffLock_stat_ISig_3 1;
BA_ "SeToolAncestorID_SIGNAL" SG_ 2499751697 RearAxle2DiffLock_stat_ISig_3 "x0000001D04128800";
BA_ "SeToolItemID_SIGNAL" SG_ 2499751697 RearAxle2DiffLock_stat_ISig_3 "x0000001D04128800";
BA_ "SeToolName_SIGNAL" SG_ 2499751697 RearAxle2DiffLock_stat_ISig_3 "DifferentialLockState-RearAxle2";
BA_ "SeToolVersion_SIGNAL" SG_ 2499751697 RearAxle2DiffLock_stat_ISig_3 "1";
BA_ "GenSigCycleTime" SG_ 2499751697 EngineStopReqBackup 100;
BA_ "GenSigCycleTimeActive" SG_ 2499751697 EngineStopReqBackup 100;
BA_ "GenSigStartValue" SG_ 2499751697 EngineStopReqBackup 3;
BA_ "GenSigMaxLatency" SG_ 2499751697 EngineStopReqBackup 100;
BA_ "Platform_VMCU1_Sig" SG_ 2499751697 EngineStopReqBackup 1;
BA_ "GenSigCycleTime" SG_ 2499751697 DifferentialLockStateCentral_ISi 100;
BA_ "GenSigCycleTimeActive" SG_ 2499751697 DifferentialLockStateCentral_ISi 100;
BA_ "GenSigStartValue" SG_ 2499751697 DifferentialLockStateCentral_ISi 3;
BA_ "Platform_VMCU1_Sig" SG_ 2499751697 DifferentialLockStateCentral_ISi 1;
BA_ "SystemSignalLongSymbol" SG_ 2499751697 DifferentialLockStateCentral_ISi "DifferentialLockStateCentral_ISig_3";
BA_ "GenSigSendType" SG_ 2499751697 RearAxle2DiffLock_stat_UB_ISig_3 7;
BA_ "Platform_VMCU1_Sig" SG_ 2499751697 RearAxle2DiffLock_stat_UB_ISig_3 1;
BA_ "GenSigCycleTime" SG_ 2499751697 RrInterAxlDiffLockActvnFuncReq_I 100;
BA_ "GenSigCycleTimeActive" SG_ 2499751697 RrInterAxlDiffLockActvnFuncReq_I 100;
BA_ "GenSigStartValue" SG_ 2499751697 RrInterAxlDiffLockActvnFuncReq_I 3;
BA_ "SystemSignalLongSymbol" SG_ 2499751697 RrInterAxlDiffLockActvnFuncReq_I "RrInterAxlDiffLockActvnFuncReq_ISig_3";
BA_ "GenSigCycleTime" SG_ 2499751697 RearPropulsionStat_Rear1Axle_ISi 100;
BA_ "GenSigCycleTimeActive" SG_ 2499751697 RearPropulsionStat_Rear1Axle_ISi 100;
BA_ "GenSigStartValue" SG_ 2499751697 RearPropulsionStat_Rear1Axle_ISi 15;
BA_ "Platform_VMCU1_Sig" SG_ 2499751697 RearPropulsionStat_Rear1Axle_ISi 1;
BA_ "SystemSignalLongSymbol" SG_ 2499751697 RearPropulsionStat_Rear1Axle_ISi "RearPropulsionStat_Rear1Axle_ISig_3";
BA_ "GenSigCycleTime" SG_ 2499751697 SetHSAOperation 100;
BA_ "GenSigCycleTimeActive" SG_ 2499751697 SetHSAOperation 100;
BA_ "GenSigStartValue" SG_ 2499751697 SetHSAOperation 7;
BA_ "Platform_VMCU1_Sig" SG_ 2499751697 SetHSAOperation 1;
BA_ "GenSigCycleTime" SG_ 2499751697 CentralRearDiffLock_stat_ISig_3 100;
BA_ "GenSigCycleTimeActive" SG_ 2499751697 CentralRearDiffLock_stat_ISig_3 100;
BA_ "GenSigStartValue" SG_ 2499751697 CentralRearDiffLock_stat_ISig_3 3;
BA_ "GenSigMaxLatency" SG_ 2499751697 CentralRearDiffLock_stat_ISig_3 35;
BA_ "NeedsUpdateBit" SG_ 2499751697 CentralRearDiffLock_stat_ISig_3 1;
BA_ "Platform_VMCU1_Sig" SG_ 2499751697 CentralRearDiffLock_stat_ISig_3 1;
BA_ "SeToolAncestorID_SIGNAL" SG_ 2499751697 CentralRearDiffLock_stat_ISig_3 "x0000001D04119DA2";
BA_ "SeToolItemID_SIGNAL" SG_ 2499751697 CentralRearDiffLock_stat_ISig_3 "x0000001D04119DA2";
BA_ "SeToolName_SIGNAL" SG_ 2499751697 CentralRearDiffLock_stat_ISig_3 "Differential LockState-CentralRear";
BA_ "SeToolVersion_SIGNAL" SG_ 2499751697 CentralRearDiffLock_stat_ISig_3 "1";
BA_ "GenSigCycleTime" SG_ 2499751697 AutoPBRelease_stat_ISig_3 100;
BA_ "GenSigCycleTimeActive" SG_ 2499751697 AutoPBRelease_stat_ISig_3 100;
BA_ "GenSigStartValue" SG_ 2499751697 AutoPBRelease_stat_ISig_3 3;
BA_ "SeToolAncestorID_SIGNAL" SG_ 2499751697 AutoPBRelease_stat_ISig_3 "x0000001D042E42B1";
BA_ "SeToolItemID_SIGNAL" SG_ 2499751697 AutoPBRelease_stat_ISig_3 "x0000001D042E42B1";
BA_ "SeToolName_SIGNAL" SG_ 2499751697 AutoPBRelease_stat_ISig_3 "AutoPBRelease_stat";
BA_ "SeToolVersion_SIGNAL" SG_ 2499751697 AutoPBRelease_stat_ISig_3 "1";
BA_ "GenSigCycleTime" SG_ 2499751697 RearAxle3DiffLock_stat_ISig_3 100;
BA_ "GenSigCycleTimeActive" SG_ 2499751697 RearAxle3DiffLock_stat_ISig_3 100;
BA_ "GenSigStartValue" SG_ 2499751697 RearAxle3DiffLock_stat_ISig_3 3;
BA_ "NeedsUpdateBit" SG_ 2499751697 RearAxle3DiffLock_stat_ISig_3 1;
BA_ "GenSigCycleTime" SG_ 2499751697 DifferentialLockStateCentral2 100;
BA_ "GenSigCycleTimeActive" SG_ 2499751697 DifferentialLockStateCentral2 100;
BA_ "GenSigStartValue" SG_ 2499751697 DifferentialLockStateCentral2 3;
BA_ "GenSigCycleTime" SG_ 2499751697 LowAirPressureAlert 100;
BA_ "GenSigCycleTimeActive" SG_ 2499751697 LowAirPressureAlert 100;
BA_ "GenSigStartValue" SG_ 2499751697 LowAirPressureAlert 3;
BA_ "GenSigMaxLatency" SG_ 2499751697 LowAirPressureAlert 35;
BA_ "Platform_VMCU1_Sig" SG_ 2499751697 LowAirPressureAlert 1;
BA_ "SeToolAncestorID_SIGNAL" SG_ 2499751697 LowAirPressureAlert "x0000001D0414980D";
BA_ "SeToolItemID_SIGNAL" SG_ 2499751697 LowAirPressureAlert "x0000001D04357133";
BA_ "SeToolName_SIGNAL" SG_ 2499751697 LowAirPressureAlert "LowAirPressureAlert";
BA_ "SeToolVersion_SIGNAL" SG_ 2499751697 LowAirPressureAlert "2";
BA_ "GenSigCycleTime" SG_ 2499751697 RearPropulsionStat_Rear3Axle_ISi 100;
BA_ "GenSigCycleTimeActive" SG_ 2499751697 RearPropulsionStat_Rear3Axle_ISi 100;
BA_ "GenSigStartValue" SG_ 2499751697 RearPropulsionStat_Rear3Axle_ISi 15;
BA_ "Platform_VMCU1_Sig" SG_ 2499751697 RearPropulsionStat_Rear3Axle_ISi 1;
BA_ "SystemSignalLongSymbol" SG_ 2499751697 RearPropulsionStat_Rear3Axle_ISi "RearPropulsionStat_Rear3Axle_ISig_3";
BA_ "GenSigSendType" SG_ 2499751697 RearAxle3DiffLock_stat_UB_ISig_3 7;
BA_ "GenSigCycleTime" SG_ 2499751697 DifferentialLockStateFrAxle2 100;
BA_ "GenSigCycleTimeActive" SG_ 2499751697 DifferentialLockStateFrAxle2 100;
BA_ "GenSigStartValue" SG_ 2499751697 DifferentialLockStateFrAxle2 3;
BA_ "Platform_VMCU1_Sig" SG_ 2499751697 DifferentialLockStateFrAxle2 1;
BA_ "GenSigCycleTime" SG_ 2499751697 TrailerConnected_ISig_3 100;
BA_ "GenSigCycleTimeActive" SG_ 2499751697 TrailerConnected_ISig_3 100;
BA_ "GenSigStartValue" SG_ 2499751697 TrailerConnected_ISig_3 3;
BA_ "NeedsUpdateBit" SG_ 2499751697 TrailerConnected_ISig_3 1;
BA_ "Platform_VMCU1_Sig" SG_ 2499751697 TrailerConnected_ISig_3 1;
BA_ "GenSigCycleTime" SG_ 2499751697 TrailerWithoutABS_ISig_3 100;
BA_ "GenSigCycleTimeActive" SG_ 2499751697 TrailerWithoutABS_ISig_3 100;
BA_ "GenSigStartValue" SG_ 2499751697 TrailerWithoutABS_ISig_3 3;
BA_ "NeedsUpdateBit" SG_ 2499751697 TrailerWithoutABS_ISig_3 1;
BA_ "Platform_VMCU1_Sig" SG_ 2499751697 TrailerWithoutABS_ISig_3 1;
BA_ "SeToolAncestorID_SIGNAL" SG_ 2499751697 TrailerWithoutABS_ISig_3 "x0000001D0410CF7C";
BA_ "SeToolItemID_SIGNAL" SG_ 2499751697 TrailerWithoutABS_ISig_3 "x0000001D0410CF7C";
BA_ "SeToolName_SIGNAL" SG_ 2499751697 TrailerWithoutABS_ISig_3 "TrailerWithoutABS";
BA_ "SeToolVersion_SIGNAL" SG_ 2499751697 TrailerWithoutABS_ISig_3 "1";
BA_ "GenSigSendType" SG_ 2499751697 DifferentialLockStateFrAxle1_UB_ 7;
BA_ "Platform_VMCU1_Sig" SG_ 2499751697 DifferentialLockStateFrAxle1_UB_ 1;
BA_ "SystemSignalLongSymbol" SG_ 2499751697 DifferentialLockStateFrAxle1_UB_ "DifferentialLockStateFrAxle1_UB_ISig_3";
BA_ "GenSigCycleTime" SG_ 2499751697 DifferentialLockStateFrAxle1_ISi 100;
BA_ "GenSigCycleTimeActive" SG_ 2499751697 DifferentialLockStateFrAxle1_ISi 100;
BA_ "GenSigStartValue" SG_ 2499751697 DifferentialLockStateFrAxle1_ISi 3;
BA_ "NeedsUpdateBit" SG_ 2499751697 DifferentialLockStateFrAxle1_ISi 1;
BA_ "Platform_VMCU1_Sig" SG_ 2499751697 DifferentialLockStateFrAxle1_ISi 1;
BA_ "SystemSignalLongSymbol" SG_ 2499751697 DifferentialLockStateFrAxle1_ISi "DifferentialLockStateFrAxle1_ISig_3";
BA_ "GenSigSendType" SG_ 2499751697 RearAxle1DiffLock_stat_UB_ISig_3 7;
BA_ "Platform_VMCU1_Sig" SG_ 2499751697 RearAxle1DiffLock_stat_UB_ISig_3 1;
BA_ "GenSigCycleTime" SG_ 2499751697 RearPropulsionStat_Rear2Axle_ISi 100;
BA_ "GenSigCycleTimeActive" SG_ 2499751697 RearPropulsionStat_Rear2Axle_ISi 100;
BA_ "GenSigStartValue" SG_ 2499751697 RearPropulsionStat_Rear2Axle_ISi 15;
BA_ "Platform_VMCU1_Sig" SG_ 2499751697 RearPropulsionStat_Rear2Axle_ISi 1;
BA_ "SystemSignalLongSymbol" SG_ 2499751697 RearPropulsionStat_Rear2Axle_ISi "RearPropulsionStat_Rear2Axle_ISig_3";
BA_ "GenSigSendType" SG_ 2499751697 CentralRearDiffLock_stat_UB_ISig 7;
BA_ "Platform_VMCU1_Sig" SG_ 2499751697 CentralRearDiffLock_stat_UB_ISig 1;
BA_ "SystemSignalLongSymbol" SG_ 2499751697 CentralRearDiffLock_stat_UB_ISig "CentralRearDiffLock_stat_UB_ISig_3";
BA_ "GenSigCycleTime" SG_ 2499751697 RearAxle1DiffLock_stat_ISig_3 100;
BA_ "GenSigCycleTimeActive" SG_ 2499751697 RearAxle1DiffLock_stat_ISig_3 100;
BA_ "GenSigStartValue" SG_ 2499751697 RearAxle1DiffLock_stat_ISig_3 3;
BA_ "GenSigMaxLatency" SG_ 2499751697 RearAxle1DiffLock_stat_ISig_3 35;
BA_ "NeedsUpdateBit" SG_ 2499751697 RearAxle1DiffLock_stat_ISig_3 1;
BA_ "Platform_VMCU1_Sig" SG_ 2499751697 RearAxle1DiffLock_stat_ISig_3 1;
BA_ "SeToolAncestorID_SIGNAL" SG_ 2499751697 RearAxle1DiffLock_stat_ISig_3 "x0000001D041287FE";
BA_ "SeToolItemID_SIGNAL" SG_ 2499751697 RearAxle1DiffLock_stat_ISig_3 "x0000001D043FB883";
BA_ "SeToolName_SIGNAL" SG_ 2499751697 RearAxle1DiffLock_stat_ISig_3 "DifferentialLockState-RearAxle1";
BA_ "SeToolVersion_SIGNAL" SG_ 2499751697 RearAxle1DiffLock_stat_ISig_3 "2";
BA_ "GenSigCycleTime" SG_ 2499751697 HeadlampFan_stat_ISig_3 100;
BA_ "GenSigCycleTimeActive" SG_ 2499751697 HeadlampFan_stat_ISig_3 100;
BA_ "GenSigStartValue" SG_ 2499751697 HeadlampFan_stat_ISig_3 7;
BA_ "GenSigSendType" SG_ 2499751697 TrailerWithoutABS_UB_ISig_3 7;
BA_ "Platform_VMCU1_Sig" SG_ 2499751697 TrailerWithoutABS_UB_ISig_3 1;
BA_ "GenSigCycleTime" SG_ 2566897425 StretchBrakeEnable_rqst 100;
BA_ "GenSigCycleTimeActive" SG_ 2566897425 StretchBrakeEnable_rqst 100;
BA_ "GenSigStartValue" SG_ 2566897425 StretchBrakeEnable_rqst 7;
BA_ "Platform_VMCU1_Sig" SG_ 2566897425 StretchBrakeEnable_rqst 1;
BA_ "GenSigCycleTime" SG_ 2566897425 ExhManifAirInjectionInhibit_ISig 100;
BA_ "GenSigCycleTimeActive" SG_ 2566897425 ExhManifAirInjectionInhibit_ISig 100;
BA_ "GenSigStartValue" SG_ 2566897425 ExhManifAirInjectionInhibit_ISig 3;
BA_ "SystemSignalLongSymbol" SG_ 2566897425 ExhManifAirInjectionInhibit_ISig "ExhManifAirInjectionInhibit_ISig_3";
BA_ "GenSigCycleTime" SG_ 2566897425 FuelLevel_ISig_3 100;
BA_ "GenSigCycleTimeActive" SG_ 2566897425 FuelLevel_ISig_3 100;
BA_ "GenSigStartValue" SG_ 2566897425 FuelLevel_ISig_3 255;
BA_ "GenSigMaxLatency" SG_ 2566897425 FuelLevel_ISig_3 510;
BA_ "NeedsUpdateBit" SG_ 2566897425 FuelLevel_ISig_3 1;
BA_ "Platform_VMCU1_Sig" SG_ 2566897425 FuelLevel_ISig_3 1;
BA_ "SeToolAncestorID_SIGNAL" SG_ 2566897425 FuelLevel_ISig_3 "x0000001D0416974D";
BA_ "SeToolItemID_SIGNAL" SG_ 2566897425 FuelLevel_ISig_3 "x0000001D0416974D";
BA_ "SeToolName_SIGNAL" SG_ 2566897425 FuelLevel_ISig_3 "FuelLevel";
BA_ "SeToolVersion_SIGNAL" SG_ 2566897425 FuelLevel_ISig_3 "1";
BA_ "GenSigCycleTime" SG_ 2566897425 StaticTrailerBrake_rqst 100;
BA_ "GenSigCycleTimeActive" SG_ 2566897425 StaticTrailerBrake_rqst 100;
BA_ "GenSigStartValue" SG_ 2566897425 StaticTrailerBrake_rqst 3;
BA_ "Platform_VMCU1_Sig" SG_ 2566897425 StaticTrailerBrake_rqst 1;
BA_ "GenSigCycleTime" SG_ 2566897425 AxleLoadStatus 100;
BA_ "GenSigCycleTimeActive" SG_ 2566897425 AxleLoadStatus 100;
BA_ "GenSigStartValue" SG_ 2566897425 AxleLoadStatus 7;
BA_ "GenSigSendType" SG_ 2566897425 FuelLevel_UB_ISig_3 7;
BA_ "Platform_VMCU1_Sig" SG_ 2566897425 FuelLevel_UB_ISig_3 1;
BA_ "GenSigSendType" SG_ 2298429457 BrakePressureSensorDemand_UB_ISi 7;
BA_ "Platform_VMCU1_Sig" SG_ 2298429457 BrakePressureSensorDemand_UB_ISi 1;
BA_ "SystemSignalLongSymbol" SG_ 2298429457 BrakePressureSensorDemand_UB_ISi "BrakePressureSensorDemand_UB_ISig_3";
BA_ "GenSigCycleTime" SG_ 2298429457 SWBrakeSwitch_ISig_3 100;
BA_ "GenSigCycleTimeActive" SG_ 2298429457 SWBrakeSwitch_ISig_3 100;
BA_ "GenSigStartValue" SG_ 2298429457 SWBrakeSwitch_ISig_3 3;
BA_ "GenSigMaxLatency" SG_ 2298429457 SWBrakeSwitch_ISig_3 35;
BA_ "NeedsUpdateBit" SG_ 2298429457 SWBrakeSwitch_ISig_3 1;
BA_ "Platform_VMCU1_Sig" SG_ 2298429457 SWBrakeSwitch_ISig_3 1;
BA_ "SeToolAncestorID_SIGNAL" SG_ 2298429457 SWBrakeSwitch_ISig_3 "x0000001D0432AB74";
BA_ "SeToolItemID_SIGNAL" SG_ 2298429457 SWBrakeSwitch_ISig_3 "x0000001D0432AB74";
BA_ "SeToolName_SIGNAL" SG_ 2298429457 SWBrakeSwitch_ISig_3 "SWBrakeSwitch";
BA_ "SeToolVersion_SIGNAL" SG_ 2298429457 SWBrakeSwitch_ISig_3 "1";
BA_ "GenSigCycleTime" SG_ 2298429457 ClutchPedalPosition_ISig_3 100;
BA_ "GenSigCycleTimeActive" SG_ 2298429457 ClutchPedalPosition_ISig_3 100;
BA_ "GenSigStartValue" SG_ 2298429457 ClutchPedalPosition_ISig_3 255;
BA_ "Platform_VMCU1_Sig" SG_ 2298429457 ClutchPedalPosition_ISig_3 1;
BA_ "GenSigCycleTime" SG_ 2298429457 TransmissionOutputShaftSpeed_ISi 100;
BA_ "GenSigCycleTimeActive" SG_ 2298429457 TransmissionOutputShaftSpeed_ISi 100;
BA_ "GenSigStartValue" SG_ 2298429457 TransmissionOutputShaftSpeed_ISi 65535;
BA_ "Platform_VMCU1_Sig" SG_ 2298429457 TransmissionOutputShaftSpeed_ISi 1;
BA_ "SeToolAncestorID_SIGNAL" SG_ 2298429457 TransmissionOutputShaftSpeed_ISi "x0000001D0412AAA9";
BA_ "SeToolItemID_SIGNAL" SG_ 2298429457 TransmissionOutputShaftSpeed_ISi "x0000001D0412AAA9";
BA_ "SeToolName_SIGNAL" SG_ 2298429457 TransmissionOutputShaftSpeed_ISi "TransmissionOutputShaftSpeed";
BA_ "SeToolVersion_SIGNAL" SG_ 2298429457 TransmissionOutputShaftSpeed_ISi "1";
BA_ "SystemSignalLongSymbol" SG_ 2298429457 TransmissionOutputShaftSpeed_ISi "TransmissionOutputShaftSpeed_ISig_3";
BA_ "GenSigSendType" SG_ 2298429457 SWBrakeSwitch_UB_ISig_3 7;
BA_ "Platform_VMCU1_Sig" SG_ 2298429457 SWBrakeSwitch_UB_ISig_3 1;
BA_ "GenSigCycleTime" SG_ 2298429457 VehicleMode_ISig_3 100;
BA_ "GenSigCycleTimeActive" SG_ 2298429457 VehicleMode_ISig_3 100;
BA_ "GenSigStartValue" SG_ 2298429457 VehicleMode_ISig_3 15;
BA_ "NeedsUpdateBit" SG_ 2298429457 VehicleMode_ISig_3 1;
BA_ "Platform_VMCU1_Sig" SG_ 2298429457 VehicleMode_ISig_3 1;
BA_ "GenSigCycleTime" SG_ 2298429457 AcctrPedalKickDownSw_stat_ISig_3 100;
BA_ "GenSigCycleTimeActive" SG_ 2298429457 AcctrPedalKickDownSw_stat_ISig_3 100;
BA_ "GenSigStartValue" SG_ 2298429457 AcctrPedalKickDownSw_stat_ISig_3 3;
BA_ "GenSigMaxLatency" SG_ 2298429457 AcctrPedalKickDownSw_stat_ISig_3 35;
BA_ "Platform_VMCU1_Sig" SG_ 2298429457 AcctrPedalKickDownSw_stat_ISig_3 1;
BA_ "SeToolAncestorID_SIGNAL" SG_ 2298429457 AcctrPedalKickDownSw_stat_ISig_3 "x0000001D0414E38D";
BA_ "SeToolItemID_SIGNAL" SG_ 2298429457 AcctrPedalKickDownSw_stat_ISig_3 "x0000001D0428D480";
BA_ "SeToolName_SIGNAL" SG_ 2298429457 AcctrPedalKickDownSw_stat_ISig_3 "AcceleratorPedalKickDwnSwtchStat";
BA_ "SeToolVersion_SIGNAL" SG_ 2298429457 AcctrPedalKickDownSw_stat_ISig_3 "2";
BA_ "GenSigCycleTime" SG_ 2298429457 BrakePedalPosition_ISig_3 100;
BA_ "GenSigCycleTimeActive" SG_ 2298429457 BrakePedalPosition_ISig_3 100;
BA_ "GenSigStartValue" SG_ 2298429457 BrakePedalPosition_ISig_3 255;
BA_ "GenSigMaxLatency" SG_ 2298429457 BrakePedalPosition_ISig_3 100;
BA_ "Platform_VMCU1_Sig" SG_ 2298429457 BrakePedalPosition_ISig_3 1;
BA_ "SeToolAncestorID_SIGNAL" SG_ 2298429457 BrakePedalPosition_ISig_3 "x0000001D04104A99";
BA_ "SeToolItemID_SIGNAL" SG_ 2298429457 BrakePedalPosition_ISig_3 "x0000001D04104A99";
BA_ "SeToolName_SIGNAL" SG_ 2298429457 BrakePedalPosition_ISig_3 "BrakePedalPosition";
BA_ "SeToolVersion_SIGNAL" SG_ 2298429457 BrakePedalPosition_ISig_3 "1";
BA_ "GenSigSendType" SG_ 2298429457 VehicleMode_UB_ISig_3 7;
BA_ "Platform_VMCU1_Sig" SG_ 2298429457 VehicleMode_UB_ISig_3 1;
BA_ "GenSigCycleTime" SG_ 2298429457 BrakePressureSensorDemand_ISig_3 100;
BA_ "GenSigCycleTimeActive" SG_ 2298429457 BrakePressureSensorDemand_ISig_3 100;
BA_ "GenSigStartValue" SG_ 2298429457 BrakePressureSensorDemand_ISig_3 255;
BA_ "GenSigMaxLatency" SG_ 2298429457 BrakePressureSensorDemand_ISig_3 35;
BA_ "NeedsUpdateBit" SG_ 2298429457 BrakePressureSensorDemand_ISig_3 1;
BA_ "Platform_VMCU1_Sig" SG_ 2298429457 BrakePressureSensorDemand_ISig_3 1;
BA_ "SeToolAncestorID_SIGNAL" SG_ 2298429457 BrakePressureSensorDemand_ISig_3 "x0000001D0422D695";
BA_ "SeToolItemID_SIGNAL" SG_ 2298429457 BrakePressureSensorDemand_ISig_3 "x0000001D042FD0DC";
BA_ "SeToolName_SIGNAL" SG_ 2298429457 BrakePressureSensorDemand_ISig_3 "BrakePressureSensorDemand";
BA_ "SeToolVersion_SIGNAL" SG_ 2298429457 BrakePressureSensorDemand_ISig_3 "2";
BA_ "GenSigCycleTime" SG_ 2298429457 AcceleratorPedalLowIdleSwitch_IS 100;
BA_ "GenSigCycleTimeActive" SG_ 2298429457 AcceleratorPedalLowIdleSwitch_IS 100;
BA_ "GenSigStartValue" SG_ 2298429457 AcceleratorPedalLowIdleSwitch_IS 3;
BA_ "Platform_VMCU1_Sig" SG_ 2298429457 AcceleratorPedalLowIdleSwitch_IS 1;
BA_ "SeToolAncestorID_SIGNAL" SG_ 2298429457 AcceleratorPedalLowIdleSwitch_IS "x0000001D0414E508";
BA_ "SeToolItemID_SIGNAL" SG_ 2298429457 AcceleratorPedalLowIdleSwitch_IS "x0000001D0414E508";
BA_ "SeToolName_SIGNAL" SG_ 2298429457 AcceleratorPedalLowIdleSwitch_IS "AcceleratorPedalLowIdleSwitch";
BA_ "SeToolVersion_SIGNAL" SG_ 2298429457 AcceleratorPedalLowIdleSwitch_IS "1";
BA_ "SystemSignalLongSymbol" SG_ 2298429457 AcceleratorPedalLowIdleSwitch_IS "AcceleratorPedalLowIdleSwitch_ISig_3";
BA_ "GenSigCycleTime" SG_ 2298429457 AcceleratorPedalPosition1_ISig_3 100;
BA_ "GenSigCycleTimeActive" SG_ 2298429457 AcceleratorPedalPosition1_ISig_3 100;
BA_ "GenSigStartValue" SG_ 2298429457 AcceleratorPedalPosition1_ISig_3 255;
BA_ "GenSigMaxLatency" SG_ 2298429457 AcceleratorPedalPosition1_ISig_3 35;
BA_ "Platform_FactoryIf_Sig" SG_ 2298429457 AcceleratorPedalPosition1_ISig_3 1;
BA_ "Platform_VMCU1_Sig" SG_ 2298429457 AcceleratorPedalPosition1_ISig_3 1;
BA_ "SeToolAncestorID_SIGNAL" SG_ 2298429457 AcceleratorPedalPosition1_ISig_3 "x0000001D0410BACD";
BA_ "SeToolItemID_SIGNAL" SG_ 2298429457 AcceleratorPedalPosition1_ISig_3 "x0000001D04227E9E";
BA_ "SeToolName_SIGNAL" SG_ 2298429457 AcceleratorPedalPosition1_ISig_3 "AcceleratorPedalPosition1";
BA_ "SeToolVersion_SIGNAL" SG_ 2298429457 AcceleratorPedalPosition1_ISig_3 "2";
BA_ "GenSigCycleTime" SG_ 2566842385 VehicleDirSAE_VehSpeed 100;
BA_ "GenSigCycleTimeActive" SG_ 2566842385 VehicleDirSAE_VehSpeed 100;
BA_ "GenSigStartValue" SG_ 2566842385 VehicleDirSAE_VehSpeed 65535;
BA_ "SPN" SG_ 2566842385 VehicleDirSAE_VehSpeed 517;
BA_ "GenSigCycleTime" SG_ 2566842385 VehicleDirSAE_Altitude 100;
BA_ "GenSigCycleTimeActive" SG_ 2566842385 VehicleDirSAE_Altitude 100;
BA_ "GenSigStartValue" SG_ 2566842385 VehicleDirSAE_Altitude 65535;
BA_ "SPN" SG_ 2566842385 VehicleDirSAE_Altitude 580;
BA_ "GenSigCycleTime" SG_ 2566842385 VehicleDirSAE_Bearing 100;
BA_ "GenSigCycleTimeActive" SG_ 2566842385 VehicleDirSAE_Bearing 100;
BA_ "GenSigStartValue" SG_ 2566842385 VehicleDirSAE_Bearing 65535;
BA_ "SPN" SG_ 2566842385 VehicleDirSAE_Bearing 165;
BA_ "GenSigCycleTime" SG_ 2566842385 VehicleDirSAE_Pitch 100;
BA_ "GenSigCycleTimeActive" SG_ 2566842385 VehicleDirSAE_Pitch 100;
BA_ "GenSigStartValue" SG_ 2566842385 VehicleDirSAE_Pitch 65535;
BA_ "SPN" SG_ 2566842385 VehicleDirSAE_Pitch 583;
BA_ "GenSigCycleTime" SG_ 2566842606 VehDirSpd_Altitude 100;
BA_ "GenSigCycleTimeActive" SG_ 2566842606 VehDirSpd_Altitude 100;
BA_ "GenSigStartValue" SG_ 2566842606 VehDirSpd_Altitude 65535;
BA_ "GenSigCycleTime" SG_ 2566842606 VehDirSpd_VehSpeed 100;
BA_ "GenSigCycleTimeActive" SG_ 2566842606 VehDirSpd_VehSpeed 100;
BA_ "GenSigStartValue" SG_ 2566842606 VehDirSpd_VehSpeed 65535;
BA_ "GenSigCycleTime" SG_ 2566842606 VehDirSpd_Bearing 100;
BA_ "GenSigCycleTimeActive" SG_ 2566842606 VehDirSpd_Bearing 100;
BA_ "GenSigStartValue" SG_ 2566842606 VehDirSpd_Bearing 65535;
BA_ "GenSigCycleTime" SG_ 2566842606 VehDirSpd_Pitch 100;
BA_ "GenSigCycleTimeActive" SG_ 2566842606 VehDirSpd_Pitch 100;
BA_ "GenSigStartValue" SG_ 2566842606 VehDirSpd_Pitch 65535;
BA_ "GenSigSendType" SG_ 2566849262 DurationOfCurrentDailyRest_ISig_ 3;
BA_ "GenSigStartValue" SG_ 2566849262 DurationOfCurrentDailyRest_ISig_ 65535;
BA_ "SystemSignalLongSymbol" SG_ 2566849262 DurationOfCurrentDailyRest_ISig_ "DurationOfCurrentDailyRest_ISig_3";
BA_ "GenSigSendType" SG_ 2566849262 DetectReducWeeklyRestsForCurWk_I 3;
BA_ "GenSigStartValue" SG_ 2566849262 DetectReducWeeklyRestsForCurWk_I 15;
BA_ "SystemSignalLongSymbol" SG_ 2566849262 DetectReducWeeklyRestsForCurWk_I "DetectReducWeeklyRestsForCurWk_ISig_3";
BA_ "GenSigSendType" SG_ 2566849262 CurrentWeekWorkTime_ISig_3 3;
BA_ "GenSigStartValue" SG_ 2566849262 CurrentWeekWorkTime_ISig_3 65535;
BA_ "GenSigSendType" SG_ 2566849262 DetectRegWeeklyRestsForCurWk_ISi 3;
BA_ "GenSigStartValue" SG_ 2566849262 DetectRegWeeklyRestsForCurWk_ISi 15;
BA_ "SystemSignalLongSymbol" SG_ 2566849262 DetectRegWeeklyRestsForCurWk_ISi "DetectRegWeeklyRestsForCurWk_ISig_3";
BA_ "GenSigSendType" SG_ 2566849262 Drv1CumulativeBreakTime_VDO2_ISi 3;
BA_ "GenSigStartValue" SG_ 2566849262 Drv1CumulativeBreakTime_VDO2_ISi 65535;
BA_ "SystemSignalLongSymbol" SG_ 2566849262 Drv1CumulativeBreakTime_VDO2_ISi "Drv1CumulativeBreakTime_VDO2_ISig_3";
BA_ "GenSigSendType" SG_ 2566849262 Drv1ContinuousDrivingTime_VDO2_I 3;
BA_ "GenSigStartValue" SG_ 2566849262 Drv1ContinuousDrivingTime_VDO2_I 65535;
BA_ "SystemSignalLongSymbol" SG_ 2566849262 Drv1ContinuousDrivingTime_VDO2_I "Drv1ContinuousDrivingTime_VDO2_ISig_3";
BA_ "GenSigSendType" SG_ 2566849262 DailyDrivingTime_VDO2_ISig_3 3;
BA_ "GenSigStartValue" SG_ 2566849262 DailyDrivingTime_VDO2_ISig_3 65535;
BA_ "GenSigSendType" SG_ 2566849262 DetectReducWeeklyRestsForLastW_I 3;
BA_ "GenSigStartValue" SG_ 2566849262 DetectReducWeeklyRestsForLastW_I 15;
BA_ "SystemSignalLongSymbol" SG_ 2566849262 DetectReducWeeklyRestsForLastW_I "DetectReducWeeklyRestsForLastW_ISig_3";
BA_ "GenSigSendType" SG_ 2566849262 TwoWeekDrvingTime_VDO2_ISig_3 3;
BA_ "GenSigStartValue" SG_ 2566849262 TwoWeekDrvingTime_VDO2_ISig_3 65535;
BA_ "GenSigSendType" SG_ 2566849262 CurrentDailyWorkTime_ISig_3 3;
BA_ "GenSigStartValue" SG_ 2566849262 CurrentDailyWorkTime_ISig_3 65535;
BA_ "GenSigSendType" SG_ 2566849262 DetectRegWeeklyRestsForLastW_ISi 3;
BA_ "GenSigStartValue" SG_ 2566849262 DetectRegWeeklyRestsForLastW_ISi 15;
BA_ "SystemSignalLongSymbol" SG_ 2566849262 DetectRegWeeklyRestsForLastW_ISi "DetectRegWeeklyRestsForLastW_ISig_3";
BA_ "GenSigSendType" SG_ 2566849262 WeeklyDrivingTime_VDO2_ISig_3 3;
BA_ "GenSigStartValue" SG_ 2566849262 WeeklyDrivingTime_VDO2_ISig_3 65535;
BA_ "GenSigSendType" SG_ 2566849262 DurationOfCurrentWeeklyRest_ISig 3;
BA_ "GenSigStartValue" SG_ 2566849262 DurationOfCurrentWeeklyRest_ISig 65535;
BA_ "SystemSignalLongSymbol" SG_ 2566849262 DurationOfCurrentWeeklyRest_ISig "DurationOfCurrentWeeklyRest_ISig_3";
BA_ "GenSigSendType" SG_ 2566906094 RemningTimeTillNxtWklyRestPrd_IS 1;
BA_ "GenSigCycleTime" SG_ 2566906094 RemningTimeTillNxtWklyRestPrd_IS 100;
BA_ "GenSigCycleTimeActive" SG_ 2566906094 RemningTimeTillNxtWklyRestPrd_IS 100;
BA_ "GenSigStartValue" SG_ 2566906094 RemningTimeTillNxtWklyRestPrd_IS 65535;
BA_ "Platform_VMCU1_Sig" SG_ 2566906094 RemningTimeTillNxtWklyRestPrd_IS 1;
BA_ "SystemSignalLongSymbol" SG_ 2566906094 RemningTimeTillNxtWklyRestPrd_IS "RemningTimeTillNxtWklyRestPrd_ISig_3";
BA_ "GenSigSendType" SG_ 2566906094 RemainingCurDailyDrivingTime_ISi 1;
BA_ "GenSigCycleTime" SG_ 2566906094 RemainingCurDailyDrivingTime_ISi 100;
BA_ "GenSigCycleTimeActive" SG_ 2566906094 RemainingCurDailyDrivingTime_ISi 100;
BA_ "GenSigStartValue" SG_ 2566906094 RemainingCurDailyDrivingTime_ISi 65535;
BA_ "Platform_VMCU1_Sig" SG_ 2566906094 RemainingCurDailyDrivingTime_ISi 1;
BA_ "SystemSignalLongSymbol" SG_ 2566906094 RemainingCurDailyDrivingTime_ISi "RemainingCurDailyDrivingTime_ISig_3";
BA_ "GenSigSendType" SG_ 2566906094 RemainingCurrentDrivingTime_ISig 1;
BA_ "GenSigCycleTime" SG_ 2566906094 RemainingCurrentDrivingTime_ISig 100;
BA_ "GenSigCycleTimeActive" SG_ 2566906094 RemainingCurrentDrivingTime_ISig 100;
BA_ "GenSigStartValue" SG_ 2566906094 RemainingCurrentDrivingTime_ISig 65535;
BA_ "Platform_VMCU1_Sig" SG_ 2566906094 RemainingCurrentDrivingTime_ISig 1;
BA_ "SystemSignalLongSymbol" SG_ 2566906094 RemainingCurrentDrivingTime_ISig "RemainingCurrentDrivingTime_ISig_3";
BA_ "GenSigSendType" SG_ 2566906094 SingleMultiDriver_ISig_3 1;
BA_ "GenSigCycleTime" SG_ 2566906094 SingleMultiDriver_ISig_3 100;
BA_ "GenSigCycleTimeActive" SG_ 2566906094 SingleMultiDriver_ISig_3 100;
BA_ "GenSigStartValue" SG_ 2566906094 SingleMultiDriver_ISig_3 3;
BA_ "Platform_VMCU1_Sig" SG_ 2566906094 SingleMultiDriver_ISig_3 1;
BA_ "GenSigSendType" SG_ 2566906094 UnknownPeriods_ISig_3 1;
BA_ "GenSigCycleTime" SG_ 2566906094 UnknownPeriods_ISig_3 100;
BA_ "GenSigCycleTimeActive" SG_ 2566906094 UnknownPeriods_ISig_3 100;
BA_ "GenSigStartValue" SG_ 2566906094 UnknownPeriods_ISig_3 3;
BA_ "Platform_VMCU1_Sig" SG_ 2566906094 UnknownPeriods_ISig_3 1;
BA_ "GenSigSendType" SG_ 2566906094 OpenCompensationWeekBfrLast_ISig 1;
BA_ "GenSigCycleTime" SG_ 2566906094 OpenCompensationWeekBfrLast_ISig 100;
BA_ "GenSigCycleTimeActive" SG_ 2566906094 OpenCompensationWeekBfrLast_ISig 100;
BA_ "GenSigStartValue" SG_ 2566906094 OpenCompensationWeekBfrLast_ISig 65535;
BA_ "Platform_VMCU1_Sig" SG_ 2566906094 OpenCompensationWeekBfrLast_ISig 1;
BA_ "SystemSignalLongSymbol" SG_ 2566906094 OpenCompensationWeekBfrLast_ISig "OpenCompensationWeekBfrLast_ISig_3";
BA_ "GenSigSendType" SG_ 2566906094 RemainingReducedDailyRestPrd_ISi 1;
BA_ "GenSigCycleTime" SG_ 2566906094 RemainingReducedDailyRestPrd_ISi 100;
BA_ "GenSigCycleTimeActive" SG_ 2566906094 RemainingReducedDailyRestPrd_ISi 100;
BA_ "GenSigStartValue" SG_ 2566906094 RemainingReducedDailyRestPrd_ISi 7;
BA_ "Platform_VMCU1_Sig" SG_ 2566906094 RemainingReducedDailyRestPrd_ISi 1;
BA_ "SystemSignalLongSymbol" SG_ 2566906094 RemainingReducedDailyRestPrd_ISi "RemainingReducedDailyRestPrd_ISig_3";
BA_ "GenSigSendType" SG_ 2566906094 RemainingDurOfCurBreakRest_ISig_ 1;
BA_ "GenSigCycleTime" SG_ 2566906094 RemainingDurOfCurBreakRest_ISig_ 100;
BA_ "GenSigCycleTimeActive" SG_ 2566906094 RemainingDurOfCurBreakRest_ISig_ 100;
BA_ "GenSigStartValue" SG_ 2566906094 RemainingDurOfCurBreakRest_ISig_ 65535;
BA_ "Platform_VMCU1_Sig" SG_ 2566906094 RemainingDurOfCurBreakRest_ISig_ 1;
BA_ "SystemSignalLongSymbol" SG_ 2566906094 RemainingDurOfCurBreakRest_ISig_ "RemainingDurOfCurBreakRest_ISig_3";
BA_ "GenSigSendType" SG_ 2566906094 RemainingTimeTillNextRestBreak_I 1;
BA_ "GenSigCycleTime" SG_ 2566906094 RemainingTimeTillNextRestBreak_I 100;
BA_ "GenSigCycleTimeActive" SG_ 2566906094 RemainingTimeTillNextRestBreak_I 100;
BA_ "GenSigStartValue" SG_ 2566906094 RemainingTimeTillNextRestBreak_I 65535;
BA_ "Platform_VMCU1_Sig" SG_ 2566906094 RemainingTimeTillNextRestBreak_I 1;
BA_ "SystemSignalLongSymbol" SG_ 2566906094 RemainingTimeTillNextRestBreak_I "RemainingTimeTillNextRestBreak_ISig_3";
BA_ "GenSigSendType" SG_ 2566906094 NextDrivingPeriod_ISig_3 1;
BA_ "GenSigCycleTime" SG_ 2566906094 NextDrivingPeriod_ISig_3 100;
BA_ "GenSigCycleTimeActive" SG_ 2566906094 NextDrivingPeriod_ISig_3 100;
BA_ "GenSigStartValue" SG_ 2566906094 NextDrivingPeriod_ISig_3 65535;
BA_ "Platform_VMCU1_Sig" SG_ 2566906094 NextDrivingPeriod_ISig_3 1;
BA_ "GenSigSendType" SG_ 2566906094 DurationOfNextRestBreak_ISig_3 1;
BA_ "GenSigCycleTime" SG_ 2566906094 DurationOfNextRestBreak_ISig_3 100;
BA_ "GenSigCycleTimeActive" SG_ 2566906094 DurationOfNextRestBreak_ISig_3 100;
BA_ "GenSigStartValue" SG_ 2566906094 DurationOfNextRestBreak_ISig_3 65535;
BA_ "Platform_VMCU1_Sig" SG_ 2566906094 DurationOfNextRestBreak_ISig_3 1;
BA_ "GenSigSendType" SG_ 2566906094 RemainingDrivTimeOfCurWeek_ISig_ 1;
BA_ "GenSigCycleTime" SG_ 2566906094 RemainingDrivTimeOfCurWeek_ISig_ 100;
BA_ "GenSigCycleTimeActive" SG_ 2566906094 RemainingDrivTimeOfCurWeek_ISig_ 100;
BA_ "GenSigStartValue" SG_ 2566906094 RemainingDrivTimeOfCurWeek_ISig_ 65535;
BA_ "Platform_VMCU1_Sig" SG_ 2566906094 RemainingDrivTimeOfCurWeek_ISig_ 1;
BA_ "SystemSignalLongSymbol" SG_ 2566906094 RemainingDrivTimeOfCurWeek_ISig_ "RemainingDrivTimeOfCurWeek_ISig_3";
BA_ "GenSigSendType" SG_ 2566906094 DurationOfNextDailyRestPeriod_IS 1;
BA_ "GenSigCycleTime" SG_ 2566906094 DurationOfNextDailyRestPeriod_IS 100;
BA_ "GenSigCycleTimeActive" SG_ 2566906094 DurationOfNextDailyRestPeriod_IS 100;
BA_ "GenSigStartValue" SG_ 2566906094 DurationOfNextDailyRestPeriod_IS 65535;
BA_ "Platform_VMCU1_Sig" SG_ 2566906094 DurationOfNextDailyRestPeriod_IS 1;
BA_ "SystemSignalLongSymbol" SG_ 2566906094 DurationOfNextDailyRestPeriod_IS "DurationOfNextDailyRestPeriod_ISig_3";
BA_ "GenSigSendType" SG_ 2566906094 OpenCompensationInTheLastWeek_IS 1;
BA_ "GenSigCycleTime" SG_ 2566906094 OpenCompensationInTheLastWeek_IS 100;
BA_ "GenSigCycleTimeActive" SG_ 2566906094 OpenCompensationInTheLastWeek_IS 100;
BA_ "GenSigStartValue" SG_ 2566906094 OpenCompensationInTheLastWeek_IS 65535;
BA_ "Platform_VMCU1_Sig" SG_ 2566906094 OpenCompensationInTheLastWeek_IS 1;
BA_ "SystemSignalLongSymbol" SG_ 2566906094 OpenCompensationInTheLastWeek_IS "OpenCompensationInTheLastWeek_ISig_3";
BA_ "GenSigSendType" SG_ 2566906094 TimeOverlap_ISig_3 1;
BA_ "GenSigStartValue" SG_ 2566906094 TimeOverlap_ISig_3 3;
BA_ "Platform_VMCU1_Sig" SG_ 2566906094 TimeOverlap_ISig_3 1;
BA_ "GenSigSendType" SG_ 2566906094 TimeBeforeStartOfNxtDrvngPrd_ISi 1;
BA_ "GenSigCycleTime" SG_ 2566906094 TimeBeforeStartOfNxtDrvngPrd_ISi 100;
BA_ "GenSigCycleTimeActive" SG_ 2566906094 TimeBeforeStartOfNxtDrvngPrd_ISi 100;
BA_ "GenSigStartValue" SG_ 2566906094 TimeBeforeStartOfNxtDrvngPrd_ISi 65535;
BA_ "Platform_VMCU1_Sig" SG_ 2566906094 TimeBeforeStartOfNxtDrvngPrd_ISi 1;
BA_ "SystemSignalLongSymbol" SG_ 2566906094 TimeBeforeStartOfNxtDrvngPrd_ISi "TimeBeforeStartOfNxtDrvngPrd_ISig_3";
BA_ "GenSigSendType" SG_ 2566906094 WklyRestPrdCalcEnabledDisabled_I 1;
BA_ "GenSigCycleTime" SG_ 2566906094 WklyRestPrdCalcEnabledDisabled_I 100;
BA_ "GenSigCycleTimeActive" SG_ 2566906094 WklyRestPrdCalcEnabledDisabled_I 100;
BA_ "GenSigStartValue" SG_ 2566906094 WklyRestPrdCalcEnabledDisabled_I 3;
BA_ "Platform_VMCU1_Sig" SG_ 2566906094 WklyRestPrdCalcEnabledDisabled_I 1;
BA_ "SystemSignalLongSymbol" SG_ 2566906094 WklyRestPrdCalcEnabledDisabled_I "WklyRestPrdCalcEnabledDisabled_ISig_3";
BA_ "GenSigSendType" SG_ 2566906094 Remaining10hDrvTime_ISig_3 1;
BA_ "GenSigCycleTime" SG_ 2566906094 Remaining10hDrvTime_ISig_3 100;
BA_ "GenSigCycleTimeActive" SG_ 2566906094 Remaining10hDrvTime_ISig_3 100;
BA_ "GenSigStartValue" SG_ 2566906094 Remaining10hDrvTime_ISig_3 7;
BA_ "Platform_VMCU1_Sig" SG_ 2566906094 Remaining10hDrvTime_ISig_3 1;
BA_ "GenSigSendType" SG_ 2566906094 RemnngTimeTillNxtDailyRestPrd_IS 1;
BA_ "GenSigCycleTime" SG_ 2566906094 RemnngTimeTillNxtDailyRestPrd_IS 100;
BA_ "GenSigCycleTimeActive" SG_ 2566906094 RemnngTimeTillNxtDailyRestPrd_IS 100;
BA_ "GenSigStartValue" SG_ 2566906094 RemnngTimeTillNxtDailyRestPrd_IS 65535;
BA_ "Platform_VMCU1_Sig" SG_ 2566906094 RemnngTimeTillNxtDailyRestPrd_IS 1;
BA_ "SystemSignalLongSymbol" SG_ 2566906094 RemnngTimeTillNxtDailyRestPrd_IS "RemnngTimeTillNxtDailyRestPrd_ISig_3";
BA_ "GenSigSendType" SG_ 2566906094 DurationOfNextWeeklyRestPeriod_I 1;
BA_ "GenSigCycleTime" SG_ 2566906094 DurationOfNextWeeklyRestPeriod_I 100;
BA_ "GenSigCycleTimeActive" SG_ 2566906094 DurationOfNextWeeklyRestPeriod_I 100;
BA_ "GenSigStartValue" SG_ 2566906094 DurationOfNextWeeklyRestPeriod_I 65535;
BA_ "Platform_VMCU1_Sig" SG_ 2566906094 DurationOfNextWeeklyRestPeriod_I 1;
BA_ "SystemSignalLongSymbol" SG_ 2566906094 DurationOfNextWeeklyRestPeriod_I "DurationOfNextWeeklyRestPeriod_ISig_3";
BA_ "GenSigSendType" SG_ 2566906094 OpenCompensation2ndWeekBfrLast_I 1;
BA_ "GenSigCycleTime" SG_ 2566906094 OpenCompensation2ndWeekBfrLast_I 100;
BA_ "GenSigCycleTimeActive" SG_ 2566906094 OpenCompensation2ndWeekBfrLast_I 100;
BA_ "GenSigStartValue" SG_ 2566906094 OpenCompensation2ndWeekBfrLast_I 65535;
BA_ "Platform_VMCU1_Sig" SG_ 2566906094 OpenCompensation2ndWeekBfrLast_I 1;
BA_ "SystemSignalLongSymbol" SG_ 2566906094 OpenCompensation2ndWeekBfrLast_I "OpenCompensation2ndWeekBfrLast_ISig_3";
BA_ "GenSigSendType" SG_ 2566906094 SufficientData_ISig_3 1;
BA_ "GenSigCycleTime" SG_ 2566906094 SufficientData_ISig_3 100;
BA_ "GenSigCycleTimeActive" SG_ 2566906094 SufficientData_ISig_3 100;
BA_ "GenSigStartValue" SG_ 2566906094 SufficientData_ISig_3 3;
BA_ "Platform_VMCU1_Sig" SG_ 2566906094 SufficientData_ISig_3 1;
BA_ "GenSigSendType" SG_ 2566849006 TypeOfNextBreakRest_ISig_3 3;
BA_ "GenSigStartValue" SG_ 2566849006 TypeOfNextBreakRest_ISig_3 63;
BA_ "GenSigSendType" SG_ 2566849006 CompensationinNextRestPrd_ISig_3 3;
BA_ "GenSigStartValue" SG_ 2566849006 CompensationinNextRestPrd_ISig_3 3;
BA_ "GenSigSendType" SG_ 2566849006 RemDrvTimeTillNxtWklyRestPrd_ISi 3;
BA_ "GenSigStartValue" SG_ 2566849006 RemDrvTimeTillNxtWklyRestPrd_ISi 65535;
BA_ "SystemSignalLongSymbol" SG_ 2566849006 RemDrvTimeTillNxtWklyRestPrd_ISi "RemDrvTimeTillNxtWklyRestPrd_ISig_3";
BA_ "GenSigCycleTime" SG_ 2566832401 TotalVehicleDistanceHighRes_ISig 100;
BA_ "GenSigCycleTimeActive" SG_ 2566832401 TotalVehicleDistanceHighRes_ISig 100;
BA_ "GenSigStartValue" SG_ 2566832401 TotalVehicleDistanceHighRes_ISig 4294967295;
BA_ "Platform_FactoryIf_Sig" SG_ 2566832401 TotalVehicleDistanceHighRes_ISig 1;
BA_ "Platform_VMCU1_Sig" SG_ 2566832401 TotalVehicleDistanceHighRes_ISig 1;
BA_ "SPN" SG_ 2566832401 TotalVehicleDistanceHighRes_ISig 917;
BA_ "SeToolAncestorID_SIGNAL" SG_ 2566832401 TotalVehicleDistanceHighRes_ISig "x0000001D04109E2B";
BA_ "SeToolItemID_SIGNAL" SG_ 2566832401 TotalVehicleDistanceHighRes_ISig "x0000001D04109E2B";
BA_ "SeToolName_SIGNAL" SG_ 2566832401 TotalVehicleDistanceHighRes_ISig "HighResolutionTotalVehicleDistance";
BA_ "SeToolVersion_SIGNAL" SG_ 2566832401 TotalVehicleDistanceHighRes_ISig "1";
BA_ "SystemSignalLongSymbol" SG_ 2566832401 TotalVehicleDistanceHighRes_ISig "TotalVehicleDistanceHighRes_ISig_3";
BA_ "GenSigCycleTime" SG_ 2566832622 TachoHighResTotalVehDistance 100;
BA_ "GenSigCycleTimeActive" SG_ 2566832622 TachoHighResTotalVehDistance 100;
BA_ "GenSigStartValue" SG_ 2566832622 TachoHighResTotalVehDistance 4294967295;
BA_ "Platform_VMCU1_Sig" SG_ 2566832622 TachoHighResTotalVehDistance 1;
BA_ "SPN" SG_ 2566832622 TachoHighResTotalVehDistance 917;
BA_ "SeToolAncestorID_SIGNAL" SG_ 2566832622 TachoHighResTotalVehDistance "x0000001D041A218B";
BA_ "SeToolItemID_SIGNAL" SG_ 2566832622 TachoHighResTotalVehDistance "x0000001D041A218B";
BA_ "SeToolName_SIGNAL" SG_ 2566832622 TachoHighResTotalVehDistance "TachographHighResolutionTotalVehicleDistance";
BA_ "SeToolVersion_SIGNAL" SG_ 2566832622 TachoHighResTotalVehDistance "1";
BA_ "GenSigCycleTime" SG_ 2566832407 HighResolutionTripDistance_ISig_ 100;
BA_ "GenSigCycleTimeActive" SG_ 2566832407 HighResolutionTripDistance_ISig_ 100;
BA_ "GenSigStartValue" SG_ 2566832407 HighResolutionTripDistance_ISig_ 4294967295;
BA_ "SystemSignalLongSymbol" SG_ 2566832407 HighResolutionTripDistance_ISig_ "HighResolutionTripDistance_ISig_3";
BA_ "GenSigCycleTime" SG_ 2364541195 LateralAcceleration_ISig_3 100;
BA_ "GenSigCycleTimeActive" SG_ 2364541195 LateralAcceleration_ISig_3 100;
BA_ "GenSigStartValue" SG_ 2364541195 LateralAcceleration_ISig_3 65535;
BA_ "Platform_VMCU1_Sig" SG_ 2364541195 LateralAcceleration_ISig_3 1;
BA_ "SPN" SG_ 2364541195 LateralAcceleration_ISig_3 1809;
BA_ "GenSigCycleTime" SG_ 2364541195 SteeringWheelAngle_ISig_3 100;
BA_ "GenSigCycleTimeActive" SG_ 2364541195 SteeringWheelAngle_ISig_3 100;
BA_ "GenSigStartValue" SG_ 2364541195 SteeringWheelAngle_ISig_3 65535;
BA_ "Platform_VMCU1_Sig" SG_ 2364541195 SteeringWheelAngle_ISig_3 1;
BA_ "SPN" SG_ 2364541195 SteeringWheelAngle_ISig_3 1807;
BA_ "SeToolAncestorID_SIGNAL" SG_ 2364541195 SteeringWheelAngle_ISig_3 "x0000001D041258E9";
BA_ "SeToolItemID_SIGNAL" SG_ 2364541195 SteeringWheelAngle_ISig_3 "x0000001D041258E9";
BA_ "SeToolName_SIGNAL" SG_ 2364541195 SteeringWheelAngle_ISig_3 "SteeringWheelAngle";
BA_ "SeToolVersion_SIGNAL" SG_ 2364541195 SteeringWheelAngle_ISig_3 "1";
BA_ "GenSigCycleTime" SG_ 2364541195 SteeringWheelTurnCounter_ISig_3 100;
BA_ "GenSigCycleTimeActive" SG_ 2364541195 SteeringWheelTurnCounter_ISig_3 100;
BA_ "GenSigStartValue" SG_ 2364541195 SteeringWheelTurnCounter_ISig_3 63;
BA_ "Platform_VMCU1_Sig" SG_ 2364541195 SteeringWheelTurnCounter_ISig_3 1;
BA_ "SPN" SG_ 2364541195 SteeringWheelTurnCounter_ISig_3 1811;
BA_ "GenSigCycleTime" SG_ 2364541195 SteeringWheelAngleSensorType_ISi 100;
BA_ "GenSigCycleTimeActive" SG_ 2364541195 SteeringWheelAngleSensorType_ISi 100;
BA_ "GenSigStartValue" SG_ 2364541195 SteeringWheelAngleSensorType_ISi 3;
BA_ "Platform_VMCU1_Sig" SG_ 2364541195 SteeringWheelAngleSensorType_ISi 1;
BA_ "SPN" SG_ 2364541195 SteeringWheelAngleSensorType_ISi 1812;
BA_ "SystemSignalLongSymbol" SG_ 2364541195 SteeringWheelAngleSensorType_ISi "SteeringWheelAngleSensorType_ISig_3";
BA_ "GenSigCycleTime" SG_ 2364541195 YawRate_ISig_3 100;
BA_ "GenSigCycleTimeActive" SG_ 2364541195 YawRate_ISig_3 100;
BA_ "GenSigStartValue" SG_ 2364541195 YawRate_ISig_3 65535;
BA_ "Platform_VMCU1_Sig" SG_ 2364541195 YawRate_ISig_3 1;
BA_ "SPN" SG_ 2364541195 YawRate_ISig_3 1808;
BA_ "SeToolAncestorID_SIGNAL" SG_ 2364541195 YawRate_ISig_3 "x0000001D04146F42";
BA_ "SeToolItemID_SIGNAL" SG_ 2364541195 YawRate_ISig_3 "x0000001D04146F42";
BA_ "SeToolName_SIGNAL" SG_ 2364541195 YawRate_ISig_3 "YawRate";
BA_ "SeToolVersion_SIGNAL" SG_ 2364541195 YawRate_ISig_3 "1";
BA_ "GenSigCycleTime" SG_ 2566803211 ESCHealthStatus_ISig_3 100;
BA_ "GenSigCycleTimeActive" SG_ 2566803211 ESCHealthStatus_ISig_3 100;
BA_ "GenSigStartValue" SG_ 2566803211 ESCHealthStatus_ISig_3 3;
BA_ "Platform_VMCU1_Sig" SG_ 2566803211 ESCHealthStatus_ISig_3 1;
BA_ "SPN" SG_ 2566803211 ESCHealthStatus_ISig_3 1813;
BA_ "GenSigCycleTime" SG_ 2566803211 ROPEngineControlActive_ISig_3 100;
BA_ "GenSigCycleTimeActive" SG_ 2566803211 ROPEngineControlActive_ISig_3 100;
BA_ "GenSigStartValue" SG_ 2566803211 ROPEngineControlActive_ISig_3 3;
BA_ "Platform_VMCU1_Sig" SG_ 2566803211 ROPEngineControlActive_ISig_3 1;
BA_ "SPN" SG_ 2566803211 ROPEngineControlActive_ISig_3 1816;
BA_ "GenSigCycleTime" SG_ 2566803211 YCEngineControlActive_ISig_3 100;
BA_ "GenSigCycleTimeActive" SG_ 2566803211 YCEngineControlActive_ISig_3 100;
BA_ "GenSigStartValue" SG_ 2566803211 YCEngineControlActive_ISig_3 3;
BA_ "Platform_VMCU1_Sig" SG_ 2566803211 YCEngineControlActive_ISig_3 1;
BA_ "SPN" SG_ 2566803211 YCEngineControlActive_ISig_3 1817;
BA_ "GenSigCycleTime" SG_ 2566803211 ROPBrakeControlActive_ISig_3 100;
BA_ "GenSigCycleTimeActive" SG_ 2566803211 ROPBrakeControlActive_ISig_3 100;
BA_ "GenSigStartValue" SG_ 2566803211 ROPBrakeControlActive_ISig_3 3;
BA_ "Platform_VMCU1_Sig" SG_ 2566803211 ROPBrakeControlActive_ISig_3 1;
BA_ "SPN" SG_ 2566803211 ROPBrakeControlActive_ISig_3 1818;
BA_ "GenSigCycleTime" SG_ 2566803211 YCBrakeControlActive_ISig_3 100;
BA_ "GenSigCycleTimeActive" SG_ 2566803211 YCBrakeControlActive_ISig_3 100;
BA_ "GenSigStartValue" SG_ 2566803211 YCBrakeControlActive_ISig_3 3;
BA_ "Platform_VMCU1_Sig" SG_ 2566803211 YCBrakeControlActive_ISig_3 1;
BA_ "SPN" SG_ 2566803211 YCBrakeControlActive_ISig_3 1819;
BA_ "GenSigCycleTime" SG_ 2566803211 VDCFullyOperational_ISig_3 100;
BA_ "GenSigCycleTimeActive" SG_ 2566803211 VDCFullyOperational_ISig_3 100;
BA_ "GenSigStartValue" SG_ 2566803211 VDCFullyOperational_ISig_3 3;
BA_ "GenSigMaxLatency" SG_ 2566803211 VDCFullyOperational_ISig_3 60;
BA_ "Platform_VMCU1_Sig" SG_ 2566803211 VDCFullyOperational_ISig_3 1;
BA_ "SPN" SG_ 2566803211 VDCFullyOperational_ISig_3 1814;
BA_ "SeToolAncestorID_SIGNAL" SG_ 2566803211 VDCFullyOperational_ISig_3 "x0000001D0414256F";
BA_ "SeToolItemID_SIGNAL" SG_ 2566803211 VDCFullyOperational_ISig_3 "x0000001D0414256F";
BA_ "SeToolName_SIGNAL" SG_ 2566803211 VDCFullyOperational_ISig_3 "VDCFullyOperational";
BA_ "SeToolVersion_SIGNAL" SG_ 2566803211 VDCFullyOperational_ISig_3 "1";
BA_ "GenSigSendType" SG_ 2675897544 TrailerDiagPhysResp_F4_C8_ISig_3 7;
BA_ "GenSigSendType" SG_ 2675897536 TrailerDiagPhysResp_F4_C0_ISig_3 7;
BA_ "GenSigSendType" SG_ 2675897528 TrailerDiagPhysResp_F4_B8_ISig_3 7;
BA_ "GenSigSendType" SG_ 2675897520 TrailerDiagPhysResp_F4_B0_ISig_3 7;
BA_ "GenSigSendType" SG_ 2675897512 TrailerDiagPhysResp_F4_A8_ISig_3 7;
BA_ "GenSigSendType" SG_ 2675897032 TrailerDiagPhysResp_F2_C8_ISig_3 7;
BA_ "GenSigSendType" SG_ 2675897024 TrailerDiagPhysResp_F2_C0_ISig_3 7;
BA_REL_ "GenSigFirstTimeoutTime" BU_SG_REL_ TECU SG_ 2349075373 XBRDACU_Urgency 3000;
BA_REL_ "GenSigTimeoutTime" BU_SG_REL_ TECU SG_ 2349075373 XBRDACU_Urgency 1200;
BA_REL_ "GenSigFirstTimeoutTime" BU_SG_REL_ TECU SG_ 2349075373 XBRDACU_EBIMode 3000;
BA_REL_ "GenSigTimeoutTime" BU_SG_REL_ TECU SG_ 2349075373 XBRDACU_EBIMode 1200;
BA_REL_ "GenSigFirstTimeoutTime" BU_SG_REL_ TECU SG_ 2349075373 XBRDACU_ExtAccelDemand 3000;
BA_REL_ "GenSigTimeoutTime" BU_SG_REL_ TECU SG_ 2349075373 XBRDACU_ExtAccelDemand 1200;
BA_REL_ "GenSigFirstTimeoutTime" BU_SG_REL_ TECU SG_ 2349075373 XBRDACU_MsgCounter 3000;
BA_REL_ "GenSigTimeoutTime" BU_SG_REL_ TECU SG_ 2349075373 XBRDACU_MsgCounter 1200;
BA_REL_ "GenSigFirstTimeoutTime" BU_SG_REL_ TECU SG_ 2349075373 XBRDACU_MsgChecksum 3000;
BA_REL_ "GenSigTimeoutTime" BU_SG_REL_ TECU SG_ 2349075373 XBRDACU_MsgChecksum 1200;
BA_REL_ "GenSigFirstTimeoutTime" BU_SG_REL_ TECU SG_ 2349075373 XBRDACU_ControlMode 3000;
BA_REL_ "GenSigTimeoutTime" BU_SG_REL_ TECU SG_ 2349075373 XBRDACU_ControlMode 1200;
BA_REL_ "GenSigFirstTimeoutTime" BU_SG_REL_ TECU SG_ 2349075373 XBRDACU_Priority 3000;
BA_REL_ "GenSigTimeoutTime" BU_SG_REL_ TECU SG_ 2349075373 XBRDACU_Priority 1200;
BA_REL_ "GenSigFirstTimeoutTime" BU_SG_REL_ BBM SG_ 2566848256 WaterInFuelAlarm_ISig_3 65000;
BA_REL_ "GenSigTimeoutTime" BU_SG_REL_ BBM SG_ 2566848256 WaterInFuelAlarm_ISig_3 60000;
BA_REL_ "GenSigFirstTimeoutTime" BU_SG_REL_ IC3 SG_ 2566848256 WaterInFuelAlarm_ISig_3 65000;
BA_REL_ "GenSigTimeoutTime" BU_SG_REL_ IC3 SG_ 2566848256 WaterInFuelAlarm_ISig_3 60000;
BA_REL_ "GenSigFirstTimeoutTime" BU_SG_REL_ IC3 SG_ 2583636718 Drvr2ManualEntryStatus 65535;
BA_REL_ "GenSigTimeoutTime" BU_SG_REL_ IC3 SG_ 2583636718 Drvr2ManualEntryStatus 65535;
BA_REL_ "GenSigFirstTimeoutTime" BU_SG_REL_ IC3 SG_ 2583636718 CurrentFerryTrainStatus 65535;
BA_REL_ "GenSigTimeoutTime" BU_SG_REL_ IC3 SG_ 2583636718 CurrentFerryTrainStatus 65535;
BA_REL_ "GenSigFirstTimeoutTime" BU_SG_REL_ IC3 SG_ 2583636718 Drvr1ManualEntryStatus 65535;
BA_REL_ "GenSigTimeoutTime" BU_SG_REL_ IC3 SG_ 2583636718 Drvr1ManualEntryStatus 65535;
BA_REL_ "GenSigFirstTimeoutTime" BU_SG_REL_ VMCU SG_ 2583635694 GNSSTime_Tacho 12000;
BA_REL_ "GenSigTimeoutTime" BU_SG_REL_ VMCU SG_ 2583635694 GNSSTime_Tacho 3000;
BA_REL_ "GenSigFirstTimeoutTime" BU_SG_REL_ VMCU SG_ 2583635694 GNSSLiveStatus_Tacho 12000;
BA_REL_ "GenSigTimeoutTime" BU_SG_REL_ VMCU SG_ 2583635694 GNSSLiveStatus_Tacho 3000;
BA_REL_ "GenSigFirstTimeoutTime" BU_SG_REL_ TECU SG_ 2566845201 VehiclePosSAE_Longitude 6000;
BA_REL_ "GenSigTimeoutTime" BU_SG_REL_ TECU SG_ 2566845201 VehiclePosSAE_Longitude 1500;
BA_REL_ "GenSigFirstTimeoutTime" BU_SG_REL_ TECU SG_ 2566845201 VehiclePosSAE_Latitude 6000;
BA_REL_ "GenSigTimeoutTime" BU_SG_REL_ TECU SG_ 2566845201 VehiclePosSAE_Latitude 1500;
BA_REL_ "GenSigFirstTimeoutTime" BU_SG_REL_ VMCU SG_ 2566845422 VehPos1_Latitude 12000;
BA_REL_ "GenSigTimeoutTime" BU_SG_REL_ VMCU SG_ 2566845422 VehPos1_Latitude 3000;
BA_REL_ "GenSigFirstTimeoutTime" BU_SG_REL_ VMCU SG_ 2566845422 VehPos1_Longitude 12000;
BA_REL_ "GenSigTimeoutTime" BU_SG_REL_ VMCU SG_ 2566845422 VehPos1_Longitude 3000;
BA_REL_ "GenSigFirstTimeoutTime" BU_SG_REL_ IC3 SG_ 2566901009 LNGConsumedPTO 3000;
BA_REL_ "GenSigTimeoutTime" BU_SG_REL_ IC3 SG_ 2566901009 LNGConsumedPTO 600;
BA_REL_ "GenSigFirstTimeoutTime" BU_SG_REL_ IC3 SG_ 2566901009 EngTrueIdleSpeedLNG 3000;
BA_REL_ "GenSigTimeoutTime" BU_SG_REL_ IC3 SG_ 2566901009 EngTrueIdleSpeedLNG 600;
BA_REL_ "GenSigFirstTimeoutTime" BU_SG_REL_ TECU SG_ 2499788567 DrvrRetarderBrakeBlending_rqst_I 3000;
BA_REL_ "GenSigTimeoutTime" BU_SG_REL_ TECU SG_ 2499788567 DrvrRetarderBrakeBlending_rqst_I 450;
BA_REL_ "GenSigFirstTimeoutTime" BU_SG_REL_ BBM SG_ 2499788567 DrvrRetarderBrakeBlending_rqst_I 3000;
BA_REL_ "GenSigTimeoutTime" BU_SG_REL_ BBM SG_ 2499788567 DrvrRetarderBrakeBlending_rqst_I 450;
BA_REL_ "GenSigFirstTimeoutTime" BU_SG_REL_ EBS SG_ 2499788567 DrvrRetarderBrakeBlending_rqst_I 3000;
BA_REL_ "GenSigTimeoutTime" BU_SG_REL_ EBS SG_ 2499788567 DrvrRetarderBrakeBlending_rqst_I 450;
BA_REL_ "GenSigFirstTimeoutTime" BU_SG_REL_ IC3 SG_ 2499788567 DrvrRetarderBrakeBlending_rqst_I 3000;
BA_REL_ "GenSigTimeoutTime" BU_SG_REL_ IC3 SG_ 2499788567 DrvrRetarderBrakeBlending_rqst_I 450;
BA_REL_ "GenSigFirstTimeoutTime" BU_SG_REL_ IC3 SG_ 2499788567 DrvrRetarderBrakeProgram_rqst_IS 3000;
BA_REL_ "GenSigTimeoutTime" BU_SG_REL_ IC3 SG_ 2499788567 DrvrRetarderBrakeProgram_rqst_IS 450;
BA_REL_ "GenSigFirstTimeoutTime" BU_SG_REL_ TECU SG_ 2499788567 DrvrRetarderBrakeProgram_rqst_IS 3000;
BA_REL_ "GenSigTimeoutTime" BU_SG_REL_ TECU SG_ 2499788567 DrvrRetarderBrakeProgram_rqst_IS 450;
BA_REL_ "GenSigFirstTimeoutTime" BU_SG_REL_ BBM SG_ 2499788567 DrvrRetarderBrakeProgram_rqst_IS 3000;
BA_REL_ "GenSigTimeoutTime" BU_SG_REL_ BBM SG_ 2499788567 DrvrRetarderBrakeProgram_rqst_IS 450;
BA_REL_ "GenSigFirstTimeoutTime" BU_SG_REL_ TECU SG_ 2499788567 GearLeverPositionBackup 3000;
BA_REL_ "GenSigTimeoutTime" BU_SG_REL_ TECU SG_ 2499788567 GearLeverPositionBackup 450;
BA_REL_ "GenSigFirstTimeoutTime" BU_SG_REL_ CIOM SG_ 2499788567 EHRearAxleSteeringFuncStatus 3000;
BA_REL_ "GenSigTimeoutTime" BU_SG_REL_ CIOM SG_ 2499788567 EHRearAxleSteeringFuncStatus 400;
BA_REL_ "GenSigFirstTimeoutTime" BU_SG_REL_ TECU SG_ 2499788567 GearLeverPos2Backup_Rqst 3000;
BA_REL_ "GenSigTimeoutTime" BU_SG_REL_ TECU SG_ 2499788567 GearLeverPos2Backup_Rqst 450;
BA_REL_ "GenSigFirstTimeoutTime" BU_SG_REL_ TECU SG_ 2499788567 GearLeverPos2Backup_SqC 3000;
BA_REL_ "GenSigTimeoutTime" BU_SG_REL_ TECU SG_ 2499788567 GearLeverPos2Backup_SqC 450;
BA_REL_ "GenSigFirstTimeoutTime" BU_SG_REL_ TECU SG_ 2499788567 GearLeverPos2Backup_CRC 3000;
BA_REL_ "GenSigTimeoutTime" BU_SG_REL_ TECU SG_ 2499788567 GearLeverPos2Backup_CRC 450;
BA_REL_ "GenSigFirstTimeoutTime" BU_SG_REL_ EBS SG_ 2499788567 DriverRetarderRequest_ISig_3 3000;
BA_REL_ "GenSigTimeoutTime" BU_SG_REL_ EBS SG_ 2499788567 DriverRetarderRequest_ISig_3 450;
BA_REL_ "GenSigFirstTimeoutTime" BU_SG_REL_ TECU SG_ 2499788567 DriverRetarderRequest_ISig_3 3000;
BA_REL_ "GenSigTimeoutTime" BU_SG_REL_ TECU SG_ 2499788567 DriverRetarderRequest_ISig_3 450;
BA_REL_ "GenSigFirstTimeoutTime" BU_SG_REL_ EMS SG_ 2499788567 DriverRetarderRequest_ISig_3 3000;
BA_REL_ "GenSigTimeoutTime" BU_SG_REL_ EMS SG_ 2499788567 DriverRetarderRequest_ISig_3 450;
BA_REL_ "GenSigFirstTimeoutTime" BU_SG_REL_ IC3 SG_ 2499788567 DriverRetarderRequest_ISig_3 3000;
BA_REL_ "GenSigTimeoutTime" BU_SG_REL_ IC3 SG_ 2499788567 DriverRetarderRequest_ISig_3 450;
BA_REL_ "GenSigFirstTimeoutTime" BU_SG_REL_ BBM SG_ 2499788567 DriverRetarderRequest_ISig_3 3000;
BA_REL_ "GenSigTimeoutTime" BU_SG_REL_ BBM SG_ 2499788567 DriverRetarderRequest_ISig_3 450;
BA_REL_ "GenSigFirstTimeoutTime" BU_SG_REL_ RECU_Virt SG_ 2499788567 DriverRetarderRequest_ISig_3 3000;
BA_REL_ "GenSigTimeoutTime" BU_SG_REL_ RECU_Virt SG_ 2499788567 DriverRetarderRequest_ISig_3 450;
BA_REL_ "GenSigFirstTimeoutTime" BU_SG_REL_ BBM SG_ 2499788567 AirDumpStatus_ISig_3 3000;
BA_REL_ "GenSigTimeoutTime" BU_SG_REL_ BBM SG_ 2499788567 AirDumpStatus_ISig_3 450;
BA_REL_ "GenSigFirstTimeoutTime" BU_SG_REL_ IC3 SG_ 2566899729 LoadCalibFail_Range_ISig_3 24000;
BA_REL_ "GenSigTimeoutTime" BU_SG_REL_ IC3 SG_ 2566899729 LoadCalibFail_Range_ISig_3 6000;
BA_REL_ "GenSigFirstTimeoutTime" BU_SG_REL_ IC3 SG_ 2566899729 LoadCalibFail_WrongVM_ISig_3 24000;
BA_REL_ "GenSigTimeoutTime" BU_SG_REL_ IC3 SG_ 2566899729 LoadCalibFail_WrongVM_ISig_3 6000;
BA_REL_ "GenSigFirstTimeoutTime" BU_SG_REL_ IC3 SG_ 2566899729 LoadCalibFail_InMotion_ISig_3 24000;
BA_REL_ "GenSigTimeoutTime" BU_SG_REL_ IC3 SG_ 2566899729 LoadCalibFail_InMotion_ISig_3 6000;
BA_REL_ "GenSigFirstTimeoutTime" BU_SG_REL_ IC3 SG_ 2566899729 LoadCalibFail_InternalFailure_IS 24000;
BA_REL_ "GenSigTimeoutTime" BU_SG_REL_ IC3 SG_ 2566899729 LoadCalibFail_InternalFailure_IS 6000;
BA_REL_ "GenSigFirstTimeoutTime" BU_SG_REL_ IC3 SG_ 2566899729 LoadCalibFail_OutOfMemory_ISig_3 24000;
BA_REL_ "GenSigTimeoutTime" BU_SG_REL_ IC3 SG_ 2566899729 LoadCalibFail_OutOfMemory_ISig_3 6000;
BA_REL_ "GenSigFirstTimeoutTime" BU_SG_REL_ EBS SG_ 2566899729 Trailer5CalibStoreReq_CalibType 24000;
BA_REL_ "GenSigTimeoutTime" BU_SG_REL_ EBS SG_ 2566899729 Trailer5CalibStoreReq_CalibType 6000;
BA_REL_ "GenSigFirstTimeoutTime" BU_SG_REL_ EBS SG_ 2566899729 Trailer5CalibStoreReq_AxleId 24000;
BA_REL_ "GenSigTimeoutTime" BU_SG_REL_ EBS SG_ 2566899729 Trailer5CalibStoreReq_AxleId 6000;
BA_REL_ "GenSigFirstTimeoutTime" BU_SG_REL_ IC3 SG_ 2566899729 LoadCalibrationFeedback_ISig_3 24000;
BA_REL_ "GenSigTimeoutTime" BU_SG_REL_ IC3 SG_ 2566899729 LoadCalibrationFeedback_ISig_3 6000;
BA_REL_ "GenSigFirstTimeoutTime" BU_SG_REL_ EBS SG_ 2566899729 Trailer5CalibStoreReq_ScaleLoad 24000;
BA_REL_ "GenSigTimeoutTime" BU_SG_REL_ EBS SG_ 2566899729 Trailer5CalibStoreReq_ScaleLoad 6000;
BA_REL_ "GenSigFirstTimeoutTime" BU_SG_REL_ IC3 SG_ 2566899729 LoadCalibFail_WrongHeight_ISig_3 24000;
BA_REL_ "GenSigTimeoutTime" BU_SG_REL_ IC3 SG_ 2566899729 LoadCalibFail_WrongHeight_ISig_3 6000;
BA_REL_ "GenSigFirstTimeoutTime" BU_SG_REL_ EBS SG_ 2566899473 Trailer4CalibStoreReq_AxleId 24000;
BA_REL_ "GenSigTimeoutTime" BU_SG_REL_ EBS SG_ 2566899473 Trailer4CalibStoreReq_AxleId 6000;
BA_REL_ "GenSigFirstTimeoutTime" BU_SG_REL_ EBS SG_ 2566899473 Trailer3CalibStoreReq_ScaleLoad 24000;
BA_REL_ "GenSigTimeoutTime" BU_SG_REL_ EBS SG_ 2566899473 Trailer3CalibStoreReq_ScaleLoad 6000;
BA_REL_ "GenSigFirstTimeoutTime" BU_SG_REL_ EBS SG_ 2566899473 Trailer3CalibStoreReq_CalibType 24000;
BA_REL_ "GenSigTimeoutTime" BU_SG_REL_ EBS SG_ 2566899473 Trailer3CalibStoreReq_CalibType 6000;
BA_REL_ "GenSigFirstTimeoutTime" BU_SG_REL_ EBS SG_ 2566899473 Trailer4CalibStoreReq_ScaleLoad 24000;
BA_REL_ "GenSigTimeoutTime" BU_SG_REL_ EBS SG_ 2566899473 Trailer4CalibStoreReq_ScaleLoad 6000;
BA_REL_ "GenSigFirstTimeoutTime" BU_SG_REL_ EBS SG_ 2566899473 Trailer4CalibStoreReq_CalibType 24000;
BA_REL_ "GenSigTimeoutTime" BU_SG_REL_ EBS SG_ 2566899473 Trailer4CalibStoreReq_CalibType 6000;
BA_REL_ "GenSigFirstTimeoutTime" BU_SG_REL_ EBS SG_ 2566899473 Trailer3CalibStoreReq_AxleId 24000;
BA_REL_ "GenSigTimeoutTime" BU_SG_REL_ EBS SG_ 2566899473 Trailer3CalibStoreReq_AxleId 6000;
BA_REL_ "GenSigFirstTimeoutTime" BU_SG_REL_ EBS SG_ 2566899217 Trailer1CalibStoreReq_ScaleLoad 24000;
BA_REL_ "GenSigTimeoutTime" BU_SG_REL_ EBS SG_ 2566899217 Trailer1CalibStoreReq_ScaleLoad 6000;
BA_REL_ "GenSigFirstTimeoutTime" BU_SG_REL_ EBS SG_ 2566899217 Trailer1CalibStoreReq_CalibType 24000;
BA_REL_ "GenSigTimeoutTime" BU_SG_REL_ EBS SG_ 2566899217 Trailer1CalibStoreReq_CalibType 6000;
BA_REL_ "GenSigFirstTimeoutTime" BU_SG_REL_ EBS SG_ 2566899217 Trailer1CalibStoreReq_AxleId 24000;
BA_REL_ "GenSigTimeoutTime" BU_SG_REL_ EBS SG_ 2566899217 Trailer1CalibStoreReq_AxleId 6000;
BA_REL_ "GenSigFirstTimeoutTime" BU_SG_REL_ EBS SG_ 2566899217 Trailer2CalibStoreReq_AxleId 24000;
BA_REL_ "GenSigTimeoutTime" BU_SG_REL_ EBS SG_ 2566899217 Trailer2CalibStoreReq_AxleId 6000;
BA_REL_ "GenSigFirstTimeoutTime" BU_SG_REL_ EBS SG_ 2566899217 Trailer2CalibStoreReq_CalibType 24000;
BA_REL_ "GenSigTimeoutTime" BU_SG_REL_ EBS SG_ 2566899217 Trailer2CalibStoreReq_CalibType 6000;
BA_REL_ "GenSigFirstTimeoutTime" BU_SG_REL_ EBS SG_ 2566899217 Trailer2CalibStoreReq_ScaleLoad 24000;
BA_REL_ "GenSigTimeoutTime" BU_SG_REL_ EBS SG_ 2566899217 Trailer2CalibStoreReq_ScaleLoad 6000;
BA_REL_ "GenSigFirstTimeoutTime" BU_SG_REL_ BBM SG_ 2499751697 RearAxle2DiffLock_stat_ISig_3 3000;
BA_REL_ "GenSigTimeoutTime" BU_SG_REL_ BBM SG_ 2499751697 RearAxle2DiffLock_stat_ISig_3 600;
BA_REL_ "GenSigFirstTimeoutTime" BU_SG_REL_ TECU SG_ 2499751697 RearAxle2DiffLock_stat_ISig_3 3000;
BA_REL_ "GenSigTimeoutTime" BU_SG_REL_ TECU SG_ 2499751697 RearAxle2DiffLock_stat_ISig_3 600;
BA_REL_ "GenSigFirstTimeoutTime" BU_SG_REL_ IC3 SG_ 2499751697 RearAxle2DiffLock_stat_ISig_3 3000;
BA_REL_ "GenSigTimeoutTime" BU_SG_REL_ IC3 SG_ 2499751697 RearAxle2DiffLock_stat_ISig_3 600;
BA_REL_ "GenSigFirstTimeoutTime" BU_SG_REL_ EMS SG_ 2499751697 EngineStopReqBackup 3000;
BA_REL_ "GenSigTimeoutTime" BU_SG_REL_ EMS SG_ 2499751697 EngineStopReqBackup 600;
BA_REL_ "GenSigFirstTimeoutTime" BU_SG_REL_ BBM SG_ 2499751697 DifferentialLockStateCentral_ISi 3000;
BA_REL_ "GenSigTimeoutTime" BU_SG_REL_ BBM SG_ 2499751697 DifferentialLockStateCentral_ISi 600;
BA_REL_ "GenSigFirstTimeoutTime" BU_SG_REL_ TECU SG_ 2499751697 DifferentialLockStateCentral_ISi 3000;
BA_REL_ "GenSigTimeoutTime" BU_SG_REL_ TECU SG_ 2499751697 DifferentialLockStateCentral_ISi 600;
BA_REL_ "GenSigFirstTimeoutTime" BU_SG_REL_ EBS SG_ 2499751697 DifferentialLockStateCentral_ISi 3000;
BA_REL_ "GenSigTimeoutTime" BU_SG_REL_ EBS SG_ 2499751697 DifferentialLockStateCentral_ISi 600;
BA_REL_ "GenSigFirstTimeoutTime" BU_SG_REL_ IC3 SG_ 2499751697 DifferentialLockStateCentral_ISi 3000;
BA_REL_ "GenSigTimeoutTime" BU_SG_REL_ IC3 SG_ 2499751697 DifferentialLockStateCentral_ISi 600;
BA_REL_ "GenSigFirstTimeoutTime" BU_SG_REL_ EMS SG_ 2499751697 DifferentialLockStateCentral_ISi 3000;
BA_REL_ "GenSigTimeoutTime" BU_SG_REL_ EMS SG_ 2499751697 DifferentialLockStateCentral_ISi 600;
BA_REL_ "GenSigFirstTimeoutTime" BU_SG_REL_ IC3 SG_ 2499751697 RrInterAxlDiffLockActvnFuncReq_I 3000;
BA_REL_ "GenSigTimeoutTime" BU_SG_REL_ IC3 SG_ 2499751697 RrInterAxlDiffLockActvnFuncReq_I 600;
BA_REL_ "GenSigFirstTimeoutTime" BU_SG_REL_ IC3 SG_ 2499751697 RearPropulsionStat_Rear1Axle_ISi 3000;
BA_REL_ "GenSigTimeoutTime" BU_SG_REL_ IC3 SG_ 2499751697 RearPropulsionStat_Rear1Axle_ISi 600;
BA_REL_ "GenSigFirstTimeoutTime" BU_SG_REL_ EBS SG_ 2499751697 RearPropulsionStat_Rear1Axle_ISi 3000;
BA_REL_ "GenSigTimeoutTime" BU_SG_REL_ EBS SG_ 2499751697 RearPropulsionStat_Rear1Axle_ISi 600;
BA_REL_ "GenSigFirstTimeoutTime" BU_SG_REL_ EMS SG_ 2499751697 RearPropulsionStat_Rear1Axle_ISi 3000;
BA_REL_ "GenSigTimeoutTime" BU_SG_REL_ EMS SG_ 2499751697 RearPropulsionStat_Rear1Axle_ISi 600;
BA_REL_ "GenSigFirstTimeoutTime" BU_SG_REL_ TECU SG_ 2499751697 RearPropulsionStat_Rear1Axle_ISi 3000;
BA_REL_ "GenSigTimeoutTime" BU_SG_REL_ TECU SG_ 2499751697 RearPropulsionStat_Rear1Axle_ISi 600;
BA_REL_ "GenSigFirstTimeoutTime" BU_SG_REL_ BBM SG_ 2499751697 RearPropulsionStat_Rear1Axle_ISi 3000;
BA_REL_ "GenSigTimeoutTime" BU_SG_REL_ BBM SG_ 2499751697 RearPropulsionStat_Rear1Axle_ISi 600;
BA_REL_ "GenSigFirstTimeoutTime" BU_SG_REL_ DACU SG_ 2499751697 RearPropulsionStat_Rear1Axle_ISi 3000;
BA_REL_ "GenSigTimeoutTime" BU_SG_REL_ DACU SG_ 2499751697 RearPropulsionStat_Rear1Axle_ISi 600;
BA_REL_ "GenSigFirstTimeoutTime" BU_SG_REL_ IC3 SG_ 2499751697 SetHSAOperation 3000;
BA_REL_ "GenSigTimeoutTime" BU_SG_REL_ IC3 SG_ 2499751697 SetHSAOperation 600;
BA_REL_ "GenSigFirstTimeoutTime" BU_SG_REL_ EBS SG_ 2499751697 SetHSAOperation 3000;
BA_REL_ "GenSigTimeoutTime" BU_SG_REL_ EBS SG_ 2499751697 SetHSAOperation 600;
BA_REL_ "GenSigFirstTimeoutTime" BU_SG_REL_ IC3 SG_ 2499751697 CentralRearDiffLock_stat_ISig_3 3000;
BA_REL_ "GenSigTimeoutTime" BU_SG_REL_ IC3 SG_ 2499751697 CentralRearDiffLock_stat_ISig_3 600;
BA_REL_ "GenSigFirstTimeoutTime" BU_SG_REL_ TECU SG_ 2499751697 CentralRearDiffLock_stat_ISig_3 3000;
BA_REL_ "GenSigTimeoutTime" BU_SG_REL_ TECU SG_ 2499751697 CentralRearDiffLock_stat_ISig_3 600;
BA_REL_ "GenSigFirstTimeoutTime" BU_SG_REL_ BBM SG_ 2499751697 CentralRearDiffLock_stat_ISig_3 3000;
BA_REL_ "GenSigTimeoutTime" BU_SG_REL_ BBM SG_ 2499751697 CentralRearDiffLock_stat_ISig_3 600;
BA_REL_ "GenSigFirstTimeoutTime" BU_SG_REL_ IC3 SG_ 2499751697 AutoPBRelease_stat_ISig_3 3000;
BA_REL_ "GenSigTimeoutTime" BU_SG_REL_ IC3 SG_ 2499751697 AutoPBRelease_stat_ISig_3 600;
BA_REL_ "GenSigFirstTimeoutTime" BU_SG_REL_ IC3 SG_ 2499751697 RearAxle3DiffLock_stat_ISig_3 3000;
BA_REL_ "GenSigTimeoutTime" BU_SG_REL_ IC3 SG_ 2499751697 RearAxle3DiffLock_stat_ISig_3 600;
BA_REL_ "GenSigFirstTimeoutTime" BU_SG_REL_ EBS SG_ 2499751697 DifferentialLockStateCentral2 3000;
BA_REL_ "GenSigTimeoutTime" BU_SG_REL_ EBS SG_ 2499751697 DifferentialLockStateCentral2 600;
BA_REL_ "GenSigFirstTimeoutTime" BU_SG_REL_ IC3 SG_ 2499751697 LowAirPressureAlert 3000;
BA_REL_ "GenSigTimeoutTime" BU_SG_REL_ IC3 SG_ 2499751697 LowAirPressureAlert 600;
BA_REL_ "GenSigFirstTimeoutTime" BU_SG_REL_ EMS SG_ 2499751697 LowAirPressureAlert 3000;
BA_REL_ "GenSigTimeoutTime" BU_SG_REL_ EMS SG_ 2499751697 LowAirPressureAlert 600;
BA_REL_ "GenSigFirstTimeoutTime" BU_SG_REL_ DACU SG_ 2499751697 RearPropulsionStat_Rear3Axle_ISi 3000;
BA_REL_ "GenSigTimeoutTime" BU_SG_REL_ DACU SG_ 2499751697 RearPropulsionStat_Rear3Axle_ISi 600;
BA_REL_ "GenSigFirstTimeoutTime" BU_SG_REL_ IC3 SG_ 2499751697 RearPropulsionStat_Rear3Axle_ISi 3000;
BA_REL_ "GenSigTimeoutTime" BU_SG_REL_ IC3 SG_ 2499751697 RearPropulsionStat_Rear3Axle_ISi 600;
BA_REL_ "GenSigFirstTimeoutTime" BU_SG_REL_ EMS SG_ 2499751697 RearPropulsionStat_Rear3Axle_ISi 3000;
BA_REL_ "GenSigTimeoutTime" BU_SG_REL_ EMS SG_ 2499751697 RearPropulsionStat_Rear3Axle_ISi 600;
BA_REL_ "GenSigFirstTimeoutTime" BU_SG_REL_ BBM SG_ 2499751697 RearPropulsionStat_Rear3Axle_ISi 3000;
BA_REL_ "GenSigTimeoutTime" BU_SG_REL_ BBM SG_ 2499751697 RearPropulsionStat_Rear3Axle_ISi 600;
BA_REL_ "GenSigFirstTimeoutTime" BU_SG_REL_ EBS SG_ 2499751697 RearPropulsionStat_Rear3Axle_ISi 3000;
BA_REL_ "GenSigTimeoutTime" BU_SG_REL_ EBS SG_ 2499751697 RearPropulsionStat_Rear3Axle_ISi 600;
BA_REL_ "GenSigFirstTimeoutTime" BU_SG_REL_ TECU SG_ 2499751697 RearPropulsionStat_Rear3Axle_ISi 3000;
BA_REL_ "GenSigTimeoutTime" BU_SG_REL_ TECU SG_ 2499751697 RearPropulsionStat_Rear3Axle_ISi 600;
BA_REL_ "GenSigFirstTimeoutTime" BU_SG_REL_ EBS SG_ 2499751697 DifferentialLockStateFrAxle2 3000;
BA_REL_ "GenSigTimeoutTime" BU_SG_REL_ EBS SG_ 2499751697 DifferentialLockStateFrAxle2 600;
BA_REL_ "GenSigFirstTimeoutTime" BU_SG_REL_ EBS SG_ 2499751697 TrailerConnected_ISig_3 3000;
BA_REL_ "GenSigTimeoutTime" BU_SG_REL_ EBS SG_ 2499751697 TrailerConnected_ISig_3 600;
BA_REL_ "GenSigFirstTimeoutTime" BU_SG_REL_ TECU SG_ 2499751697 TrailerWithoutABS_ISig_3 3000;
BA_REL_ "GenSigTimeoutTime" BU_SG_REL_ TECU SG_ 2499751697 TrailerWithoutABS_ISig_3 600;
BA_REL_ "GenSigFirstTimeoutTime" BU_SG_REL_ EMS SG_ 2499751697 TrailerWithoutABS_ISig_3 3000;
BA_REL_ "GenSigTimeoutTime" BU_SG_REL_ EMS SG_ 2499751697 TrailerWithoutABS_ISig_3 600;
BA_REL_ "GenSigFirstTimeoutTime" BU_SG_REL_ DACU SG_ 2499751697 TrailerWithoutABS_ISig_3 3000;
BA_REL_ "GenSigTimeoutTime" BU_SG_REL_ DACU SG_ 2499751697 TrailerWithoutABS_ISig_3 600;
BA_REL_ "GenSigFirstTimeoutTime" BU_SG_REL_ EBS SG_ 2499751697 TrailerWithoutABS_ISig_3 3000;
BA_REL_ "GenSigTimeoutTime" BU_SG_REL_ EBS SG_ 2499751697 TrailerWithoutABS_ISig_3 600;
BA_REL_ "GenSigFirstTimeoutTime" BU_SG_REL_ IC3 SG_ 2499751697 TrailerWithoutABS_ISig_3 3000;
BA_REL_ "GenSigTimeoutTime" BU_SG_REL_ IC3 SG_ 2499751697 TrailerWithoutABS_ISig_3 600;
BA_REL_ "GenSigFirstTimeoutTime" BU_SG_REL_ EBS SG_ 2499751697 DifferentialLockStateFrAxle1_ISi 3000;
BA_REL_ "GenSigTimeoutTime" BU_SG_REL_ EBS SG_ 2499751697 DifferentialLockStateFrAxle1_ISi 600;
BA_REL_ "GenSigFirstTimeoutTime" BU_SG_REL_ IC3 SG_ 2499751697 DifferentialLockStateFrAxle1_ISi 3000;
BA_REL_ "GenSigTimeoutTime" BU_SG_REL_ IC3 SG_ 2499751697 DifferentialLockStateFrAxle1_ISi 600;
BA_REL_ "GenSigFirstTimeoutTime" BU_SG_REL_ BBM SG_ 2499751697 DifferentialLockStateFrAxle1_ISi 3000;
BA_REL_ "GenSigTimeoutTime" BU_SG_REL_ BBM SG_ 2499751697 DifferentialLockStateFrAxle1_ISi 600;
BA_REL_ "GenSigFirstTimeoutTime" BU_SG_REL_ EBS SG_ 2499751697 RearPropulsionStat_Rear2Axle_ISi 3000;
BA_REL_ "GenSigTimeoutTime" BU_SG_REL_ EBS SG_ 2499751697 RearPropulsionStat_Rear2Axle_ISi 600;
BA_REL_ "GenSigFirstTimeoutTime" BU_SG_REL_ BBM SG_ 2499751697 RearPropulsionStat_Rear2Axle_ISi 3000;
BA_REL_ "GenSigTimeoutTime" BU_SG_REL_ BBM SG_ 2499751697 RearPropulsionStat_Rear2Axle_ISi 600;
BA_REL_ "GenSigFirstTimeoutTime" BU_SG_REL_ EMS SG_ 2499751697 RearPropulsionStat_Rear2Axle_ISi 3000;
BA_REL_ "GenSigTimeoutTime" BU_SG_REL_ EMS SG_ 2499751697 RearPropulsionStat_Rear2Axle_ISi 600;
BA_REL_ "GenSigFirstTimeoutTime" BU_SG_REL_ IC3 SG_ 2499751697 RearPropulsionStat_Rear2Axle_ISi 3000;
BA_REL_ "GenSigTimeoutTime" BU_SG_REL_ IC3 SG_ 2499751697 RearPropulsionStat_Rear2Axle_ISi 600;
BA_REL_ "GenSigFirstTimeoutTime" BU_SG_REL_ DACU SG_ 2499751697 RearPropulsionStat_Rear2Axle_ISi 3000;
BA_REL_ "GenSigTimeoutTime" BU_SG_REL_ DACU SG_ 2499751697 RearPropulsionStat_Rear2Axle_ISi 600;
BA_REL_ "GenSigFirstTimeoutTime" BU_SG_REL_ TECU SG_ 2499751697 RearPropulsionStat_Rear2Axle_ISi 3000;
BA_REL_ "GenSigTimeoutTime" BU_SG_REL_ TECU SG_ 2499751697 RearPropulsionStat_Rear2Axle_ISi 600;
BA_REL_ "GenSigFirstTimeoutTime" BU_SG_REL_ IC3 SG_ 2499751697 RearAxle1DiffLock_stat_ISig_3 3000;
BA_REL_ "GenSigTimeoutTime" BU_SG_REL_ IC3 SG_ 2499751697 RearAxle1DiffLock_stat_ISig_3 600;
BA_REL_ "GenSigFirstTimeoutTime" BU_SG_REL_ BBM SG_ 2499751697 RearAxle1DiffLock_stat_ISig_3 3000;
BA_REL_ "GenSigTimeoutTime" BU_SG_REL_ BBM SG_ 2499751697 RearAxle1DiffLock_stat_ISig_3 600;
BA_REL_ "GenSigFirstTimeoutTime" BU_SG_REL_ TECU SG_ 2499751697 RearAxle1DiffLock_stat_ISig_3 3000;
BA_REL_ "GenSigTimeoutTime" BU_SG_REL_ TECU SG_ 2499751697 RearAxle1DiffLock_stat_ISig_3 600;
BA_REL_ "GenSigFirstTimeoutTime" BU_SG_REL_ IC3 SG_ 2499751697 HeadlampFan_stat_ISig_3 3000;
BA_REL_ "GenSigTimeoutTime" BU_SG_REL_ IC3 SG_ 2499751697 HeadlampFan_stat_ISig_3 600;
BA_REL_ "GenSigFirstTimeoutTime" BU_SG_REL_ EBS SG_ 2566897425 StretchBrakeEnable_rqst 12000;
BA_REL_ "GenSigTimeoutTime" BU_SG_REL_ EBS SG_ 2566897425 StretchBrakeEnable_rqst 3000;
BA_REL_ "GenSigFirstTimeoutTime" BU_SG_REL_ EMS SG_ 2566897425 ExhManifAirInjectionInhibit_ISig 12000;
BA_REL_ "GenSigTimeoutTime" BU_SG_REL_ EMS SG_ 2566897425 ExhManifAirInjectionInhibit_ISig 3000;
BA_REL_ "GenSigFirstTimeoutTime" BU_SG_REL_ IC3 SG_ 2566897425 FuelLevel_ISig_3 11760;
BA_REL_ "GenSigTimeoutTime" BU_SG_REL_ IC3 SG_ 2566897425 FuelLevel_ISig_3 2940;
BA_REL_ "GenSigFirstTimeoutTime" BU_SG_REL_ BBM SG_ 2566897425 FuelLevel_ISig_3 11760;
BA_REL_ "GenSigTimeoutTime" BU_SG_REL_ BBM SG_ 2566897425 FuelLevel_ISig_3 2940;
BA_REL_ "GenSigFirstTimeoutTime" BU_SG_REL_ CIOM SG_ 2566897425 FuelLevel_ISig_3 11760;
BA_REL_ "GenSigTimeoutTime" BU_SG_REL_ CIOM SG_ 2566897425 FuelLevel_ISig_3 2940;
BA_REL_ "GenSigFirstTimeoutTime" BU_SG_REL_ EMS SG_ 2566897425 FuelLevel_ISig_3 12000;
BA_REL_ "GenSigTimeoutTime" BU_SG_REL_ EMS SG_ 2566897425 FuelLevel_ISig_3 3000;
BA_REL_ "GenSigFirstTimeoutTime" BU_SG_REL_ EBS SG_ 2566897425 StaticTrailerBrake_rqst 12000;
BA_REL_ "GenSigTimeoutTime" BU_SG_REL_ EBS SG_ 2566897425 StaticTrailerBrake_rqst 3000;
BA_REL_ "GenSigFirstTimeoutTime" BU_SG_REL_ IC3 SG_ 2566897425 AxleLoadStatus 12000;
BA_REL_ "GenSigTimeoutTime" BU_SG_REL_ IC3 SG_ 2566897425 AxleLoadStatus 3000;
BA_REL_ "GenSigFirstTimeoutTime" BU_SG_REL_ TECU SG_ 2566897425 AxleLoadStatus 12000;
BA_REL_ "GenSigTimeoutTime" BU_SG_REL_ TECU SG_ 2566897425 AxleLoadStatus 3000;
BA_REL_ "GenSigFirstTimeoutTime" BU_SG_REL_ EBS SG_ 2566897425 AxleLoadStatus 12000;
BA_REL_ "GenSigTimeoutTime" BU_SG_REL_ EBS SG_ 2566897425 AxleLoadStatus 3000;
BA_REL_ "GenSigFirstTimeoutTime" BU_SG_REL_ IC3 SG_ 2298429457 SWBrakeSwitch_ISig_3 3000;
BA_REL_ "GenSigTimeoutTime" BU_SG_REL_ IC3 SG_ 2298429457 SWBrakeSwitch_ISig_3 500;
BA_REL_ "GenSigFirstTimeoutTime" BU_SG_REL_ EBS SG_ 2298429457 SWBrakeSwitch_ISig_3 3000;
BA_REL_ "GenSigTimeoutTime" BU_SG_REL_ EBS SG_ 2298429457 SWBrakeSwitch_ISig_3 500;
BA_REL_ "GenSigFirstTimeoutTime" BU_SG_REL_ EBS SG_ 2298429457 ClutchPedalPosition_ISig_3 3000;
BA_REL_ "GenSigTimeoutTime" BU_SG_REL_ EBS SG_ 2298429457 ClutchPedalPosition_ISig_3 60;
BA_REL_ "GenSigFirstTimeoutTime" BU_SG_REL_ RECU_Virt SG_ 2298429457 TransmissionOutputShaftSpeed_ISi 3000;
BA_REL_ "GenSigTimeoutTime" BU_SG_REL_ RECU_Virt SG_ 2298429457 TransmissionOutputShaftSpeed_ISi 60;
BA_REL_ "GenSigFirstTimeoutTime" BU_SG_REL_ EMS SG_ 2298429457 TransmissionOutputShaftSpeed_ISi 3000;
BA_REL_ "GenSigTimeoutTime" BU_SG_REL_ EMS SG_ 2298429457 TransmissionOutputShaftSpeed_ISi 60;
BA_REL_ "GenSigFirstTimeoutTime" BU_SG_REL_ BBM SG_ 2298429457 TransmissionOutputShaftSpeed_ISi 3000;
BA_REL_ "GenSigTimeoutTime" BU_SG_REL_ BBM SG_ 2298429457 TransmissionOutputShaftSpeed_ISi 60;
BA_REL_ "GenSigFirstTimeoutTime" BU_SG_REL_ ACM SG_ 2298429457 VehicleMode_ISig_3 3000;
BA_REL_ "GenSigTimeoutTime" BU_SG_REL_ ACM SG_ 2298429457 VehicleMode_ISig_3 500;
BA_REL_ "GenSigFirstTimeoutTime" BU_SG_REL_ IC3 SG_ 2298429457 VehicleMode_ISig_3 3000;
BA_REL_ "GenSigTimeoutTime" BU_SG_REL_ IC3 SG_ 2298429457 VehicleMode_ISig_3 500;
BA_REL_ "GenSigFirstTimeoutTime" BU_SG_REL_ CIOM SG_ 2298429457 VehicleMode_ISig_3 3000;
BA_REL_ "GenSigTimeoutTime" BU_SG_REL_ CIOM SG_ 2298429457 VehicleMode_ISig_3 500;
BA_REL_ "GenSigFirstTimeoutTime" BU_SG_REL_ DACU SG_ 2298429457 VehicleMode_ISig_3 3000;
BA_REL_ "GenSigTimeoutTime" BU_SG_REL_ DACU SG_ 2298429457 VehicleMode_ISig_3 500;
BA_REL_ "GenSigFirstTimeoutTime" BU_SG_REL_ HPCU SG_ 2298429457 VehicleMode_ISig_3 3000;
BA_REL_ "GenSigTimeoutTime" BU_SG_REL_ HPCU SG_ 2298429457 VehicleMode_ISig_3 500;
BA_REL_ "GenSigFirstTimeoutTime" BU_SG_REL_ TECU SG_ 2298429457 VehicleMode_ISig_3 3000;
BA_REL_ "GenSigTimeoutTime" BU_SG_REL_ TECU SG_ 2298429457 VehicleMode_ISig_3 500;
BA_REL_ "GenSigFirstTimeoutTime" BU_SG_REL_ TACHO SG_ 2298429457 VehicleMode_ISig_3 3000;
BA_REL_ "GenSigTimeoutTime" BU_SG_REL_ TACHO SG_ 2298429457 VehicleMode_ISig_3 500;
BA_REL_ "GenSigFirstTimeoutTime" BU_SG_REL_ EMS SG_ 2298429457 VehicleMode_ISig_3 3000;
BA_REL_ "GenSigTimeoutTime" BU_SG_REL_ EMS SG_ 2298429457 VehicleMode_ISig_3 500;
BA_REL_ "GenSigFirstTimeoutTime" BU_SG_REL_ BBM SG_ 2298429457 VehicleMode_ISig_3 3000;
BA_REL_ "GenSigTimeoutTime" BU_SG_REL_ BBM SG_ 2298429457 VehicleMode_ISig_3 500;
BA_REL_ "GenSigFirstTimeoutTime" BU_SG_REL_ EBS SG_ 2298429457 VehicleMode_ISig_3 3000;
BA_REL_ "GenSigTimeoutTime" BU_SG_REL_ EBS SG_ 2298429457 VehicleMode_ISig_3 500;
BA_REL_ "GenSigFirstTimeoutTime" BU_SG_REL_ BBM SG_ 2298429457 AcctrPedalKickDownSw_stat_ISig_3 3000;
BA_REL_ "GenSigTimeoutTime" BU_SG_REL_ BBM SG_ 2298429457 AcctrPedalKickDownSw_stat_ISig_3 60;
BA_REL_ "GenSigFirstTimeoutTime" BU_SG_REL_ TECU SG_ 2298429457 AcctrPedalKickDownSw_stat_ISig_3 3000;
BA_REL_ "GenSigTimeoutTime" BU_SG_REL_ TECU SG_ 2298429457 AcctrPedalKickDownSw_stat_ISig_3 60;
BA_REL_ "GenSigFirstTimeoutTime" BU_SG_REL_ IC3 SG_ 2298429457 AcctrPedalKickDownSw_stat_ISig_3 3000;
BA_REL_ "GenSigTimeoutTime" BU_SG_REL_ IC3 SG_ 2298429457 AcctrPedalKickDownSw_stat_ISig_3 100;
BA_REL_ "GenSigFirstTimeoutTime" BU_SG_REL_ EMS SG_ 2298429457 AcctrPedalKickDownSw_stat_ISig_3 3000;
BA_REL_ "GenSigTimeoutTime" BU_SG_REL_ EMS SG_ 2298429457 AcctrPedalKickDownSw_stat_ISig_3 60;
BA_REL_ "GenSigFirstTimeoutTime" BU_SG_REL_ DACU SG_ 2298429457 AcctrPedalKickDownSw_stat_ISig_3 3000;
BA_REL_ "GenSigTimeoutTime" BU_SG_REL_ DACU SG_ 2298429457 AcctrPedalKickDownSw_stat_ISig_3 60;
BA_REL_ "GenSigFirstTimeoutTime" BU_SG_REL_ IC3 SG_ 2298429457 BrakePedalPosition_ISig_3 3000;
BA_REL_ "GenSigTimeoutTime" BU_SG_REL_ IC3 SG_ 2298429457 BrakePedalPosition_ISig_3 60;
BA_REL_ "GenSigFirstTimeoutTime" BU_SG_REL_ TECU SG_ 2298429457 BrakePedalPosition_ISig_3 3000;
BA_REL_ "GenSigTimeoutTime" BU_SG_REL_ TECU SG_ 2298429457 BrakePedalPosition_ISig_3 60;
BA_REL_ "GenSigFirstTimeoutTime" BU_SG_REL_ EBS SG_ 2298429457 BrakePedalPosition_ISig_3 3000;
BA_REL_ "GenSigTimeoutTime" BU_SG_REL_ EBS SG_ 2298429457 BrakePedalPosition_ISig_3 60;
BA_REL_ "GenSigFirstTimeoutTime" BU_SG_REL_ CIOM SG_ 2298429457 BrakePedalPosition_ISig_3 3000;
BA_REL_ "GenSigTimeoutTime" BU_SG_REL_ CIOM SG_ 2298429457 BrakePedalPosition_ISig_3 60;
BA_REL_ "GenSigFirstTimeoutTime" BU_SG_REL_ DACU SG_ 2298429457 BrakePedalPosition_ISig_3 3000;
BA_REL_ "GenSigTimeoutTime" BU_SG_REL_ DACU SG_ 2298429457 BrakePedalPosition_ISig_3 60;
BA_REL_ "GenSigFirstTimeoutTime" BU_SG_REL_ BBM SG_ 2298429457 BrakePedalPosition_ISig_3 3000;
BA_REL_ "GenSigTimeoutTime" BU_SG_REL_ BBM SG_ 2298429457 BrakePedalPosition_ISig_3 60;
BA_REL_ "GenSigFirstTimeoutTime" BU_SG_REL_ EBS SG_ 2298429457 BrakePressureSensorDemand_ISig_3 3000;
BA_REL_ "GenSigTimeoutTime" BU_SG_REL_ EBS SG_ 2298429457 BrakePressureSensorDemand_ISig_3 500;
BA_REL_ "GenSigFirstTimeoutTime" BU_SG_REL_ IC3 SG_ 2298429457 AcceleratorPedalLowIdleSwitch_IS 3000;
BA_REL_ "GenSigTimeoutTime" BU_SG_REL_ IC3 SG_ 2298429457 AcceleratorPedalLowIdleSwitch_IS 60;
BA_REL_ "GenSigFirstTimeoutTime" BU_SG_REL_ BBM SG_ 2298429457 AcceleratorPedalLowIdleSwitch_IS 3000;
BA_REL_ "GenSigTimeoutTime" BU_SG_REL_ BBM SG_ 2298429457 AcceleratorPedalLowIdleSwitch_IS 60;
BA_REL_ "GenSigFirstTimeoutTime" BU_SG_REL_ TECU SG_ 2298429457 AcceleratorPedalLowIdleSwitch_IS 3000;
BA_REL_ "GenSigTimeoutTime" BU_SG_REL_ TECU SG_ 2298429457 AcceleratorPedalLowIdleSwitch_IS 60;
BA_REL_ "GenSigFirstTimeoutTime" BU_SG_REL_ EMS SG_ 2298429457 AcceleratorPedalPosition1_ISig_3 3000;
BA_REL_ "GenSigTimeoutTime" BU_SG_REL_ EMS SG_ 2298429457 AcceleratorPedalPosition1_ISig_3 60;
BA_REL_ "GenSigFirstTimeoutTime" BU_SG_REL_ BBM SG_ 2298429457 AcceleratorPedalPosition1_ISig_3 3000;
BA_REL_ "GenSigTimeoutTime" BU_SG_REL_ BBM SG_ 2298429457 AcceleratorPedalPosition1_ISig_3 60;
BA_REL_ "GenSigFirstTimeoutTime" BU_SG_REL_ DACU SG_ 2298429457 AcceleratorPedalPosition1_ISig_3 3000;
BA_REL_ "GenSigTimeoutTime" BU_SG_REL_ DACU SG_ 2298429457 AcceleratorPedalPosition1_ISig_3 60;
BA_REL_ "GenSigFirstTimeoutTime" BU_SG_REL_ EBS SG_ 2298429457 AcceleratorPedalPosition1_ISig_3 3000;
BA_REL_ "GenSigTimeoutTime" BU_SG_REL_ EBS SG_ 2298429457 AcceleratorPedalPosition1_ISig_3 60;
BA_REL_ "GenSigFirstTimeoutTime" BU_SG_REL_ IC3 SG_ 2298429457 AcceleratorPedalPosition1_ISig_3 3000;
BA_REL_ "GenSigTimeoutTime" BU_SG_REL_ IC3 SG_ 2298429457 AcceleratorPedalPosition1_ISig_3 60;
BA_REL_ "GenSigFirstTimeoutTime" BU_SG_REL_ TECU SG_ 2298429457 AcceleratorPedalPosition1_ISig_3 3000;
BA_REL_ "GenSigTimeoutTime" BU_SG_REL_ TECU SG_ 2298429457 AcceleratorPedalPosition1_ISig_3 60;
BA_REL_ "GenSigFirstTimeoutTime" BU_SG_REL_ CIOM SG_ 2298429457 AcceleratorPedalPosition1_ISig_3 3000;
BA_REL_ "GenSigTimeoutTime" BU_SG_REL_ CIOM SG_ 2298429457 AcceleratorPedalPosition1_ISig_3 60;
BA_REL_ "GenSigFirstTimeoutTime" BU_SG_REL_ TECU SG_ 2566842385 VehicleDirSAE_VehSpeed 6000;
BA_REL_ "GenSigTimeoutTime" BU_SG_REL_ TECU SG_ 2566842385 VehicleDirSAE_VehSpeed 1500;
BA_REL_ "GenSigFirstTimeoutTime" BU_SG_REL_ TECU SG_ 2566842385 VehicleDirSAE_Altitude 6000;
BA_REL_ "GenSigTimeoutTime" BU_SG_REL_ TECU SG_ 2566842385 VehicleDirSAE_Altitude 1500;
BA_REL_ "GenSigFirstTimeoutTime" BU_SG_REL_ TECU SG_ 2566842385 VehicleDirSAE_Bearing 6000;
BA_REL_ "GenSigTimeoutTime" BU_SG_REL_ TECU SG_ 2566842385 VehicleDirSAE_Bearing 1500;
BA_REL_ "GenSigFirstTimeoutTime" BU_SG_REL_ TECU SG_ 2566842385 VehicleDirSAE_Pitch 6000;
BA_REL_ "GenSigTimeoutTime" BU_SG_REL_ TECU SG_ 2566842385 VehicleDirSAE_Pitch 1500;
BA_REL_ "GenSigFirstTimeoutTime" BU_SG_REL_ VMCU SG_ 2566842606 VehDirSpd_Altitude 12000;
BA_REL_ "GenSigTimeoutTime" BU_SG_REL_ VMCU SG_ 2566842606 VehDirSpd_Altitude 3000;
BA_REL_ "GenSigFirstTimeoutTime" BU_SG_REL_ VMCU SG_ 2566842606 VehDirSpd_VehSpeed 12000;
BA_REL_ "GenSigTimeoutTime" BU_SG_REL_ VMCU SG_ 2566842606 VehDirSpd_VehSpeed 3000;
BA_REL_ "GenSigFirstTimeoutTime" BU_SG_REL_ VMCU SG_ 2566842606 VehDirSpd_Bearing 12000;
BA_REL_ "GenSigTimeoutTime" BU_SG_REL_ VMCU SG_ 2566842606 VehDirSpd_Bearing 3000;
BA_REL_ "GenSigFirstTimeoutTime" BU_SG_REL_ VMCU SG_ 2566842606 VehDirSpd_Pitch 12000;
BA_REL_ "GenSigTimeoutTime" BU_SG_REL_ VMCU SG_ 2566842606 VehDirSpd_Pitch 3000;
BA_REL_ "GenSigFirstTimeoutTime" BU_SG_REL_ IC3 SG_ 2566849262 DurationOfCurrentDailyRest_ISig_ 65535;
BA_REL_ "GenSigTimeoutTime" BU_SG_REL_ IC3 SG_ 2566849262 DurationOfCurrentDailyRest_ISig_ 65535;
BA_REL_ "GenSigFirstTimeoutTime" BU_SG_REL_ IC3 SG_ 2566849262 DetectReducWeeklyRestsForCurWk_I 65535;
BA_REL_ "GenSigTimeoutTime" BU_SG_REL_ IC3 SG_ 2566849262 DetectReducWeeklyRestsForCurWk_I 65535;
BA_REL_ "GenSigFirstTimeoutTime" BU_SG_REL_ IC3 SG_ 2566849262 CurrentWeekWorkTime_ISig_3 65535;
BA_REL_ "GenSigTimeoutTime" BU_SG_REL_ IC3 SG_ 2566849262 CurrentWeekWorkTime_ISig_3 65535;
BA_REL_ "GenSigFirstTimeoutTime" BU_SG_REL_ IC3 SG_ 2566849262 DetectRegWeeklyRestsForCurWk_ISi 65535;
BA_REL_ "GenSigTimeoutTime" BU_SG_REL_ IC3 SG_ 2566849262 DetectRegWeeklyRestsForCurWk_ISi 65535;
BA_REL_ "GenSigFirstTimeoutTime" BU_SG_REL_ IC3 SG_ 2566849262 Drv1CumulativeBreakTime_VDO2_ISi 65535;
BA_REL_ "GenSigTimeoutTime" BU_SG_REL_ IC3 SG_ 2566849262 Drv1CumulativeBreakTime_VDO2_ISi 65535;
BA_REL_ "GenSigFirstTimeoutTime" BU_SG_REL_ IC3 SG_ 2566849262 Drv1ContinuousDrivingTime_VDO2_I 65535;
BA_REL_ "GenSigTimeoutTime" BU_SG_REL_ IC3 SG_ 2566849262 Drv1ContinuousDrivingTime_VDO2_I 65535;
BA_REL_ "GenSigFirstTimeoutTime" BU_SG_REL_ IC3 SG_ 2566849262 DailyDrivingTime_VDO2_ISig_3 65535;
BA_REL_ "GenSigTimeoutTime" BU_SG_REL_ IC3 SG_ 2566849262 DailyDrivingTime_VDO2_ISig_3 65535;
BA_REL_ "GenSigFirstTimeoutTime" BU_SG_REL_ IC3 SG_ 2566849262 DetectReducWeeklyRestsForLastW_I 65535;
BA_REL_ "GenSigTimeoutTime" BU_SG_REL_ IC3 SG_ 2566849262 DetectReducWeeklyRestsForLastW_I 65535;
BA_REL_ "GenSigFirstTimeoutTime" BU_SG_REL_ IC3 SG_ 2566849262 TwoWeekDrvingTime_VDO2_ISig_3 65535;
BA_REL_ "GenSigTimeoutTime" BU_SG_REL_ IC3 SG_ 2566849262 TwoWeekDrvingTime_VDO2_ISig_3 65535;
BA_REL_ "GenSigFirstTimeoutTime" BU_SG_REL_ IC3 SG_ 2566849262 CurrentDailyWorkTime_ISig_3 65535;
BA_REL_ "GenSigTimeoutTime" BU_SG_REL_ IC3 SG_ 2566849262 CurrentDailyWorkTime_ISig_3 65535;
BA_REL_ "GenSigFirstTimeoutTime" BU_SG_REL_ IC3 SG_ 2566849262 DetectRegWeeklyRestsForLastW_ISi 65535;
BA_REL_ "GenSigTimeoutTime" BU_SG_REL_ IC3 SG_ 2566849262 DetectRegWeeklyRestsForLastW_ISi 65535;
BA_REL_ "GenSigFirstTimeoutTime" BU_SG_REL_ IC3 SG_ 2566849262 WeeklyDrivingTime_VDO2_ISig_3 65535;
BA_REL_ "GenSigTimeoutTime" BU_SG_REL_ IC3 SG_ 2566849262 WeeklyDrivingTime_VDO2_ISig_3 65535;
BA_REL_ "GenSigFirstTimeoutTime" BU_SG_REL_ IC3 SG_ 2566849262 DurationOfCurrentWeeklyRest_ISig 65535;
BA_REL_ "GenSigTimeoutTime" BU_SG_REL_ IC3 SG_ 2566849262 DurationOfCurrentWeeklyRest_ISig 65535;
BA_REL_ "GenSigFirstTimeoutTime" BU_SG_REL_ IC3 SG_ 2566906094 RemningTimeTillNxtWklyRestPrd_IS 65535;
BA_REL_ "GenSigTimeoutTime" BU_SG_REL_ IC3 SG_ 2566906094 RemningTimeTillNxtWklyRestPrd_IS 65535;
BA_REL_ "GenSigFirstTimeoutTime" BU_SG_REL_ IC3 SG_ 2566906094 RemainingCurDailyDrivingTime_ISi 65535;
BA_REL_ "GenSigTimeoutTime" BU_SG_REL_ IC3 SG_ 2566906094 RemainingCurDailyDrivingTime_ISi 65535;
BA_REL_ "GenSigFirstTimeoutTime" BU_SG_REL_ IC3 SG_ 2566906094 RemainingCurrentDrivingTime_ISig 65535;
BA_REL_ "GenSigTimeoutTime" BU_SG_REL_ IC3 SG_ 2566906094 RemainingCurrentDrivingTime_ISig 65535;
BA_REL_ "GenSigFirstTimeoutTime" BU_SG_REL_ IC3 SG_ 2566906094 SingleMultiDriver_ISig_3 65535;
BA_REL_ "GenSigTimeoutTime" BU_SG_REL_ IC3 SG_ 2566906094 SingleMultiDriver_ISig_3 65535;
BA_REL_ "GenSigFirstTimeoutTime" BU_SG_REL_ IC3 SG_ 2566906094 UnknownPeriods_ISig_3 65535;
BA_REL_ "GenSigTimeoutTime" BU_SG_REL_ IC3 SG_ 2566906094 UnknownPeriods_ISig_3 65535;
BA_REL_ "GenSigFirstTimeoutTime" BU_SG_REL_ IC3 SG_ 2566906094 OpenCompensationWeekBfrLast_ISig 65535;
BA_REL_ "GenSigTimeoutTime" BU_SG_REL_ IC3 SG_ 2566906094 OpenCompensationWeekBfrLast_ISig 65535;
BA_REL_ "GenSigFirstTimeoutTime" BU_SG_REL_ IC3 SG_ 2566906094 RemainingReducedDailyRestPrd_ISi 65535;
BA_REL_ "GenSigTimeoutTime" BU_SG_REL_ IC3 SG_ 2566906094 RemainingReducedDailyRestPrd_ISi 65535;
BA_REL_ "GenSigFirstTimeoutTime" BU_SG_REL_ IC3 SG_ 2566906094 RemainingDurOfCurBreakRest_ISig_ 65535;
BA_REL_ "GenSigTimeoutTime" BU_SG_REL_ IC3 SG_ 2566906094 RemainingDurOfCurBreakRest_ISig_ 65535;
BA_REL_ "GenSigFirstTimeoutTime" BU_SG_REL_ IC3 SG_ 2566906094 RemainingTimeTillNextRestBreak_I 65535;
BA_REL_ "GenSigTimeoutTime" BU_SG_REL_ IC3 SG_ 2566906094 RemainingTimeTillNextRestBreak_I 65535;
BA_REL_ "GenSigFirstTimeoutTime" BU_SG_REL_ IC3 SG_ 2566906094 NextDrivingPeriod_ISig_3 65535;
BA_REL_ "GenSigTimeoutTime" BU_SG_REL_ IC3 SG_ 2566906094 NextDrivingPeriod_ISig_3 65535;
BA_REL_ "GenSigFirstTimeoutTime" BU_SG_REL_ IC3 SG_ 2566906094 DurationOfNextRestBreak_ISig_3 65535;
BA_REL_ "GenSigTimeoutTime" BU_SG_REL_ IC3 SG_ 2566906094 DurationOfNextRestBreak_ISig_3 65535;
BA_REL_ "GenSigFirstTimeoutTime" BU_SG_REL_ IC3 SG_ 2566906094 RemainingDrivTimeOfCurWeek_ISig_ 65535;
BA_REL_ "GenSigTimeoutTime" BU_SG_REL_ IC3 SG_ 2566906094 RemainingDrivTimeOfCurWeek_ISig_ 65535;
BA_REL_ "GenSigFirstTimeoutTime" BU_SG_REL_ IC3 SG_ 2566906094 DurationOfNextDailyRestPeriod_IS 65535;
BA_REL_ "GenSigTimeoutTime" BU_SG_REL_ IC3 SG_ 2566906094 DurationOfNextDailyRestPeriod_IS 65535;
BA_REL_ "GenSigFirstTimeoutTime" BU_SG_REL_ IC3 SG_ 2566906094 OpenCompensationInTheLastWeek_IS 65535;
BA_REL_ "GenSigTimeoutTime" BU_SG_REL_ IC3 SG_ 2566906094 OpenCompensationInTheLastWeek_IS 65535;
BA_REL_ "GenSigFirstTimeoutTime" BU_SG_REL_ IC3 SG_ 2566906094 TimeOverlap_ISig_3 65535;
BA_REL_ "GenSigTimeoutTime" BU_SG_REL_ IC3 SG_ 2566906094 TimeOverlap_ISig_3 65535;
BA_REL_ "GenSigFirstTimeoutTime" BU_SG_REL_ IC3 SG_ 2566906094 TimeBeforeStartOfNxtDrvngPrd_ISi 65535;
BA_REL_ "GenSigTimeoutTime" BU_SG_REL_ IC3 SG_ 2566906094 TimeBeforeStartOfNxtDrvngPrd_ISi 65535;
BA_REL_ "GenSigFirstTimeoutTime" BU_SG_REL_ IC3 SG_ 2566906094 WklyRestPrdCalcEnabledDisabled_I 65535;
BA_REL_ "GenSigTimeoutTime" BU_SG_REL_ IC3 SG_ 2566906094 WklyRestPrdCalcEnabledDisabled_I 65535;
BA_REL_ "GenSigFirstTimeoutTime" BU_SG_REL_ IC3 SG_ 2566906094 Remaining10hDrvTime_ISig_3 65535;
BA_REL_ "GenSigTimeoutTime" BU_SG_REL_ IC3 SG_ 2566906094 Remaining10hDrvTime_ISig_3 65535;
BA_REL_ "GenSigFirstTimeoutTime" BU_SG_REL_ IC3 SG_ 2566906094 RemnngTimeTillNxtDailyRestPrd_IS 65535;
BA_REL_ "GenSigTimeoutTime" BU_SG_REL_ IC3 SG_ 2566906094 RemnngTimeTillNxtDailyRestPrd_IS 65535;
BA_REL_ "GenSigFirstTimeoutTime" BU_SG_REL_ IC3 SG_ 2566906094 DurationOfNextWeeklyRestPeriod_I 65535;
BA_REL_ "GenSigTimeoutTime" BU_SG_REL_ IC3 SG_ 2566906094 DurationOfNextWeeklyRestPeriod_I 65535;
BA_REL_ "GenSigFirstTimeoutTime" BU_SG_REL_ IC3 SG_ 2566906094 OpenCompensation2ndWeekBfrLast_I 65535;
BA_REL_ "GenSigTimeoutTime" BU_SG_REL_ IC3 SG_ 2566906094 OpenCompensation2ndWeekBfrLast_I 65535;
BA_REL_ "GenSigFirstTimeoutTime" BU_SG_REL_ IC3 SG_ 2566906094 SufficientData_ISig_3 65535;
BA_REL_ "GenSigTimeoutTime" BU_SG_REL_ IC3 SG_ 2566906094 SufficientData_ISig_3 65535;
BA_REL_ "GenSigFirstTimeoutTime" BU_SG_REL_ IC3 SG_ 2566849006 TypeOfNextBreakRest_ISig_3 65535;
BA_REL_ "GenSigTimeoutTime" BU_SG_REL_ IC3 SG_ 2566849006 TypeOfNextBreakRest_ISig_3 65535;
BA_REL_ "GenSigFirstTimeoutTime" BU_SG_REL_ IC3 SG_ 2566849006 CompensationinNextRestPrd_ISig_3 65535;
BA_REL_ "GenSigTimeoutTime" BU_SG_REL_ IC3 SG_ 2566849006 CompensationinNextRestPrd_ISig_3 65535;
BA_REL_ "GenSigFirstTimeoutTime" BU_SG_REL_ IC3 SG_ 2566849006 RemDrvTimeTillNxtWklyRestPrd_ISi 65535;
BA_REL_ "GenSigTimeoutTime" BU_SG_REL_ IC3 SG_ 2566849006 RemDrvTimeTillNxtWklyRestPrd_ISi 65535;
BA_REL_ "GenSigFirstTimeoutTime" BU_SG_REL_ IC3 SG_ 2566832401 TotalVehicleDistanceHighRes_ISig 24000;
BA_REL_ "GenSigTimeoutTime" BU_SG_REL_ IC3 SG_ 2566832401 TotalVehicleDistanceHighRes_ISig 6000;
BA_REL_ "GenSigFirstTimeoutTime" BU_SG_REL_ EBS SG_ 2566832401 TotalVehicleDistanceHighRes_ISig 24000;
BA_REL_ "GenSigTimeoutTime" BU_SG_REL_ EBS SG_ 2566832401 TotalVehicleDistanceHighRes_ISig 6000;
BA_REL_ "GenSigFirstTimeoutTime" BU_SG_REL_ EMS SG_ 2566832401 TotalVehicleDistanceHighRes_ISig 24000;
BA_REL_ "GenSigTimeoutTime" BU_SG_REL_ EMS SG_ 2566832401 TotalVehicleDistanceHighRes_ISig 6000;
BA_REL_ "GenSigFirstTimeoutTime" BU_SG_REL_ ACM SG_ 2566832401 TotalVehicleDistanceHighRes_ISig 24000;
BA_REL_ "GenSigTimeoutTime" BU_SG_REL_ ACM SG_ 2566832401 TotalVehicleDistanceHighRes_ISig 6000;
BA_REL_ "GenSigFirstTimeoutTime" BU_SG_REL_ DACU SG_ 2566832401 TotalVehicleDistanceHighRes_ISig 24000;
BA_REL_ "GenSigTimeoutTime" BU_SG_REL_ DACU SG_ 2566832401 TotalVehicleDistanceHighRes_ISig 6000;
BA_REL_ "GenSigFirstTimeoutTime" BU_SG_REL_ TECU SG_ 2566832401 TotalVehicleDistanceHighRes_ISig 24000;
BA_REL_ "GenSigTimeoutTime" BU_SG_REL_ TECU SG_ 2566832401 TotalVehicleDistanceHighRes_ISig 6000;
BA_REL_ "GenSigFirstTimeoutTime" BU_SG_REL_ CIOM SG_ 2566832401 TotalVehicleDistanceHighRes_ISig 24000;
BA_REL_ "GenSigTimeoutTime" BU_SG_REL_ CIOM SG_ 2566832401 TotalVehicleDistanceHighRes_ISig 6000;
BA_REL_ "GenSigFirstTimeoutTime" BU_SG_REL_ BBM SG_ 2566832401 TotalVehicleDistanceHighRes_ISig 24000;
BA_REL_ "GenSigTimeoutTime" BU_SG_REL_ BBM SG_ 2566832401 TotalVehicleDistanceHighRes_ISig 6000;
BA_REL_ "GenSigFirstTimeoutTime" BU_SG_REL_ VMCU SG_ 2566832622 TachoHighResTotalVehDistance 24000;
BA_REL_ "GenSigTimeoutTime" BU_SG_REL_ VMCU SG_ 2566832622 TachoHighResTotalVehDistance 6000;
BA_REL_ "GenSigFirstTimeoutTime" BU_SG_REL_ BBM SG_ 2566832407 HighResolutionTripDistance_ISig_ 24000;
BA_REL_ "GenSigTimeoutTime" BU_SG_REL_ BBM SG_ 2566832407 HighResolutionTripDistance_ISig_ 6000;
BA_REL_ "GenSigFirstTimeoutTime" BU_SG_REL_ IC3 SG_ 2364541195 LateralAcceleration_ISig_3 3000;
BA_REL_ "GenSigTimeoutTime" BU_SG_REL_ IC3 SG_ 2364541195 LateralAcceleration_ISig_3 120;
BA_REL_ "GenSigFirstTimeoutTime" BU_SG_REL_ BBM SG_ 2364541195 LateralAcceleration_ISig_3 3000;
BA_REL_ "GenSigTimeoutTime" BU_SG_REL_ BBM SG_ 2364541195 LateralAcceleration_ISig_3 60;
BA_REL_ "GenSigFirstTimeoutTime" BU_SG_REL_ DACU SG_ 2364541195 LateralAcceleration_ISig_3 3000;
BA_REL_ "GenSigTimeoutTime" BU_SG_REL_ DACU SG_ 2364541195 LateralAcceleration_ISig_3 600;
BA_REL_ "GenSigFirstTimeoutTime" BU_SG_REL_ CIOM SG_ 2364541195 SteeringWheelAngle_ISig_3 3000;
BA_REL_ "GenSigTimeoutTime" BU_SG_REL_ CIOM SG_ 2364541195 SteeringWheelAngle_ISig_3 60;
BA_REL_ "GenSigFirstTimeoutTime" BU_SG_REL_ BBM SG_ 2364541195 SteeringWheelAngle_ISig_3 3000;
BA_REL_ "GenSigTimeoutTime" BU_SG_REL_ BBM SG_ 2364541195 SteeringWheelAngle_ISig_3 120;
BA_REL_ "GenSigFirstTimeoutTime" BU_SG_REL_ IC3 SG_ 2364541195 SteeringWheelAngle_ISig_3 3000;
BA_REL_ "GenSigTimeoutTime" BU_SG_REL_ IC3 SG_ 2364541195 SteeringWheelAngle_ISig_3 120;
BA_REL_ "GenSigFirstTimeoutTime" BU_SG_REL_ VMCU SG_ 2364541195 SteeringWheelAngle_ISig_3 3000;
BA_REL_ "GenSigTimeoutTime" BU_SG_REL_ VMCU SG_ 2364541195 SteeringWheelAngle_ISig_3 120;
BA_REL_ "GenSigFirstTimeoutTime" BU_SG_REL_ DACU SG_ 2364541195 SteeringWheelAngle_ISig_3 3000;
BA_REL_ "GenSigTimeoutTime" BU_SG_REL_ DACU SG_ 2364541195 SteeringWheelAngle_ISig_3 120;
BA_REL_ "GenSigFirstTimeoutTime" BU_SG_REL_ BBM SG_ 2364541195 SteeringWheelTurnCounter_ISig_3 3000;
BA_REL_ "GenSigTimeoutTime" BU_SG_REL_ BBM SG_ 2364541195 SteeringWheelTurnCounter_ISig_3 120;
BA_REL_ "GenSigFirstTimeoutTime" BU_SG_REL_ BBM SG_ 2364541195 SteeringWheelAngleSensorType_ISi 3000;
BA_REL_ "GenSigTimeoutTime" BU_SG_REL_ BBM SG_ 2364541195 SteeringWheelAngleSensorType_ISi 120;
BA_REL_ "GenSigFirstTimeoutTime" BU_SG_REL_ IC3 SG_ 2364541195 YawRate_ISig_3 3000;
BA_REL_ "GenSigTimeoutTime" BU_SG_REL_ IC3 SG_ 2364541195 YawRate_ISig_3 120;
BA_REL_ "GenSigFirstTimeoutTime" BU_SG_REL_ TECU SG_ 2364541195 YawRate_ISig_3 3000;
BA_REL_ "GenSigTimeoutTime" BU_SG_REL_ TECU SG_ 2364541195 YawRate_ISig_3 60;
BA_REL_ "GenSigFirstTimeoutTime" BU_SG_REL_ BBM SG_ 2364541195 YawRate_ISig_3 3000;
BA_REL_ "GenSigTimeoutTime" BU_SG_REL_ BBM SG_ 2364541195 YawRate_ISig_3 60;
BA_REL_ "GenSigFirstTimeoutTime" BU_SG_REL_ DACU SG_ 2364541195 YawRate_ISig_3 3000;
BA_REL_ "GenSigTimeoutTime" BU_SG_REL_ DACU SG_ 2364541195 YawRate_ISig_3 120;
BA_REL_ "GenSigFirstTimeoutTime" BU_SG_REL_ IC3 SG_ 2566803211 ESCHealthStatus_ISig_3 3000;
BA_REL_ "GenSigTimeoutTime" BU_SG_REL_ IC3 SG_ 2566803211 ESCHealthStatus_ISig_3 600;
BA_REL_ "GenSigFirstTimeoutTime" BU_SG_REL_ BBM SG_ 2566803211 ESCHealthStatus_ISig_3 3000;
BA_REL_ "GenSigTimeoutTime" BU_SG_REL_ BBM SG_ 2566803211 ESCHealthStatus_ISig_3 600;
BA_REL_ "GenSigFirstTimeoutTime" BU_SG_REL_ VMCU SG_ 2566803211 ROPEngineControlActive_ISig_3 3000;
BA_REL_ "GenSigTimeoutTime" BU_SG_REL_ VMCU SG_ 2566803211 ROPEngineControlActive_ISig_3 600;
BA_REL_ "GenSigFirstTimeoutTime" BU_SG_REL_ IC3 SG_ 2566803211 ROPEngineControlActive_ISig_3 3000;
BA_REL_ "GenSigTimeoutTime" BU_SG_REL_ IC3 SG_ 2566803211 ROPEngineControlActive_ISig_3 600;
BA_REL_ "GenSigFirstTimeoutTime" BU_SG_REL_ BBM SG_ 2566803211 ROPEngineControlActive_ISig_3 3000;
BA_REL_ "GenSigTimeoutTime" BU_SG_REL_ BBM SG_ 2566803211 ROPEngineControlActive_ISig_3 600;
BA_REL_ "GenSigFirstTimeoutTime" BU_SG_REL_ TECU SG_ 2566803211 ROPEngineControlActive_ISig_3 3000;
BA_REL_ "GenSigTimeoutTime" BU_SG_REL_ TECU SG_ 2566803211 ROPEngineControlActive_ISig_3 600;
BA_REL_ "GenSigFirstTimeoutTime" BU_SG_REL_ IC3 SG_ 2566803211 YCEngineControlActive_ISig_3 3000;
BA_REL_ "GenSigTimeoutTime" BU_SG_REL_ IC3 SG_ 2566803211 YCEngineControlActive_ISig_3 600;
BA_REL_ "GenSigFirstTimeoutTime" BU_SG_REL_ VMCU SG_ 2566803211 YCEngineControlActive_ISig_3 3000;
BA_REL_ "GenSigTimeoutTime" BU_SG_REL_ VMCU SG_ 2566803211 YCEngineControlActive_ISig_3 600;
BA_REL_ "GenSigFirstTimeoutTime" BU_SG_REL_ BBM SG_ 2566803211 YCEngineControlActive_ISig_3 3000;
BA_REL_ "GenSigTimeoutTime" BU_SG_REL_ BBM SG_ 2566803211 YCEngineControlActive_ISig_3 600;
BA_REL_ "GenSigFirstTimeoutTime" BU_SG_REL_ TECU SG_ 2566803211 YCEngineControlActive_ISig_3 3000;
BA_REL_ "GenSigTimeoutTime" BU_SG_REL_ TECU SG_ 2566803211 YCEngineControlActive_ISig_3 600;
BA_REL_ "GenSigFirstTimeoutTime" BU_SG_REL_ TECU SG_ 2566803211 ROPBrakeControlActive_ISig_3 3000;
BA_REL_ "GenSigTimeoutTime" BU_SG_REL_ TECU SG_ 2566803211 ROPBrakeControlActive_ISig_3 600;
BA_REL_ "GenSigFirstTimeoutTime" BU_SG_REL_ VMCU SG_ 2566803211 ROPBrakeControlActive_ISig_3 3000;
BA_REL_ "GenSigTimeoutTime" BU_SG_REL_ VMCU SG_ 2566803211 ROPBrakeControlActive_ISig_3 600;
BA_REL_ "GenSigFirstTimeoutTime" BU_SG_REL_ CIOM SG_ 2566803211 ROPBrakeControlActive_ISig_3 3000;
BA_REL_ "GenSigTimeoutTime" BU_SG_REL_ CIOM SG_ 2566803211 ROPBrakeControlActive_ISig_3 600;
BA_REL_ "GenSigFirstTimeoutTime" BU_SG_REL_ DACU SG_ 2566803211 ROPBrakeControlActive_ISig_3 3000;
BA_REL_ "GenSigTimeoutTime" BU_SG_REL_ DACU SG_ 2566803211 ROPBrakeControlActive_ISig_3 600;
BA_REL_ "GenSigFirstTimeoutTime" BU_SG_REL_ BBM SG_ 2566803211 ROPBrakeControlActive_ISig_3 3000;
BA_REL_ "GenSigTimeoutTime" BU_SG_REL_ BBM SG_ 2566803211 ROPBrakeControlActive_ISig_3 600;
BA_REL_ "GenSigFirstTimeoutTime" BU_SG_REL_ IC3 SG_ 2566803211 ROPBrakeControlActive_ISig_3 3000;
BA_REL_ "GenSigTimeoutTime" BU_SG_REL_ IC3 SG_ 2566803211 ROPBrakeControlActive_ISig_3 600;
BA_REL_ "GenSigFirstTimeoutTime" BU_SG_REL_ IC3 SG_ 2566803211 YCBrakeControlActive_ISig_3 3000;
BA_REL_ "GenSigTimeoutTime" BU_SG_REL_ IC3 SG_ 2566803211 YCBrakeControlActive_ISig_3 600;
BA_REL_ "GenSigFirstTimeoutTime" BU_SG_REL_ DACU SG_ 2566803211 YCBrakeControlActive_ISig_3 3000;
BA_REL_ "GenSigTimeoutTime" BU_SG_REL_ DACU SG_ 2566803211 YCBrakeControlActive_ISig_3 600;
BA_REL_ "GenSigFirstTimeoutTime" BU_SG_REL_ BBM SG_ 2566803211 YCBrakeControlActive_ISig_3 3000;
BA_REL_ "GenSigTimeoutTime" BU_SG_REL_ BBM SG_ 2566803211 YCBrakeControlActive_ISig_3 600;
BA_REL_ "GenSigFirstTimeoutTime" BU_SG_REL_ TECU SG_ 2566803211 YCBrakeControlActive_ISig_3 3000;
BA_REL_ "GenSigTimeoutTime" BU_SG_REL_ TECU SG_ 2566803211 YCBrakeControlActive_ISig_3 600;
BA_REL_ "GenSigFirstTimeoutTime" BU_SG_REL_ VMCU SG_ 2566803211 YCBrakeControlActive_ISig_3 3000;
BA_REL_ "GenSigTimeoutTime" BU_SG_REL_ VMCU SG_ 2566803211 YCBrakeControlActive_ISig_3 600;
BA_REL_ "GenSigFirstTimeoutTime" BU_SG_REL_ CIOM SG_ 2566803211 YCBrakeControlActive_ISig_3 3000;
BA_REL_ "GenSigTimeoutTime" BU_SG_REL_ CIOM SG_ 2566803211 YCBrakeControlActive_ISig_3 600;
BA_REL_ "GenSigFirstTimeoutTime" BU_SG_REL_ BBM SG_ 2566803211 VDCFullyOperational_ISig_3 3000;
BA_REL_ "GenSigTimeoutTime" BU_SG_REL_ BBM SG_ 2566803211 VDCFullyOperational_ISig_3 600;
BA_REL_ "GenSigFirstTimeoutTime" BU_SG_REL_ DACU SG_ 2566803211 VDCFullyOperational_ISig_3 3000;
BA_REL_ "GenSigTimeoutTime" BU_SG_REL_ DACU SG_ 2566803211 VDCFullyOperational_ISig_3 600;
VAL_ 2349075203 XBRTECU_Priority 3 "Priority_LowPriority" 2 "Priority_MediumPriority" 1 "Priority_HighPriority" 0 "Priority_HighestPriority" ;
VAL_ 2349075203 XBRTECU_EBIMode 3 "XBREBIMode_NotDefined" 2 "XBREBIMode_EnduranceBrakeIntegrationAllowed" 1 "XBREBIMode_OnlyEnduranceBrakesAllowed" 0 "XBREBIMode_NoEnduranceBrakeIntegrationAllowed" ;
VAL_ 2349075203 XBRTECU_ControlMode 3 "XBRControlMode_NotDefined" 2 "XBRControlMode_AccelerationControlWithMaximumMode" 1 "XBRControlMode_AccelerationControlWithAdditionMode" 0 "XBRControlMode_OverrideDisabled" ;
VAL_ 2349075200 XBREMS_ControlMode 3 "XBRControlMode_NotDefined" 2 "XBRControlMode_AccelerationControlWithMaximumMode" 1 "XBRControlMode_AccelerationControlWithAdditionMode" 0 "XBRControlMode_OverrideDisabled" ;
VAL_ 2349075200 XBREMS_EBIMode 3 "XBREBIMode_NotDefined" 2 "XBREBIMode_EnduranceBrakeIntegrationAllowed" 1 "XBREBIMode_OnlyEnduranceBrakesAllowed" 0 "XBREBIMode_NoEnduranceBrakeIntegrationAllowed" ;
VAL_ 2349075200 XBREMS_Priority 3 "Priority_LowPriority" 2 "Priority_MediumPriority" 1 "Priority_HighPriority" 0 "Priority_HighestPriority" ;
VAL_ 2349075373 XBRDACU_EBIMode 3 "XBREBIMode_NotDefined" 2 "XBREBIMode_EnduranceBrakeIntegrationAllowed" 1 "XBREBIMode_OnlyEnduranceBrakesAllowed" 0 "XBREBIMode_NoEnduranceBrakeIntegrationAllowed" ;
VAL_ 2349075373 XBRDACU_ControlMode 3 "XBRControlMode_NotDefined" 2 "XBRControlMode_AccelerationControlWithMaximumMode" 1 "XBRControlMode_AccelerationControlWithAdditionMode" 0 "XBRControlMode_OverrideDisabled" ;
VAL_ 2349075373 XBRDACU_Priority 3 "Priority_LowPriority" 2 "Priority_MediumPriority" 1 "Priority_HighPriority" 0 "Priority_HighestPriority" ;
VAL_ 2349075430 XBRBBM_ControlMode 3 "XBRControlMode_NotDefined" 2 "XBRControlMode_AccelerationControlWithMaximumMode" 1 "XBRControlMode_AccelerationControlWithAdditionMode" 0 "XBRControlMode_OverrideDisabled" ;
VAL_ 2349075430 XBRBBM_Priority 3 "Priority_LowPriority" 2 "Priority_MediumPriority" 1 "Priority_HighPriority" 0 "Priority_HighestPriority" ;
VAL_ 2349075430 XBRBBM_EBIMode 3 "XBREBIMode_NotDefined" 2 "XBREBIMode_EnduranceBrakeIntegrationAllowed" 1 "XBREBIMode_OnlyEnduranceBrakesAllowed" 0 "XBREBIMode_NoEnduranceBrakeIntegrationAllowed" ;
VAL_ 2566848256 WaterInFuelAlarm_ISig_3 3 "NoYes_NotAvailable" 2 "NoYes_Error" 1 "NoYes_Yes" 0 "NoYes_No" ;
VAL_ 2583636718 Drvr2ManualEntryStatus 15 "DrvrManualEntryStatus_NotAvailable" 14 "DrvrManualEntryStatus_Error" 5 "DrvrManualEntryStatus_ManualEntryNotAllowed" 4 "DrvrManualEntryStatus_ManualEntryPossibleButInterrupted" 3 "DrvrManualEntryStatus_ManualEntryComplete" 2 "DrvrManualEntryStatus_ManualEntryOngoing" 1 "DrvrManualEntryStatus_TachoReadyButManualEntryNotStarted" 0 "DrvrManualEntryStatus_NoValidDriverCardInserted" ;
VAL_ 2583636718 CurrentFerryTrainStatus 1 "CurrentFerryTrainStatus_FerryTrainCrossingOpened" 0 "CurrentFerryTrainStatus_FerryTrainCrossingClosed" ;
VAL_ 2583636718 Drvr1ManualEntryStatus 15 "DrvrManualEntryStatus_NotAvailable" 14 "DrvrManualEntryStatus_Error" 5 "DrvrManualEntryStatus_ManualEntryNotAllowed" 4 "DrvrManualEntryStatus_ManualEntryPossibleButInterrupted" 3 "DrvrManualEntryStatus_ManualEntryComplete" 2 "DrvrManualEntryStatus_ManualEntryOngoing" 1 "DrvrManualEntryStatus_TachoReadyButManualEntryNotStarted" 0 "DrvrManualEntryStatus_NoValidDriverCardInserted" ;
VAL_ 2499788567 DrvrRetarderBrakeBlending_rqst_I 3 "OffOn_NotAvailable" 2 "OffOn_Error" 1 "OffOn_On" 0 "OffOn_Off" ;
VAL_ 2499788567 DrvrRetarderBrakeProgram_rqst_IS 3 "OffOn_NotAvailable" 2 "OffOn_Error" 1 "OffOn_On" 0 "OffOn_Off" ;
VAL_ 2499788567 GearLeverPositionBackup 15 "GearLeverPosition_NotAvailable" 14 "GearLeverPosition_Error" 13 "GearLeverPosition_SpareValue_06" 12 "GearLeverPosition_SpareValue_05" 11 "GearLeverPosition_SpareValue_04" 10 "GearLeverPosition_SpareValue_03" 9 "GearLeverPosition_SpareValue_02" 8 "GearLeverPosition_SpareValue_01" 7 "GearLeverPosition_SpareValue" 6 "GearLeverPosition_SEG6" 5 "GearLeverPosition_LowGear" 4 "GearLeverPosition_Manual" 3 "GearLeverPosition_Automatic" 2 "GearLeverPosition_Neutral" 1 "GearLeverPosition_Reverse" 0 "GearLeverPosition_GearFoldedAway" ;
VAL_ 2499788567 EHRearAxleSteeringFuncStatus 7 "FunctionStatus3bit_NotAvailable" 6 "FunctionStatus3bit_Error" 5 "FunctionStatus3bit_Spare3" 4 "FunctionStatus3bit_Spare2" 3 "FunctionStatus3bit_Spare1" 2 "FunctionStatus3bit_NotFunctional" 1 "FunctionStatus3bit_DegradedMode" 0 "FunctionStatus3bit_FullyFunctional" ;
VAL_ 2499788567 GearLeverPos2Backup_Rqst 15 "GearLeverPosition_NotAvailable" 14 "GearLeverPosition_Error" 13 "GearLeverPosition_SpareValue_06" 12 "GearLeverPosition_SpareValue_05" 11 "GearLeverPosition_SpareValue_04" 10 "GearLeverPosition_SpareValue_03" 9 "GearLeverPosition_SpareValue_02" 8 "GearLeverPosition_SpareValue_01" 7 "GearLeverPosition_SpareValue" 6 "GearLeverPosition_SEG6" 5 "GearLeverPosition_LowGear" 4 "GearLeverPosition_Manual" 3 "GearLeverPosition_Automatic" 2 "GearLeverPosition_Neutral" 1 "GearLeverPosition_Reverse" 0 "GearLeverPosition_GearFoldedAway" ;
VAL_ 2499788567 DriverRetarderRequest_ISig_3 7 "DriverRetarderRequest_NotAvailable" 6 "DriverRetarderRequest_Error" 5 "DriverRetarderRequest_Level5" 4 "DriverRetarderRequest_Level4" 3 "DriverRetarderRequest_Level3" 2 "DriverRetarderRequest_Level2" 1 "DriverRetarderRequest_Level1" 0 "DriverRetarderRequest_NoRequest" ;
VAL_ 2499788567 AirDumpStatus_ISig_3 7 "AirDumpStatus_NotAvailable" 6 "AirDumpStatus_Error" 5 "AirDumpStatus_Spare2" 4 "AirDumpStatus_Spare1" 3 "AirDumpStatus_Denied" 2 "AirDumpStatus_ActiveReached" 1 "AirDumpStatus_ActiveNotReached" 0 "AirDumpStatus_Inactive" ;
VAL_ 2566899729 LoadCalibFail_Range_ISig_3 3 "InactiveActiveSpare_NotAvailable" 2 "InactiveActiveSpare_Spare" 1 "InactiveActiveSpare_Active" 0 "InactiveActiveSpare_Inactive" ;
VAL_ 2566899729 LoadCalibFail_WrongVM_ISig_3 3 "InactiveActiveSpare_NotAvailable" 2 "InactiveActiveSpare_Spare" 1 "InactiveActiveSpare_Active" 0 "InactiveActiveSpare_Inactive" ;
VAL_ 2566899729 LoadCalibFail_InMotion_ISig_3 3 "InactiveActiveSpare_NotAvailable" 2 "InactiveActiveSpare_Spare" 1 "InactiveActiveSpare_Active" 0 "InactiveActiveSpare_Inactive" ;
VAL_ 2566899729 LoadCalibFail_InternalFailure_IS 3 "InactiveActiveSpare_NotAvailable" 2 "InactiveActiveSpare_Spare" 1 "InactiveActiveSpare_Active" 0 "InactiveActiveSpare_Inactive" ;
VAL_ 2566899729 LoadCalibFail_OutOfMemory_ISig_3 3 "InactiveActiveSpare_NotAvailable" 2 "InactiveActiveSpare_Spare" 1 "InactiveActiveSpare_Active" 0 "InactiveActiveSpare_Inactive" ;
VAL_ 2566899729 Trailer5CalibStoreReq_CalibType 3 "CalibType_TakeNoAction" 2 "CalibType_Spare" 1 "CalibType_StoreAxleLoadCalibrationUsingVehicleScaleSequence" 0 "CalibType_StoreAxleLoadCalibrationUsingIndividualAxleScale" ;
VAL_ 2566899729 LoadCalibrationFeedback_ISig_3 7 "LoadCalibrationFeedback_NotAvailable" 6 "LoadCalibrationFeedback_Spare3" 5 "LoadCalibrationFeedback_Spare2" 4 "LoadCalibrationFeedback_Spare1" 3 "LoadCalibrationFeedback_NOK" 2 "LoadCalibrationFeedback_OK" 1 "LoadCalibrationFeedback_InProgress" 0 "LoadCalibrationFeedback_NotRequested" ;
VAL_ 2566899729 LoadCalibFail_WrongHeight_ISig_3 3 "InactiveActiveSpare_NotAvailable" 2 "InactiveActiveSpare_Spare" 1 "InactiveActiveSpare_Active" 0 "InactiveActiveSpare_Inactive" ;
VAL_ 2566899473 Trailer3CalibStoreReq_CalibType 3 "CalibType_TakeNoAction" 2 "CalibType_Spare" 1 "CalibType_StoreAxleLoadCalibrationUsingVehicleScaleSequence" 0 "CalibType_StoreAxleLoadCalibrationUsingIndividualAxleScale" ;
VAL_ 2566899473 Trailer4CalibStoreReq_CalibType 3 "CalibType_TakeNoAction" 2 "CalibType_Spare" 1 "CalibType_StoreAxleLoadCalibrationUsingVehicleScaleSequence" 0 "CalibType_StoreAxleLoadCalibrationUsingIndividualAxleScale" ;
VAL_ 2566899217 Trailer1CalibStoreReq_CalibType 3 "CalibType_TakeNoAction" 2 "CalibType_Spare" 1 "CalibType_StoreAxleLoadCalibrationUsingVehicleScaleSequence" 0 "CalibType_StoreAxleLoadCalibrationUsingIndividualAxleScale" ;
VAL_ 2566899217 Trailer2CalibStoreReq_CalibType 3 "CalibType_TakeNoAction" 2 "CalibType_Spare" 1 "CalibType_StoreAxleLoadCalibrationUsingVehicleScaleSequence" 0 "CalibType_StoreAxleLoadCalibrationUsingIndividualAxleScale" ;
VAL_ 2499751697 RearAxle2DiffLock_stat_ISig_3 3 "OffOn_NotAvailable" 2 "OffOn_Error" 1 "OffOn_On" 0 "OffOn_Off" ;
VAL_ 2499751697 EngineStopReqBackup 3 "Request_NotAvailable" 2 "Request_Error" 1 "Request_RequestActive" 0 "Request_NotRequested" ;
VAL_ 2499751697 DifferentialLockStateCentral_ISi 3 "DisengageEngage_NotAvailable" 2 "DisengageEngage_Error" 1 "DisengageEngage_Engage" 0 "DisengageEngage_Disengage" ;
VAL_ 2499751697 RrInterAxlDiffLockActvnFuncReq_I 3 "DisengagedEngaged_NotAvailable" 2 "DisengagedEngaged_Error" 1 "DisengagedEngaged_Engaged" 0 "DisengagedEngaged_Disengaged" ;
VAL_ 2499751697 RearPropulsionStat_Rear1Axle_ISi 15 "AxlePropulsionStatus_NotAvailable" 14 "AxlePropulsionStatus_Error" 13 "AxlePropulsionStatus_Spare6" 12 "AxlePropulsionStatus_Spare5" 11 "AxlePropulsionStatus_Spare4" 10 "AxlePropulsionStatus_Spare3" 9 "AxlePropulsionStatus_Spare2" 8 "AxlePropulsionStatus_Spare1" 7 "AxlePropulsionStatus_LoweredInterAxleStatusUnknown" 6 "AxlePropulsionStatus_LiftedInterAxleStatusUnknown" 5 "AxlePropulsionStatus_PositionUnknownDriven" 4 "AxlePropulsionStatus_PositionUnknownNonDriven" 3 "AxlePropulsionStatus_LoweredDifferentialLocked" 2 "AxlePropulsionStatus_LoweredDriven" 1 "AxlePropulsionStatus_LoweredNonDriven" 0 "AxlePropulsionStatus_LiftedNonDriven" ;
VAL_ 2499751697 SetHSAOperation 7 "SetHSAOperation_NotAvailable" 6 "SetHSAOperation_Error" 5 "SetHSAOperation_Spare2" 4 "SetHSAOperation_Spare1" 3 "SetHSAOperation_Forbid_HSA_WithCaution" 2 "SetHSAOperation_Forbid_HSA_Activation" 1 "SetHSAOperation_Allow_HSA_WithCaution" 0 "SetHSAOperation_Allow_HSA_Activation" ;
VAL_ 2499751697 CentralRearDiffLock_stat_ISig_3 3 "DisengageEngage_NotAvailable" 2 "DisengageEngage_Error" 1 "DisengageEngage_Engage" 0 "DisengageEngage_Disengage" ;
VAL_ 2499751697 AutoPBRelease_stat_ISig_3 3 "AutoPBRelease_stat_NotAvailable" 2 "AutoPBRelease_stat_Error" 1 "AutoPBRelease_stat_FunctionInhibited" 0 "AutoPBRelease_stat_FunctionAvailable" ;
VAL_ 2499751697 RearAxle3DiffLock_stat_ISig_3 3 "OffOn_NotAvailable" 2 "OffOn_Error" 1 "OffOn_On" 0 "OffOn_Off" ;
VAL_ 2499751697 DifferentialLockStateCentral2 3 "DisengagedEngaged_NotAvailable" 2 "DisengagedEngaged_Error" 1 "DisengagedEngaged_Engaged" 0 "DisengagedEngaged_Disengaged" ;
VAL_ 2499751697 LowAirPressureAlert 3 "LowAirPressureAlert_NotAvailable" 2 "LowAirPressureAlert_Error" 1 "LowAirPressureAlert_LowPressure" 0 "LowAirPressureAlert_NormalPressure" ;
VAL_ 2499751697 RearPropulsionStat_Rear3Axle_ISi 15 "AxlePropulsionStatus_NotAvailable" 14 "AxlePropulsionStatus_Error" 13 "AxlePropulsionStatus_Spare6" 12 "AxlePropulsionStatus_Spare5" 11 "AxlePropulsionStatus_Spare4" 10 "AxlePropulsionStatus_Spare3" 9 "AxlePropulsionStatus_Spare2" 8 "AxlePropulsionStatus_Spare1" 7 "AxlePropulsionStatus_LoweredInterAxleStatusUnknown" 6 "AxlePropulsionStatus_LiftedInterAxleStatusUnknown" 5 "AxlePropulsionStatus_PositionUnknownDriven" 4 "AxlePropulsionStatus_PositionUnknownNonDriven" 3 "AxlePropulsionStatus_LoweredDifferentialLocked" 2 "AxlePropulsionStatus_LoweredDriven" 1 "AxlePropulsionStatus_LoweredNonDriven" 0 "AxlePropulsionStatus_LiftedNonDriven" ;
VAL_ 2499751697 DifferentialLockStateFrAxle2 3 "DisengagedEngaged_NotAvailable" 2 "DisengagedEngaged_Error" 1 "DisengagedEngaged_Engaged" 0 "DisengagedEngaged_Disengaged" ;
VAL_ 2499751697 TrailerConnected_ISig_3 3 "NoYes_NotAvailable" 2 "NoYes_Error" 1 "NoYes_Yes" 0 "NoYes_No" ;
VAL_ 2499751697 TrailerWithoutABS_ISig_3 3 "TrailerWithoutABS_NotAvailableOrNotInstalled" 2 "TrailerWithoutABS_ErrorIndicator" 1 "TrailerWithoutABS_YesTrailerWithoutABS" 0 "TrailerWithoutABS_NoNoTrailerPresentOraTrailerWithABS" ;
VAL_ 2499751697 DifferentialLockStateFrAxle1_ISi 3 "DisengageEngage_NotAvailable" 2 "DisengageEngage_Error" 1 "DisengageEngage_Engage" 0 "DisengageEngage_Disengage" ;
VAL_ 2499751697 RearPropulsionStat_Rear2Axle_ISi 15 "AxlePropulsionStatus_NotAvailable" 14 "AxlePropulsionStatus_Error" 13 "AxlePropulsionStatus_Spare6" 12 "AxlePropulsionStatus_Spare5" 11 "AxlePropulsionStatus_Spare4" 10 "AxlePropulsionStatus_Spare3" 9 "AxlePropulsionStatus_Spare2" 8 "AxlePropulsionStatus_Spare1" 7 "AxlePropulsionStatus_LoweredInterAxleStatusUnknown" 6 "AxlePropulsionStatus_LiftedInterAxleStatusUnknown" 5 "AxlePropulsionStatus_PositionUnknownDriven" 4 "AxlePropulsionStatus_PositionUnknownNonDriven" 3 "AxlePropulsionStatus_LoweredDifferentialLocked" 2 "AxlePropulsionStatus_LoweredDriven" 1 "AxlePropulsionStatus_LoweredNonDriven" 0 "AxlePropulsionStatus_LiftedNonDriven" ;
VAL_ 2499751697 RearAxle1DiffLock_stat_ISig_3 3 "OffOn_NotAvailable" 2 "OffOn_Error" 1 "OffOn_On" 0 "OffOn_Off" ;
VAL_ 2499751697 HeadlampFan_stat_ISig_3 7 "LampFanTestStat_NotAvailable" 6 "LampFanTestStat_Error" 5 "LampFanTestStat_Spare3" 4 "LampFanTestStat_Spare2" 3 "LampFanTestStat_Spare1" 2 "LampFanTestStat_FanTestedNOK" 1 "LampFanTestStat_FanTestedOK" 0 "LampFanTestStat_NotTested" ;
VAL_ 2566897425 StretchBrakeEnable_rqst 7 "StretchBrakeEnable_rqst_NotAvailable" 6 "StretchBrakeEnable_rqst_Error" 5 "StretchBrakeEnable_rqst_Spare_2" 4 "StretchBrakeEnable_rqst_Spare_1" 3 "StretchBrakeEnable_rqst_Enable_PulseLevel3" 2 "StretchBrakeEnable_rqst_Enable_PulseLevel2" 1 "StretchBrakeEnable_rqst_Enable_PulseLevel1" 0 "StretchBrakeEnable_rqst_Disabled" ;
VAL_ 2566897425 ExhManifAirInjectionInhibit_ISig 3 "InhibitedStatus_NotAvailable" 2 "InhibitedStatus_Error" 1 "InhibitedStatus_Inhibited" 0 "InhibitedStatus_NotInhibited" ;
VAL_ 2566897425 StaticTrailerBrake_rqst 3 "DeactivateActivate_NotAvailable" 2 "DeactivateActivate_Error" 1 "DeactivateActivate_Activate" 0 "DeactivateActivate_Deactivate" ;
VAL_ 2566897425 AxleLoadStatus 7 "AxleLoadStatus_NotAvailable" 6 "AxleLoadStatus_Error" 5 "AxleLoadStatus_Spare2" 4 "AxleLoadStatus_Spare1" 3 "AxleLoadStatus_Overload" 2 "AxleLoadStatus_HighLoad2" 1 "AxleLoadStatus_HighLoad1" 0 "AxleLoadStatus_NormalLoad" ;
VAL_ 2298429457 SWBrakeSwitch_ISig_3 3 "BrakeSwitch_NotAvailable" 2 "BrakeSwitch_Error" 1 "BrakeSwitch_BrakePedalDepressed" 0 "BrakeSwitch_BrakePedalReleased" ;
VAL_ 2298429457 VehicleMode_ISig_3 15 "VehicleMode_NotAvailable" 14 "VehicleMode_Error" 13 "VehicleMode_Spare_7" 12 "VehicleMode_Spare_6" 11 "VehicleMode_Spare_5" 10 "VehicleMode_Spare_4" 9 "VehicleMode_Spare_3" 8 "VehicleMode_Spare_2" 7 "VehicleMode_Spare_1" 6 "VehicleMode_Running" 5 "VehicleMode_Cranking" 4 "VehicleMode_PreRunning" 3 "VehicleMode_Accessory" 2 "VehicleMode_Living" 1 "VehicleMode_Parked" 0 "VehicleMode_Hibernate" ;
VAL_ 2298429457 AcctrPedalKickDownSw_stat_ISig_3 3 "PassiveActive_NotAvailable" 2 "PassiveActive_Error" 1 "PassiveActive_Active" 0 "PassiveActive_Passive" ;
VAL_ 2298429457 AcceleratorPedalLowIdleSwitch_IS 3 "AcceleratorPedalLowIdleSwitch_NotAvailable" 2 "AcceleratorPedalLowIdleSwitch_Error" 1 "AcceleratorPedalLowIdleSwitch_INLowIdleCondition" 0 "AcceleratorPedalLowIdleSwitch_NotInLowIdleCondition" ;
VAL_ 2566849262 DetectReducWeeklyRestsForCurWk_I 15 "DetectReducWeeklyRestsForCurWk_NotAvailable" 14 "DetectReducWeeklyRestsForCurWk_Error" 13 "DetectReducWeeklyRestsForCurWk_Spare4" 12 "DetectReducWeeklyRestsForCurWk_Spare3" 11 "DetectReducWeeklyRestsForCurWk_Spare2" 10 "DetectReducWeeklyRestsForCurWk_Spare1" 9 "DetectReducWeeklyRestsForCurWk_Spare" 8 "DetectReducWeeklyRestsForCurWk_8AsgndReducWeeklyRests" 7 "DetectReducWeeklyRestsForCurWk_7AsgndReducWeeklyRests" 6 "DetectReducWeeklyRestsForCurWk_6AsgndReducWeeklyRests" 5 "DetectReducWeeklyRestsForCurWk_5AsgndReducWeeklyRests" 4 "DetectReducWeeklyRestsForCurWk_4AsgndReducWeeklyRests" 3 "DetectReducWeeklyRestsForCurWk_3AsgndReducWeeklyRests" 2 "DetectReducWeeklyRestsForCurWk_2AsgndReducWeeklyRests" 1 "DetectReducWeeklyRestsForCurWk_1AsgndReducWeeklyRests" 0 "DetectReducWeeklyRestsForCurWk_0AsgndReducWeeklyRests" ;
VAL_ 2566849262 DetectRegWeeklyRestsForCurWk_ISi 15 "DetectRegWeeklyRestsForCurWk_NotAvailable" 14 "DetectRegWeeklyRestsForCurWk_Error" 13 "DetectRegWeeklyRestsForCurWk_Spare7" 12 "DetectRegWeeklyRestsForCurWk_Spare6" 11 "DetectRegWeeklyRestsForCurWk_Spare5" 10 "DetectRegWeeklyRestsForCurWk_Spare4" 9 "DetectRegWeeklyRestsForCurWk_Spare3" 8 "DetectRegWeeklyRestsForCurWk_Spare2" 7 "DetectRegWeeklyRestsForCurWk_Spare1" 6 "DetectRegWeeklyRestsForCurWk_Spare" 5 "DetectRegWeeklyRestsForCurWk_5AssignedRegWeeklyRests" 4 "DetectRegWeeklyRestsForCurWk_4AssignedRegWeeklyRests" 3 "DetectRegWeeklyRestsForCurWk_3AssignedRegWeeklyRests" 2 "DetectRegWeeklyRestsForCurWk_2AssignedRegWeeklyRests" 1 "DetectRegWeeklyRestsForCurWk_1AssignedRegWeeklyRests" 0 "DetectRegWeeklyRestsForCurWk_0AssignedRegWeeklyRests" ;
VAL_ 2566849262 DetectReducWeeklyRestsForLastW_I 15 "DetectReducWeeklyRestsForLastW_NotAvailable" 14 "DetectReducWeeklyRestsForLastW_Error" 13 "DetectReducWeeklyRestsForLastW_Spare4" 12 "DetectReducWeeklyRestsForLastW_Spare3" 11 "DetectReducWeeklyRestsForLastW_Spare2" 10 "DetectReducWeeklyRestsForLastW_Spare1" 9 "DetectReducWeeklyRestsForLastW_Spare" 8 "DetectReducWeeklyRestsForLastW_8AsgndReducWeeklyRests" 7 "DetectReducWeeklyRestsForLastW_7AsgndReducWeeklyRests" 6 "DetectReducWeeklyRestsForLastW_6AsgndReducWeeklyRests" 5 "DetectReducWeeklyRestsForLastW_5AsgndReducWeeklyRests" 4 "DetectReducWeeklyRestsForLastW_4AsgndReducWeeklyRests" 3 "DetectReducWeeklyRestsForLastW_3AsgndReducWeeklyRests" 2 "DetectReducWeeklyRestsForLastW_2AsgndReducWeeklyRests" 1 "DetectReducWeeklyRestsForLastW_1AsgndReducWeeklyRests" 0 "DetectReducWeeklyRestsForLastW_0AsgndReducWeeklyRests" ;
VAL_ 2566849262 DetectRegWeeklyRestsForLastW_ISi 15 "DetectRegWeeklyRestsForLastW_NotAvailable" 14 "DetectRegWeeklyRestsForLastW_Error" 13 "DetectRegWeeklyRestsForLastW_Spare7" 12 "DetectRegWeeklyRestsForLastW_Spare6" 11 "DetectRegWeeklyRestsForLastW_Spare5" 10 "DetectRegWeeklyRestsForLastW_Spare4" 9 "DetectRegWeeklyRestsForLastW_Spare3" 8 "DetectRegWeeklyRestsForLastW_Spare2" 7 "DetectRegWeeklyRestsForLastW_Spare1" 6 "DetectRegWeeklyRestsForLastW_Spare" 5 "DetectRegWeeklyRestsForLastW_5AssignedRegWeeklyRests" 4 "DetectRegWeeklyRestsForLastW_4AssignedRegWeeklyRests" 3 "DetectRegWeeklyRestsForLastW_3AssignedRegWeeklyRests" 2 "DetectRegWeeklyRestsForLastW_2AssignedRegWeeklyRests" 1 "DetectRegWeeklyRestsForLastW_1AssignedRegWeeklyRests" 0 "DetectRegWeeklyRestsForLastW_0AssignedRegWeeklyRests" ;
VAL_ 2566906094 SingleMultiDriver_ISig_3 3 "SingleMultiDriver_NotAvailable" 2 "SingleMultiDriver_Error" 1 "SingleMultiDriver_MultiManningForCurrentShiftDetected" 0 "SingleMultiDriver_SingleDriverForCurrentShiftDetected" ;
VAL_ 2566906094 UnknownPeriods_ISig_3 3 "UnknownPeriods_NotAvailable" 2 "UnknownPeriods_Error" 1 "UnknownPeriods_AtLeastOneUnknownPeriod" 0 "UnknownPeriods_NoUNKNOWNPeriods" ;
VAL_ 2566906094 RemainingReducedDailyRestPrd_ISi 7 "RemainingReducedDailyRestPrd_NotAvailable" 6 "RemainingReducedDailyRestPrd_Error" 5 "RemainingReducedDailyRestPrd_Spare_02" 4 "RemainingReducedDailyRestPrd_Spare_01" 3 "RemainingReducedDailyRestPrd_3RemainingReducedDailyRestPeriods" 2 "RemainingReducedDailyRestPrd_2RemainingReducedDailyRestPeriods" 1 "RemainingReducedDailyRestPrd_1RemainingReducedDailyRestPeriods" 0 "RemainingReducedDailyRestPrd_0RemainingReducedDailyRestPeriods" ;
VAL_ 2566906094 TimeOverlap_ISig_3 3 "TimeOverlap_NotAvailable" 2 "TimeOverlap_Error" 1 "TimeOverlap_TimeOverlapDetected" 0 "TimeOverlap_NoTimeOverlapInTheDataSet" ;
VAL_ 2566906094 WklyRestPrdCalcEnabledDisabled_I 3 "DisableEnable_NotAvailable" 2 "DisableEnable_Error" 1 "DisableEnable_Enable" 0 "DisableEnable_Disable" ;
VAL_ 2566906094 Remaining10hDrvTime_ISig_3 7 "Remaining10hDrvTime_NotAvailable" 6 "Remaining10hDrvTime_Error" 5 "Remaining10hDrvTime_Spare_03" 4 "Remaining10hDrvTime_Spare_02" 3 "Remaining10hDrvTime_Spare_01" 2 "Remaining10hDrvTime_2Remaining10hDrivingTimes" 1 "Remaining10hDrvTime_1Remaining10hDrivingTimes" 0 "Remaining10hDrvTime_0Remaining10hDrivingTimes" ;
VAL_ 2566906094 SufficientData_ISig_3 3 "SufficientData_NotAvailable" 2 "SufficientData_Error" 1 "SufficientData_NoSufficientDataOnTheDriverCard" 0 "SufficientData_SufficientDataOnDriverCardAvailable" ;
VAL_ 2566849006 TypeOfNextBreakRest_ISig_3 63 "TypeOfNextBreakRest_NotAvailable" 62 "TypeOfNextBreakRest_Error" 61 "TypeOfNextBreakRest_Spare53" 60 "TypeOfNextBreakRest_Spare52" 59 "TypeOfNextBreakRest_Spare51" 58 "TypeOfNextBreakRest_Spare50" 57 "TypeOfNextBreakRest_Spare49" 56 "TypeOfNextBreakRest_Spare48" 55 "TypeOfNextBreakRest_Spare47" 54 "TypeOfNextBreakRest_Spare46" 53 "TypeOfNextBreakRest_Spare45" 52 "TypeOfNextBreakRest_Spare44" 51 "TypeOfNextBreakRest_Spare43" 50 "TypeOfNextBreakRest_Spare42" 49 "TypeOfNextBreakRest_Spare41" 48 "TypeOfNextBreakRest_Spare40" 47 "TypeOfNextBreakRest_Spare39" 46 "TypeOfNextBreakRest_Spare38" 45 "TypeOfNextBreakRest_Spare37" 44 "TypeOfNextBreakRest_Spare36" 43 "TypeOfNextBreakRest_Spare35" 42 "TypeOfNextBreakRest_Spare34" 41 "TypeOfNextBreakRest_Spare33" 40 "TypeOfNextBreakRest_Spare32" 39 "TypeOfNextBreakRest_Spare31" 38 "TypeOfNextBreakRest_Spare30" 37 "TypeOfNextBreakRest_Spare29" 36 "TypeOfNextBreakRest_Spare28" 35 "TypeOfNextBreakRest_Spare27" 34 "TypeOfNextBreakRest_RegularWeeklyRestPeriod" 33 "TypeOfNextBreakRest_ReducedWeeklyRestPeriod" 32 "TypeOfNextBreakRest_Spare26" 31 "TypeOfNextBreakRest_Spare25" 30 "TypeOfNextBreakRest_Spare24" 29 "TypeOfNextBreakRest_Spare23" 28 "TypeOfNextBreakRest_Spare22" 27 "TypeOfNextBreakRest_Spare21" 26 "TypeOfNextBreakRest_Spare20" 25 "TypeOfNextBreakRest_Spare19" 24 "TypeOfNextBreakRest_Spare18" 23 "TypeOfNextBreakRest_Spare17" 22 "TypeOfNextBreakRest_Spare16" 21 "TypeOfNextBreakRest_Spare15" 20 "TypeOfNextBreakRest_MultiManningDRP" 19 "TypeOfNextBreakRest_SplitRegularDRP2ndPart" 18 "TypeOfNextBreakRest_RegularDailyRestPeriod" 17 "TypeOfNextBreakRest_ReducedDailyRestPeriod" 16 "TypeOfNextBreakRest_Spare14" 15 "TypeOfNextBreakRest_Spare13" 14 "TypeOfNextBreakRest_Spare12" 13 "TypeOfNextBreakRest_Spare11" 12 "TypeOfNextBreakRest_Spare10" 11 "TypeOfNextBreakRest_Spare9" 10 "TypeOfNextBreakRest_Spare8" 9 "TypeOfNextBreakRest_Spare7" 8 "TypeOfNextBreakRest_Spare6" 7 "TypeOfNextBreakRest_Spare5" 6 "TypeOfNextBreakRest_Spare4" 5 "TypeOfNextBreakRest_Spare3" 4 "TypeOfNextBreakRest_Spare2" 3 "TypeOfNextBreakRest_Spare1" 2 "TypeOfNextBreakRest_DrivingInterruption30min" 1 "TypeOfNextBreakRest_DrivingInterruption45min" 0 "TypeOfNextBreakRest_Spare" ;
VAL_ 2566849006 CompensationinNextRestPrd_ISig_3 3 "CompNextRestPrd_NotAvailable" 2 "CompNextRestPrd_Error" 1 "CompNextRestPrd_NRPisExtendedByCompensation" 0 "CompNextRestPrd_NRPNotExtendedByCompensation" ;
VAL_ 2364541195 SteeringWheelAngleSensorType_ISi 3 "SteeringWheelAngleSensorType_NotAvailable" 2 "SteeringWheelAngleSensorType_Reserved" 1 "SteeringWheelAngleSensorType_AbsoluteMeasuringPrinciple" 0 "SteeringWheelAngleSensorType_RelativeMeasuringPrinciple" ;
VAL_ 2566803211 ESCHealthStatus_ISig_3 3 "OffOnSpare_NotAvailable" 2 "OffOnSpare_Spare" 1 "OffOnSpare_On" 0 "OffOnSpare_Off" ;
VAL_ 2566803211 ROPEngineControlActive_ISig_3 3 "PassiveActive2_DontCareTakeNoAction" 2 "PassiveActive2_Reserved" 1 "PassiveActive2_Active" 0 "PassiveActive2_PassiveButInstalled" ;
VAL_ 2566803211 YCEngineControlActive_ISig_3 3 "PassiveActive2_DontCareTakeNoAction" 2 "PassiveActive2_Reserved" 1 "PassiveActive2_Active" 0 "PassiveActive2_PassiveButInstalled" ;
VAL_ 2566803211 ROPBrakeControlActive_ISig_3 3 "PassiveActive2_DontCareTakeNoAction" 2 "PassiveActive2_Reserved" 1 "PassiveActive2_Active" 0 "PassiveActive2_PassiveButInstalled" ;
VAL_ 2566803211 YCBrakeControlActive_ISig_3 3 "PassiveActive2_DontCareTakeNoAction" 2 "PassiveActive2_Reserved" 1 "PassiveActive2_Active" 0 "PassiveActive2_PassiveButInstalled" ;
VAL_ 2566803211 VDCFullyOperational_ISig_3 3 "FullyOperational_NotAvailable" 2 "FullyOperational_Reserved" 1 "FullyOperational_FullyOperational" 0 "FullyOperational_NotFullyOperational" ;
SIG_GROUP_ 2349075203 XBRTECU_sg 1 : XBRTECU_Priority XBRTECU_MsgChecksum XBRTECU_EBIMode XBRTECU_Urgency XBRTECU_ControlMode XBRTECU_ExtAccelDemand XBRTECU_MsgCounter;
SIG_GROUP_ 2349075200 XBREMS_sg 1 : XBREMS_ControlMode XBREMS_MsgCounter XBREMS_Urgency XBREMS_EBIMode XBREMS_ExtAccelDemand XBREMS_Priority XBREMS_MsgChecksum;
SIG_GROUP_ 2349075373 XBRDACU_sg 1 : XBRDACU_Urgency XBRDACU_EBIMode XBRDACU_ExtAccelDemand XBRDACU_MsgCounter XBRDACU_MsgChecksum XBRDACU_ControlMode XBRDACU_Priority;
SIG_GROUP_ 2349075430 XBRBBM_sg 1 : XBRBBM_Urgency XBRBBM_ControlMode XBRBBM_Priority XBRBBM_MsgCounter XBRBBM_MsgChecksum XBRBBM_EBIMode XBRBBM_ExtAccelDemand;
SIG_GROUP_ 2566845201 VehiclePosSAE_sg 1 : VehiclePosSAE_Longitude VehiclePosSAE_Latitude;
SIG_GROUP_ 2566845422 VehPos1_sg 1 : VehPos1_Latitude VehPos1_Longitude;
SIG_GROUP_ 2499788567 GearLeverPos2Backup_sg 1 : GearLeverPos2Backup_Rqst GearLeverPos2Backup_SqC GearLeverPos2Backup_CRC;
SIG_GROUP_ 2566899729 LoadCalibFail_sg_ISig_3 1 : LoadCalibFail_Range_ISig_3 LoadCalibFail_WrongVM_ISig_3 LoadCalibFail_InMotion_ISig_3 LoadCalibFail_InternalFailure_IS LoadCalibFail_OutOfMemory_ISig_3 LoadCalibFail_WrongHeight_ISig_3;
SIG_GROUP_ 2566899729 Trailer5CalibStoreReq_sg 1 : Trailer5CalibStoreReq_CalibType Trailer5CalibStoreReq_AxleId Trailer5CalibStoreReq_ScaleLoad;
SIG_GROUP_ 2566899473 Trailer3CalibStoreReq_sg 1 : Trailer3CalibStoreReq_ScaleLoad Trailer3CalibStoreReq_CalibType Trailer3CalibStoreReq_AxleId;
SIG_GROUP_ 2566899473 Trailer4CalibStoreReq_sg 1 : Trailer4CalibStoreReq_AxleId Trailer4CalibStoreReq_ScaleLoad Trailer4CalibStoreReq_CalibType;
SIG_GROUP_ 2566899217 Trailer2CalibStoreReq_sg 1 : Trailer2CalibStoreReq_AxleId Trailer2CalibStoreReq_CalibType Trailer2CalibStoreReq_ScaleLoad;
SIG_GROUP_ 2566899217 Trailer1CalibStoreReq_sg 1 : Trailer1CalibStoreReq_ScaleLoad Trailer1CalibStoreReq_CalibType Trailer1CalibStoreReq_AxleId;
SIG_GROUP_ 2499751697 RearPropulsionStat_sg_ISig_3 1 : RearPropulsionStat_Rear1Axle_ISi RearPropulsionStat_Rear3Axle_ISi RearPropulsionStat_Rear2Axle_ISi;
SIG_GROUP_ 2566842385 VehicleDirSAE_sg 1 : VehicleDirSAE_VehSpeed VehicleDirSAE_Altitude VehicleDirSAE_Bearing VehicleDirSAE_Pitch;
SIG_GROUP_ 2566842606 VehDirSpd_sg 1 : VehDirSpd_Altitude VehDirSpd_VehSpeed VehDirSpd_Bearing VehDirSpd_Pitch;
